VERSION ""

NS_ :

BS_:

BU_: WCM4 WCM3 WCM2 WCM VPM VLM VKM VICM VECM VDM VCU_RTOS_ETH VCU_ENTRY_ETH VCU_AGVM_ETH VCU UVM UPM TIM TEST_TOOL_1 TCP_ETH TCP TCM TCCM SRR_SRR_ETH SRR_SRR SRR_SLR_ETH SRR_SLR SRR_RR SRR_RF_ETH SRR_RF SRR_LR_CR SRR_LF_ETH SRR_LF SIB SDM SCL SBZA_R SBZA_L SBM SAM_RR SAM_RF SAM_LR SAM_LF SAM_BH SADS RadioLow_ETH RadioLow RSI_RTOS_ETH RSI RDCM PTM PLCM PFCM PDR_ETH PDR PCM PA ODS2 ODS NVM MTCM_R MTCM_L MSM_RR MSM_P MSM_LR MSM_D MSB2 MSB1 MRCM_R MRCM_L MFC LRR_RR_ETH LRR_LR_ETH LRR_CF_ETH LRR LRL_CF_ETH LIB_48V LIB1 IPC_INT IPC_GP IPC ICS_Info ICCM HVAC_FP_R HVAC_FP_F HUD_CAN HDLM FPI_RTOS_ETH FPI FOPM FCM_LC FCM EPSb EPS_1 EPSRAb EPSRAa EPS EOCM_HC_Superset EOCM_HCP2 EOCM ELM ECP_X1 ECP_S2 ECP_S ECP_MC ECP_H3 ECP_H2 ECP_H1 ECP_E ECM EBCM DMS DEFC DCM CSM_ETH CSM_AV CSM CGM_OTA_ETH CGM BSM_MH BSM_HEV BSM BCM ARS ARB APA AOS AMP ALC AHS AHL_AFL ADIMb ADIMa ACP2_MCU

BO_ 1432 PDU_5206: 8 HVAC_FP_F
 SG_ HVACFCRTLR_LtLvlActv : 0|1@0+ (1,0) [0|1] "" Vector__XXX
 SG_ HVACFCRTLR_LtLvl : 7|7@0+ (1,-16) [-16|111] "" Vector__XXX
 SG_ HVACFCRTLR_RtLvl : 12|7@0+ (1,-16) [-16|111] "" Vector__XXX
 SG_ HVACFCRTLR_LtLvlChg : 15|3@0- (1,0) [-4|3] "" Vector__XXX
 SG_ HVACFCRTLR_RwVltg1 : 17|9@0+ (0.01,0) [0|5.11] "Volts" Vector__XXX
 SG_ HVACFCRTLR_RtLvlChg : 20|3@0- (1,0) [-4|3] "" Vector__XXX
 SG_ HVACFCRTLR_RtLvlActv : 21|1@0+ (1,0) [0|1] "" Vector__XXX
 SG_ HVACFCRTLR_RwVltg2 : 24|9@0+ (0.01,0) [0|5.11] "Volts" Vector__XXX
 SG_ HVACFCRL_RwVltg : 47|9@0+ (0.01,0) [0|5.11] "Volts" Vector__XXX
 SG_ RHVSLF_VntLvlChgUp : 48|1@0+ (1,0) [0|1] "" Vector__XXX
 SG_ RHVSLF_VntLvlChgDn : 49|1@0+ (1,0) [0|1] "" Vector__XXX
 SG_ RHVSLF_HtdCushBckLvlChgUp : 50|1@0+ (1,0) [0|1] "" Vector__XXX
 SG_ RHVSLF_HtdCushBckLvlChgDn : 51|1@0+ (1,0) [0|1] "" Vector__XXX
 SG_ RHVSLF_HtdBckLvlChgUp : 52|1@0+ (1,0) [0|1] "" Vector__XXX
 SG_ RHVSLF_HtdBckLvlChgDn : 53|1@0+ (1,0) [0|1] "" Vector__XXX
 SG_ HVACFCRL_SetChg : 54|1@0+ (1,0) [0|1] "" Vector__XXX
 SG_ VntStStckSwRF : 57|1@0+ (1,0) [0|1] "" Vector__XXX
 SG_ RHVSRF_VntLvlChgUp : 58|1@0+ (1,0) [0|1] "" Vector__XXX
 SG_ RHVSRF_VntLvlChgDn : 59|1@0+ (1,0) [0|1] "" Vector__XXX
 SG_ RHVSRF_HtdCushBckLvlChgUp : 60|1@0+ (1,0) [0|1] "" Vector__XXX
 SG_ RHVSRF_HtdCushBckLvlChgDn : 61|1@0+ (1,0) [0|1] "" Vector__XXX
 SG_ RHVSRF_HtdBckLvlChgUp : 62|1@0+ (1,0) [0|1] "" Vector__XXX
 SG_ RHVSRF_HtdBckLvlChgDn : 63|1@0+ (1,0) [0|1] "" Vector__XXX

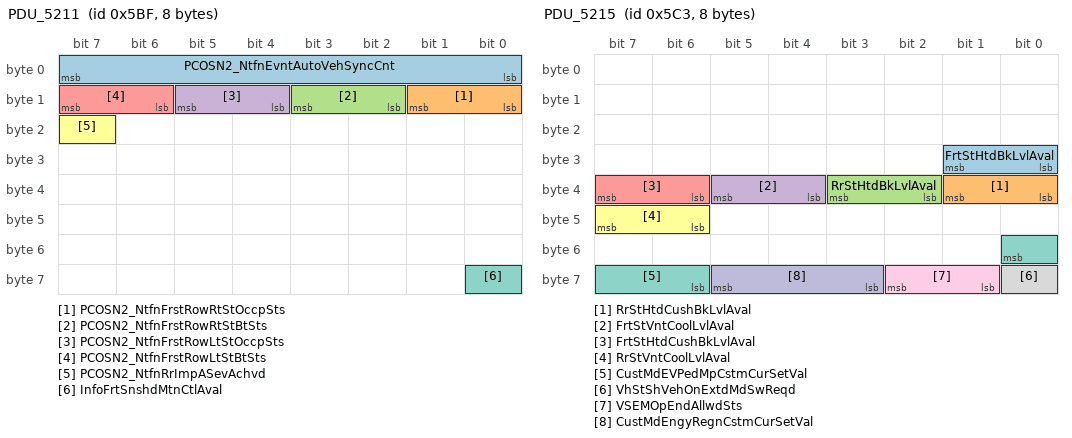
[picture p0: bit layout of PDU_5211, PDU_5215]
BO_ 1471 PDU_5211: 8 CGM
 SG_ PCOSN2_NtfnEvntAutoVehSyncCnt : 7|8@0+ (1,0) [0|255] "counts" TCP
 SG_ PCOSN2_NtfnFrstRowRtStOccpSts : 9|2@0+ (1,0) [0|3] "" TCP
 SG_ PCOSN2_NtfnFrstRowRtStBtSts : 11|2@0+ (1,0) [0|3] "" TCP
 SG_ PCOSN2_NtfnFrstRowLtStOccpSts : 13|2@0+ (1,0) [0|3] "" TCP
 SG_ PCOSN2_NtfnFrstRowLtStBtSts : 15|2@0+ (1,0) [0|3] "" TCP
 SG_ PCOSN2_NtfnRrImpASevAchvd : 23|1@0+ (1,0) [0|1] "" TCP
 SG_ InfoFrtSnshdMtnCtlAval : 56|1@0+ (1,0) [0|1] "" VCU

BO_ 1472 PDU_5212: 8 CGM
 SG_ CustMdEVPedMpCstmAvFlg1 : 56|1@0+ (1,0) [0|1] "" CSM,CSM_AV,VCU

BO_ 1474 PDU_5214: 8 CGM
 SG_ CustMdEVPedMpCstmAvFlg2 : 56|1@0+ (1,0) [0|1] "" CSM,CSM_AV,VCU

BO_ 1475 PDU_5215: 8 CGM
 SG_ FrtStHtdBkLvlAval : 25|2@0+ (1,0) [0|3] "" CSM,CSM_AV,VCU
 SG_ RrStHtdCushBkLvlAval : 33|2@0+ (1,0) [0|3] "" CSM,CSM_AV,VCU
 SG_ RrStHtdBkLvlAval : 35|2@0+ (1,0) [0|3] "" CSM,CSM_AV,VCU
 SG_ FrtStVntCoolLvlAval : 37|2@0+ (1,0) [0|3] "" CSM,CSM_AV,VCU
 SG_ FrtStHtdCushBkLvlAval : 39|2@0+ (1,0) [0|3] "" CSM,CSM_AV,VCU
 SG_ RrStVntCoolLvlAval : 47|2@0+ (1,0) [0|3] "" CSM,CSM_AV,VCU
 SG_ CustMdEVPedMpCstmCurSetVal : 48|3@0+ (1,0) [0|7] "" CSM,CSM_AV,VCU
 SG_ VhStShVehOnExtdMdSwReqd : 56|1@0+ (1,0) [0|1] "" VCU
 SG_ VSEMOpEndAllwdSts : 58|2@0+ (1,0) [0|2] "" VCU
 SG_ CustMdEngyRegnCstmCurSetVal : 61|3@0+ (1,0) [0|7] "" CSM,CSM_AV,VCU

BO_ 1476 PDU_5216: 8 CGM
 SG_ OffRdMdElecVehPedMpVisDispVal : 1|3@0+ (1,0) [0|7] "" CSM,CSM_AV,VCU
 SG_ PrsnlMdEngyRegnCstmCurSetVal : 8|3@0+ (1,0) [0|7] "" CSM,CSM_AV,VCU
 SG_ PrsnlMdEVPedMpCstmCurSetVal : 11|3@0+ (1,0) [0|7] "" CSM,CSM_AV,VCU
 SG_ OffRdMdEngyRegnVisDispVal : 14|3@0+ (1,0) [0|7] "" CSM,CSM_AV,VCU
 SG_ SprtMdEngyRegnVisDispVal : 18|3@0+ (1,0) [0|7] "" CSM,CSM_AV,VCU
 SG_ SprtMdElecVehPedMpVisDispVal : 21|3@0+ (1,0) [0|7] "" CSM,CSM_AV,VCU
 SG_ TourMdElecVehPedMpVisDispVal : 25|3@0+ (1,0) [0|7] "" CSM,CSM_AV,VCU
 SG_ TkMdEngyRegnVisDispVal : 28|3@0+ (1,0) [0|7] "" CSM,CSM_AV,VCU
 SG_ TkMdElecVehPedMpVisDispVal : 31|3@0+ (1,0) [0|7] "" CSM,CSM_AV,VCU
 SG_ TrnMdBrkPedVisDispVal : 32|3@0+ (1,0) [0|7] "" CSM,CSM_AV,VCU
 SG_ TrnMdActvAerodynsVisDispVal : 35|3@0+ (1,0) [0|7] "" CSM,CSM_AV,VCU
 SG_ TourMdEngyRegnVisDispVal : 38|3@0+ (1,0) [0|7] "" CSM,CSM_AV,VCU
 SG_ TrnMdESCVisDispVal : 42|3@0+ (1,0) [0|7] "" CSM,CSM_AV,VCU
 SG_ TrnMdDrvlnVisDispVal : 45|3@0+ (1,0) [0|7] "" CSM,CSM_AV,VCU
 SG_ TrnMdPwrtrnVisDispVal : 49|3@0+ (1,0) [0|7] "" CSM,CSM_AV,VCU
 SG_ TrnMdEngyRegnVisDispVal : 52|3@0+ (1,0) [0|7] "" CSM,CSM_AV,VCU
 SG_ TrnMdElecVehPedMpVisDispVal : 55|3@0+ (1,0) [0|7] "" CSM,CSM_AV,VCU
 SG_ CustMdEVPedMpCstmAvFlg3 : 56|1@0+ (1,0) [0|1] "" CSM,CSM_AV,VCU
 SG_ TrnMdSndVisDispVal : 59|3@0+ (1,0) [0|7] "" CSM,CSM_AV,VCU
 SG_ TrnMdRideHghtVisDispVal : 62|3@0+ (1,0) [0|7] "" CSM,CSM_AV,VCU

BO_ 1477 PDU_5217: 8 CGM
 SG_ TrnMdStrgVisDispVal : 4|3@0+ (1,0) [0|7] "" CSM,CSM_AV,VCU
 SG_ TrnMdSpnsnVisDispVal : 7|3@0+ (1,0) [0|7] "" CSM,CSM_AV,VCU
 SG_ WthrMdEngyRegnVisDispVal : 11|3@0+ (1,0) [0|7] "" CSM,CSM_AV,VCU
 SG_ WthrMdElecVehPedMpVisDispVal : 14|3@0+ (1,0) [0|7] "" CSM,CSM_AV,VCU
 SG_ CustMdEVPedMpCstmAvFlg4 : 16|1@0+ (1,0) [0|1] "" CSM,CSM_AV,VCU
 SG_ HtdStrgWhlLvlAval : 22|2@0+ (1,0) [0|3] "" CSM,CSM_AV,VCU
 SG_ CustMdEngyRegnCstmAvFlg4 : 24|1@0+ (1,0) [0|1] "" CSM,CSM_AV,VCU
 SG_ CustMdEngyRegnCstmAvFlg3 : 25|1@0+ (1,0) [0|1] "" CSM,CSM_AV,VCU
 SG_ CustMdEngyRegnCstmAvFlg2 : 26|1@0+ (1,0) [0|1] "" CSM,CSM_AV,VCU
 SG_ CustMdEngyRegnCstmAvFlg1 : 27|1@0+ (1,0) [0|1] "" CSM,CSM_AV,VCU
 SG_ CustMdEVPedMpCstmSetAv : 28|1@0+ (1,0) [0|1] "" CSM,CSM_AV,VCU
 SG_ CustMdEVPedMpCstmAvFlg7 : 29|1@0+ (1,0) [0|1] "" CSM,CSM_AV,VCU
 SG_ CustMdEVPedMpCstmAvFlg6 : 30|1@0+ (1,0) [0|1] "" CSM,CSM_AV,VCU
 SG_ CustMdEVPedMpCstmAvFlg5 : 31|1@0+ (1,0) [0|1] "" CSM,CSM_AV,VCU
 SG_ OnePedDrvCstSetAllwdFlg3 : 32|1@0+ (1,0) [0|1] "" CSM,CSM_AV,VCU
 SG_ OnePedDrvCstSetAllwdFlg2 : 33|1@0+ (1,0) [0|1] "" CSM,CSM_AV,VCU
 SG_ OnePedDrvCstSetAllwdFlg1 : 34|1@0+ (1,0) [0|1] "" CSM,CSM_AV,VCU
 SG_ CustMdEngyRegnCstmSetAv : 36|1@0+ (1,0) [0|1] "" CSM,CSM_AV,VCU
 SG_ CustMdEngyRegnCstmAvFlg7 : 37|1@0+ (1,0) [0|1] "" CSM,CSM_AV,VCU
 SG_ CustMdEngyRegnCstmAvFlg6 : 38|1@0+ (1,0) [0|1] "" CSM,CSM_AV,VCU
 SG_ CustMdEngyRegnCstmAvFlg5 : 39|1@0+ (1,0) [0|1] "" CSM,CSM_AV,VCU
 SG_ OnePedDrvCstSetAvlFlg3 : 40|1@0+ (1,0) [0|1] "" CSM,CSM_AV,VCU
 SG_ OnePedDrvCstSetAvlFlg2 : 41|1@0+ (1,0) [0|1] "" CSM,CSM_AV,VCU
 SG_ OnePedDrvCstSetAvlFlg1 : 42|1@0+ (1,0) [0|1] "" CSM,CSM_AV,VCU
 SG_ OnePedDrvCstSetAval : 43|1@0+ (1,0) [0|1] "" CSM,CSM_AV,VCU
 SG_ OnePedDrvCstSetAllwdFlg7 : 44|1@0+ (1,0) [0|1] "" CSM,CSM_AV,VCU
 SG_ OnePedDrvCstSetAllwdFlg6 : 45|1@0+ (1,0) [0|1] "" CSM,CSM_AV,VCU
 SG_ OnePedDrvCstSetAllwdFlg5 : 46|1@0+ (1,0) [0|1] "" CSM,CSM_AV,VCU
 SG_ OnePedDrvCstSetAllwdFlg4 : 47|1@0+ (1,0) [0|1] "" CSM,CSM_AV,VCU
 SG_ PrsnlMdEVPedMpCstmAvFlg3 : 48|1@0+ (1,0) [0|1] "" CSM,CSM_AV,VCU
 SG_ PrsnlMdEVPedMpCstmAvFlg2 : 49|1@0+ (1,0) [0|1] "" CSM,CSM_AV,VCU
 SG_ PrsnlMdEVPedMpCstmAvFlg1 : 50|1@0+ (1,0) [0|1] "" CSM,CSM_AV,VCU
 SG_ OnePedDrvCstSetAvlFlg7 : 52|1@0+ (1,0) [0|1] "" CSM,CSM_AV,VCU
 SG_ OnePedDrvCstSetAvlFlg6 : 53|1@0+ (1,0) [0|1] "" CSM,CSM_AV,VCU
 SG_ OnePedDrvCstSetAvlFlg5 : 54|1@0+ (1,0) [0|1] "" CSM,CSM_AV,VCU
 SG_ OnePedDrvCstSetAvlFlg4 : 55|1@0+ (1,0) [0|1] "" CSM,CSM_AV,VCU
 SG_ PrsnlMdEngyRegnCstmAvFlg3 : 56|1@0+ (1,0) [0|1] "" CSM,CSM_AV,VCU
 SG_ PrsnlMdEngyRegnCstmAvFlg2 : 57|1@0+ (1,0) [0|1] "" CSM,CSM_AV,VCU
 SG_ PrsnlMdEngyRegnCstmAvFlg1 : 58|1@0+ (1,0) [0|1] "" CSM,CSM_AV,VCU
 SG_ PrsnlMdEVPedMpCstmSetAv : 59|1@0+ (1,0) [0|1] "" CSM,CSM_AV,VCU
 SG_ PrsnlMdEVPedMpCstmAvFlg7 : 60|1@0+ (1,0) [0|1] "" CSM,CSM_AV,VCU
 SG_ PrsnlMdEVPedMpCstmAvFlg6 : 61|1@0+ (1,0) [0|1] "" CSM,CSM_AV,VCU
 SG_ PrsnlMdEVPedMpCstmAvFlg5 : 62|1@0+ (1,0) [0|1] "" CSM,CSM_AV,VCU
 SG_ PrsnlMdEVPedMpCstmAvFlg4 : 63|1@0+ (1,0) [0|1] "" CSM,CSM_AV,VCU

BO_ 1496 PDU_5218: 6 CGM
 SG_ PwrFrtStrgeCmptClsrCstAvlFlg2 : 0|1@0+ (1,0) [0|1] "" RadioLow,CSM,CSM_AV,VCU
 SG_ PwrFrtStrgeCmptClsrCstAvlFlg1 : 1|1@0+ (1,0) [0|1] "" RadioLow,CSM,CSM_AV,VCU
 SG_ PrsnlMdEngyRegnCstmSetAv : 3|1@0+ (1,0) [0|1] "" CSM,CSM_AV,VCU
 SG_ PrsnlMdEngyRegnCstmAvFlg7 : 4|1@0+ (1,0) [0|1] "" CSM,CSM_AV,VCU
 SG_ PrsnlMdEngyRegnCstmAvFlg6 : 5|1@0+ (1,0) [0|1] "" CSM,CSM_AV,VCU
 SG_ PrsnlMdEngyRegnCstmAvFlg5 : 6|1@0+ (1,0) [0|1] "" CSM,CSM_AV,VCU
 SG_ PrsnlMdEngyRegnCstmAvFlg4 : 7|1@0+ (1,0) [0|1] "" CSM,CSM_AV,VCU
 SG_ VirtCtlAccCktCtlAval : 8|1@0+ (1,0) [0|1] "" CSM,CSM_AV,VCU
 SG_ PwrFrtStrgeCmptClsrCstSetAval : 10|1@0+ (1,0) [0|1] "" RadioLow,CSM,CSM_AV,VCU
 SG_ PwrFrtStrgeCmptClsrCstAvlFlg7 : 11|1@0+ (1,0) [0|1] "" RadioLow,CSM,CSM_AV,VCU
 SG_ PwrFrtStrgeCmptClsrCstAvlFlg6 : 12|1@0+ (1,0) [0|1] "" RadioLow,CSM,CSM_AV,VCU
 SG_ PwrFrtStrgeCmptClsrCstAvlFlg5 : 13|1@0+ (1,0) [0|1] "" RadioLow,CSM,CSM_AV,VCU
 SG_ PwrFrtStrgeCmptClsrCstAvlFlg4 : 14|1@0+ (1,0) [0|1] "" RadioLow,CSM,CSM_AV,VCU
 SG_ PwrFrtStrgeCmptClsrCstAvlFlg3 : 15|1@0+ (1,0) [0|1] "" RadioLow,CSM,CSM_AV,VCU
 SG_ VirtOnePedDrvUserCtlAllwd : 21|1@0+ (1,0) [0|1] "" CSM,CSM_AV,VCU
 SG_ VirtOnePedDrvCtlAval : 22|1@0+ (1,0) [0|1] "" CSM,CSM_AV,VCU
 SG_ VirtCtlAuxAlrmSnsCtlAval : 23|1@0+ (1,0) [0|1] "" CSM,VCU
 SG_ HdOpnShftrLckdHldBrkTmVal : 31|6@0+ (1,0) [0|63] "s" IPC,IPC_INT,VCU

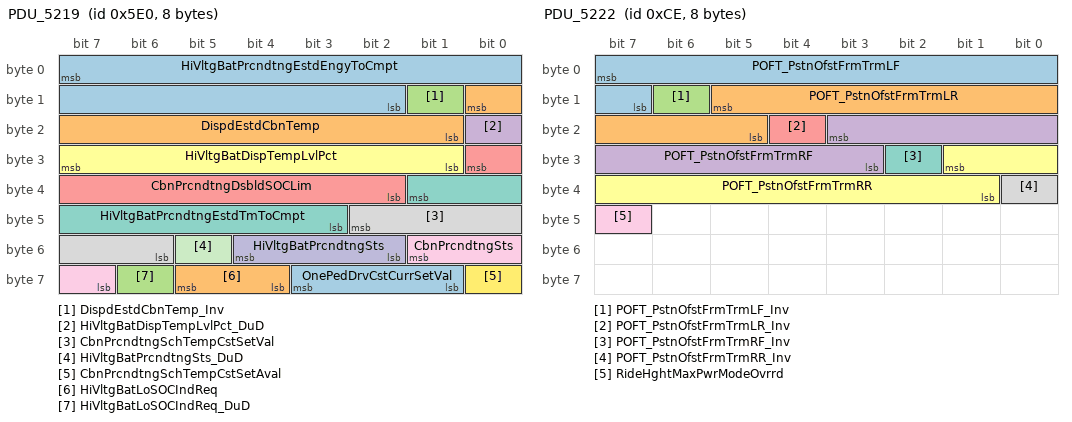
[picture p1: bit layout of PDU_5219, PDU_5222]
BO_ 1504 PDU_5219: 8 CGM
 SG_ HiVltgBatPrcndtngEstdEngyToCmpt : 7|14@0+ (0.01,0) [0|163.83] "kWh" CSM,CSM_AV,VCU
 SG_ DispdEstdCbnTemp : 8|8@0+ (0.5,-40) [-40|87.5] "Deg C" TCP,VCU
 SG_ DispdEstdCbnTemp_Inv : 9|1@0+ (1,0) [0|1] "" TCP,VCU
 SG_ HiVltgBatDispTempLvlPct_DuD : 16|1@0+ (1,0) [0|1] "" CSM,CSM_AV,IPC,IPC_INT,VCU
 SG_ CbnPrcndtngDsbldSOCLim : 24|7@0+ (1,0) [0|127] "%" CSM,CSM_AV,VCU
 SG_ HiVltgBatDispTempLvlPct : 31|7@0+ (1,0) [0|127] "%" CSM,CSM_AV,IPC,IPC_INT,VCU
 SG_ HiVltgBatPrcndtngEstdTmToCmpt : 33|7@0+ (1,0) [0|127] "min" CSM,CSM_AV,VCU
 SG_ CbnPrcndtngSchTempCstSetVal : 42|5@0+ (0.5,16) [16|31.5] "Deg C" CSM,CSM_AV,VCU
 SG_ CbnPrcndtngSts : 49|3@0+ (1,0) [0|5] "" TCP,VKM
 SG_ HiVltgBatPrcndtngSts : 52|3@0+ (1,0) [0|5] "" TCP,CSM,CSM_AV,VCU
 SG_ HiVltgBatPrcndtngSts_DuD : 53|1@0+ (1,0) [0|1] "" TCP,CSM,CSM_AV,VCU
 SG_ CbnPrcndtngSchTempCstSetAval : 56|1@0+ (1,0) [0|1] "" CSM,CSM_AV,VCU
 SG_ OnePedDrvCstCurrSetVal : 59|3@0+ (1,0) [0|4] "" CSM,CSM_AV,VCU
 SG_ HiVltgBatLoSOCIndReq : 61|2@0+ (1,0) [0|3] "" TCP
 SG_ HiVltgBatLoSOCIndReq_DuD : 62|1@0+ (1,0) [0|1] "" TCP

BO_ 1505 PDU_5220: 6 CGM
 SG_ OnePedDrvCurrSeltnVal : 0|2@0+ (1,0) [0|2] "" CSM,CSM_AV,VCU
 SG_ FrtStrgeCmptClsrLckSts : 2|2@0+ (1,0) [0|2] "" TCP
 SG_ AuxAlrmSnsCurrSeltnVal : 4|2@0+ (1,0) [0|2] "" CSM,VCU
 SG_ PwrFrtStrgeCmptClsrCstCurSetVal : 7|3@0+ (1,0) [0|3] "" RadioLow,VKM,CSM,CSM_AV,VCU
 SG_ VirtCtlAccCkt3CurrSeltnVal : 8|2@0+ (1,0) [0|3] "" CSM,CSM_AV,VCU
 SG_ VirtCtlAccCkt2CurrSeltnVal : 10|2@0+ (1,0) [0|3] "" CSM,CSM_AV,VCU
 SG_ VirtCtlAccCkt1CurrSeltnVal : 12|2@0+ (1,0) [0|3] "" CSM,CSM_AV,VCU
 SG_ OnePedDrvWrnIndReq : 14|2@0+ (1,0) [0|1] "" IPC,IPC_INT,VCU
 SG_ HVDCFstChrgPerfLtdIndOn : 16|1@0+ (1,0) [0|1] "" CSM,CSM_AV,VCU
 SG_ VirtCtlAccCkt6CurrSeltnVal : 18|2@0+ (1,0) [0|3] "" CSM,CSM_AV,VCU
 SG_ VirtCtlAccCkt5CurrSeltnVal : 20|2@0+ (1,0) [0|3] "" CSM,CSM_AV,VCU
 SG_ VirtCtlAccCkt4CurrSeltnVal : 22|2@0+ (1,0) [0|3] "" CSM,CSM_AV,VCU
 SG_ LnchCtlBrkPresHiResVal : 29|7@0+ (1,0) [0|127] "%" IPC,IPC_INT,VCU
 SG_ OnePedDrvIndOn : 30|1@0+ (1,0) [0|1] "" IPC,IPC_INT,VCU
 SG_ HVDCFstChrgPrepCmpltIndOn : 31|1@0+ (1,0) [0|1] "" CSM,CSM_AV,VCU
 SG_ ADASLtdCpbltyStatRsnIndReq : 35|5@0+ (1,0) [0|11] "" IPC,IPC_INT,VCU
 SG_ PrplSysMaxPwrModeUnvRsn : 38|3@0+ (1,0) [0|7] "" IPC,IPC_INT,VCU
 SG_ ADASMsgDispLocLtdPerfRsnInd : 42|3@0+ (1,0) [0|3] "" IPC,IPC_INT,VCU
 SG_ ADASLtdCpbltyStatIndReq : 46|4@0+ (1,0) [0|6] "" IPC,IPC_INT,VCU

BO_ 929 PDU_5221: 6 CGM
 SG_ B2RChmEvntStat : 7|2@0+ (1,0) [0|2] "" IPC,IPC_INT,VCU

BO_ 206 PDU_5222: 8 CGM
 SG_ POFT_PstnOfstFrmTrmLF : 7|9@0- (1,0) [-256|255] "mm" PDR,CSM,CSM_AV,IPC,IPC_INT,VCU
 SG_ POFT_PstnOfstFrmTrmLR : 13|9@0- (1,0) [-256|255] "mm" PDR,CSM,CSM_AV,IPC,IPC_INT,VCU
 SG_ POFT_PstnOfstFrmTrmLF_Inv : 14|1@0+ (1,0) [0|1] "" CSM,CSM_AV,IPC,IPC_INT,VCU
 SG_ POFT_PstnOfstFrmTrmRF : 19|9@0- (1,0) [-256|255] "mm" PDR,CSM,CSM_AV,IPC,IPC_INT,VCU
 SG_ POFT_PstnOfstFrmTrmLR_Inv : 20|1@0+ (1,0) [0|1] "" CSM,CSM_AV,IPC,IPC_INT,VCU
 SG_ POFT_PstnOfstFrmTrmRR : 25|9@0- (1,0) [-256|255] "mm" PDR,CSM,CSM_AV,IPC,IPC_INT,VCU
 SG_ POFT_PstnOfstFrmTrmRF_Inv : 26|1@0+ (1,0) [0|1] "" CSM,CSM_AV,IPC,IPC_INT,VCU
 SG_ POFT_PstnOfstFrmTrmRR_Inv : 32|1@0+ (1,0) [0|1] "" CSM,CSM_AV,IPC,IPC_INT,VCU
 SG_ RideHghtMaxPwrModeOvrrd : 47|1@0+ (1,0) [0|1] "" IPC,IPC_INT,VCU

BO_ 1535 PDU_5223: 6 RadioLow
 SG_ PwrFrtStrgeCmptClsrCstChgSetReq : 7|3@0+ (1,0) [0|3] "" CGM

BO_ 1246 PDU_5224: 8 CSM
 SG_ ElecRateSchedSsnStrtMthReq : 0|4@0+ (1,0) [0|12] "" CGM
 SG_ ElecRateSchedSsnStrtDyReq : 5|5@0+ (1,0) [0|31] "day" CGM
 SG_ ElecRateSchedSsnReq : 7|2@0+ (1,0) [0|3] "" CGM
 SG_ InfoFrtLtStHtdCushBkLvlReq : 9|3@0+ (1,0) [0|5] "" CGM
 SG_ InfoFrtLtStHtdBkLvlReq : 12|3@0+ (1,0) [0|5] "" CGM
 SG_ InfoFrtRtStHtdCushBkLvlReq : 16|3@0+ (1,0) [0|5] "" CGM
 SG_ InfoFrtRtStHtdBkLvlReq : 19|3@0+ (1,0) [0|5] "" CGM
 SG_ InfoFrtLtStVntCoolLvlReq : 22|3@0+ (1,0) [0|5] "" CGM
 SG_ InfoRrLtStHtdBkLvlReq : 26|3@0+ (1,0) [0|5] "" CGM
 SG_ InfoFrtRtStVntCoolLvlReq : 29|3@0+ (1,0) [0|5] "" CGM
 SG_ InfoRrRtStHtdBkLvlReq : 33|3@0+ (1,0) [0|5] "" CGM
 SG_ InfoRrLtStVntCoolLvlReq : 36|3@0+ (1,0) [0|5] "" CGM
 SG_ InfoRrLtStHtdCushBkLvlReq : 39|3@0+ (1,0) [0|5] "" CGM
 SG_ CbnPrcndtngSchTempCstSetReq : 40|5@0+ (0.5,16) [16|31.5] "Deg C" CGM
 SG_ InfoRrRtStVntCoolLvlReq : 43|3@0+ (1,0) [0|5] "" CGM
 SG_ InfoRrRtStHtdCushBkLvlReq : 46|3@0+ (1,0) [0|5] "" CGM
 SG_ OnePedDrvCstChgSetReq : 48|3@0+ (1,0) [0|4] "" CGM
 SG_ InfoHtdStrgWhlLvlReq : 51|3@0+ (1,0) [0|5] "" CGM
 SG_ VirtCtlAccCkt2Req : 58|3@0+ (1,0) [0|5] "" CGM
 SG_ VirtCtlAccCkt1Req : 61|3@0+ (1,0) [0|5] "" CGM

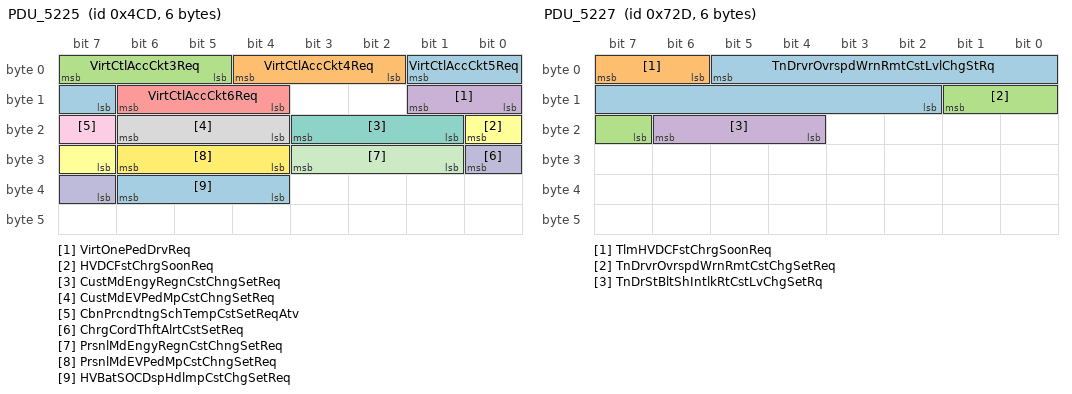
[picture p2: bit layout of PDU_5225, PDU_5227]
BO_ 1229 PDU_5225: 6 CSM
 SG_ VirtCtlAccCkt5Req : 1|3@0+ (1,0) [0|5] "" CGM
 SG_ VirtCtlAccCkt4Req : 4|3@0+ (1,0) [0|5] "" CGM
 SG_ VirtCtlAccCkt3Req : 7|3@0+ (1,0) [0|5] "" CGM
 SG_ VirtOnePedDrvReq : 9|2@0+ (1,0) [0|2] "" CGM
 SG_ VirtCtlAccCkt6Req : 14|3@0+ (1,0) [0|5] "" CGM
 SG_ HVDCFstChrgSoonReq : 16|2@0+ (1,0) [0|2] "" CGM
 SG_ CustMdEngyRegnCstChngSetReq : 19|3@0+ (1,0) [0|7] "" CGM
 SG_ CustMdEVPedMpCstChngSetReq : 22|3@0+ (1,0) [0|7] "" CGM
 SG_ CbnPrcndtngSchTempCstSetReqAtv : 23|1@0+ (1,0) [0|1] "" CGM
 SG_ ChrgCordThftAlrtCstSetReq : 24|2@0+ (1,0) [0|2] "" CGM
 SG_ PrsnlMdEngyRegnCstChngSetReq : 27|3@0+ (1,0) [0|7] "" CGM
 SG_ PrsnlMdEVPedMpCstChngSetReq : 30|3@0+ (1,0) [0|7] "" CGM
 SG_ HVBatSOCDspHdlmpCstChgSetReq : 38|3@0+ (1,0) [0|2] "" CGM

BO_ 931 PDU_5226: 6 TCP
 SG_ RmtVehStrtPwrtrnFlrRsn : 2|5@0+ (1,0) [0|16] "" VKM
 SG_ RmtVehStrtBdyFlrRsn : 7|5@0+ (1,0) [0|14] "" VKM

BO_ 1837 PDU_5227: 6 TCP
 SG_ TnDrvrOvrspdWrnRmtCstLvlChgStRq : 5|12@0+ (0.0625,0) [0|255.938] "km/h" CGM
 SG_ TlmHVDCFstChrgSoonReq : 7|2@0+ (1,0) [0|2] "" CGM
 SG_ TnDrvrOvrspdWrnRmtCstChgSetReq : 9|3@0+ (1,0) [0|2] "" CGM
 SG_ TnDrStBltShIntlkRtCstLvChgSetRq : 22|3@0+ (1,0) [0|2] "" CGM

BO_ 940 PDU_5230: 6 VKM
 SG_ VirtKeyCmdFailRsnReq : 7|2@0+ (1,0) [0|1] "" TCP

BO_ 1467 PDU_5238: 6 TCP
 SG_ SuprCruzSbscrptnActv : 7|1@0+ (1,0) [0|1] "" CGM

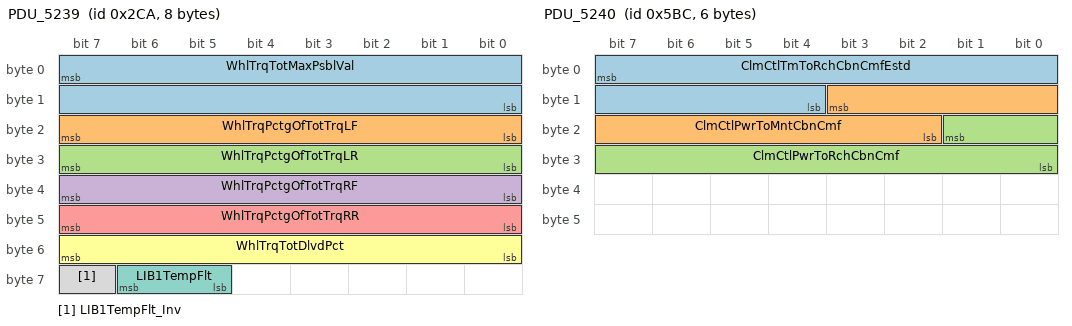
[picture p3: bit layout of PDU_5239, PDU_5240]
BO_ 714 PDU_5239: 8 CGM
 SG_ WhlTrqTotMaxPsblVal : 7|16@0+ (1,0) [0|65535] "Nm" IPC,IPC_INT,VCU
 SG_ WhlTrqPctgOfTotTrqLF : 23|8@0- (0.788235,0) [-100.894|100.106] "%" CSM,CSM_AV,VCU
 SG_ WhlTrqPctgOfTotTrqLR : 31|8@0- (0.788235,0) [-100.894|100.106] "%" CSM,CSM_AV,VCU
 SG_ WhlTrqPctgOfTotTrqRF : 39|8@0- (0.788235,0) [-100.894|100.106] "%" CSM,CSM_AV,VCU
 SG_ WhlTrqPctgOfTotTrqRR : 47|8@0- (0.788235,0) [-100.894|100.106] "%" CSM,CSM_AV,VCU
 SG_ WhlTrqTotDlvdPct : 55|8@0- (0.788235,0) [-100.894|100.106] "%" CSM,CSM_AV,IPC,IPC_INT,VCU
 SG_ LIB1TempFlt : 62|2@0+ (1,0) [0|3] "" CSM,VCU
 SG_ LIB1TempFlt_Inv : 63|1@0+ (1,0) [0|1] "" CSM,VCU

BO_ 1468 PDU_5240: 6 CGM
 SG_ ClmCtlTmToRchCbnCmfEstd : 7|12@0+ (1,0) [0|4095] "sec" CSM,CSM_AV,VCU
 SG_ ClmCtlPwrToMntCbnCmf : 11|10@0+ (0.1,0) [0|102.3] "KW" CSM,CSM_AV,VCU
 SG_ ClmCtlPwrToRchCbnCmf : 17|10@0+ (0.1,0) [0|102.3] "KW" CSM,CSM_AV,VCU

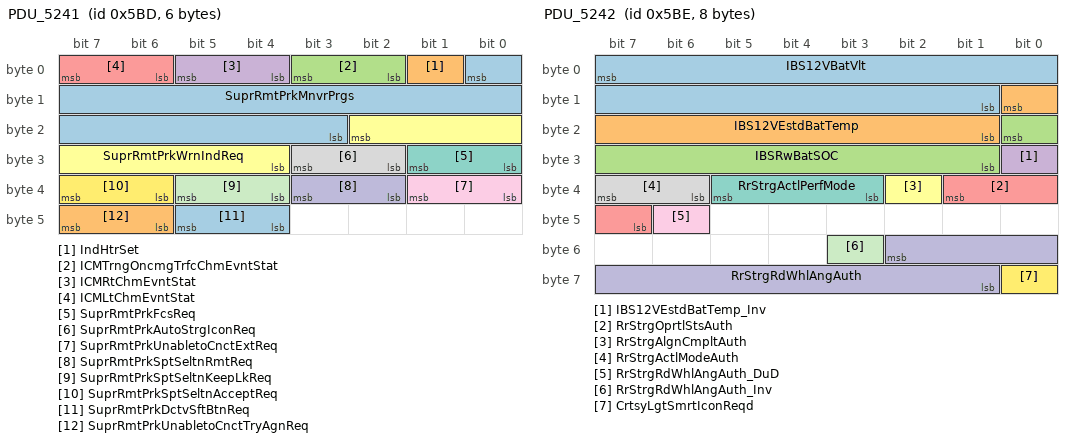
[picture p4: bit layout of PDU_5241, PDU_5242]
BO_ 1469 PDU_5241: 6 CGM
 SG_ SuprRmtPrkMnvrPrgs : 0|14@0+ (0.01,0) [0|163.83] "" VKM,VCU
 SG_ IndHtrSet : 1|1@0+ (1,0) [0|1] "" HVAC_FP_F,RadioLow,CSM,CSM_AV,VCU
 SG_ ICMTrngOncmgTrfcChmEvntStat : 3|2@0+ (1,0) [0|2] "" IPC,IPC_INT,VCU
 SG_ ICMRtChmEvntStat : 5|2@0+ (1,0) [0|2] "" IPC,IPC_INT,VCU
 SG_ ICMLtChmEvntStat : 7|2@0+ (1,0) [0|2] "" IPC,IPC_INT,VCU
 SG_ SuprRmtPrkWrnIndReq : 18|7@0+ (1,0) [0|70] "" VKM,VCU
 SG_ SuprRmtPrkFcsReq : 25|2@0+ (1,0) [0|3] "" VCU
 SG_ SuprRmtPrkAutoStrgIconReq : 27|2@0+ (1,0) [0|2] "" VKM,VCU
 SG_ SuprRmtPrkUnabletoCnctExtReq : 33|2@0+ (1,0) [0|3] "" VCU
 SG_ SuprRmtPrkSptSeltnRmtReq : 35|2@0+ (1,0) [0|3] "" VCU
 SG_ SuprRmtPrkSptSeltnKeepLkReq : 37|2@0+ (1,0) [0|3] "" VCU
 SG_ SuprRmtPrkSptSeltnAcceptReq : 39|2@0+ (1,0) [0|3] "" VCU
 SG_ SuprRmtPrkDctvSftBtnReq : 45|2@0+ (1,0) [0|3] "" VCU
 SG_ SuprRmtPrkUnabletoCnctTryAgnReq : 47|2@0+ (1,0) [0|3] "" VCU

BO_ 1470 PDU_5242: 8 CGM
 SG_ IBS12VBatVlt : 7|15@0+ (0.001,0) [0|32.767] "" TCP
 SG_ IBS12VEstdBatTemp : 8|8@0+ (1,-40) [-40|215] "Degree C" TCP,CSM,CSM_AV,VCU
 SG_ IBSRwBatSOC : 16|8@0+ (0.39,0) [0|99.45] "%" TCP,CSM,CSM_AV,VCU
 SG_ IBS12VEstdBatTemp_Inv : 24|1@0+ (1,0) [0|1] "" CSM,CSM_AV,VCU
 SG_ RrStrgOprtlStsAuth : 33|3@0+ (1,0) [0|6] "" VCU
 SG_ RrStrgAlgnCmpltAuth : 34|1@0+ (1,0) [0|1] "" VCU
 SG_ RrStrgActlPerfMode : 37|3@0+ (1,0) [0|7] "" VCU
 SG_ RrStrgActlModeAuth : 39|2@0+ (1,0) [0|3] "" VCU
 SG_ RrStrgRdWhlAngAuth_DuD : 46|1@0+ (1,0) [0|1] "" VCU
 SG_ RrStrgRdWhlAngAuth : 50|10@0- (0.0625,0) [-32|31.9375] "deg" CSM,CSM_AV,IPC,IPC_INT,VCU
 SG_ RrStrgRdWhlAngAuth_Inv : 51|1@0+ (1,0) [0|1] "" CSM,CSM_AV,IPC,IPC_INT,VCU
 SG_ CrtsyLgtSmrtIconReqd : 56|1@0+ (1,0) [0|1] "" VCU

BO_ 1473 PDU_5243: 8 CGM
 SG_ ActvTrlrProfLifetmEcon : 7|15@0- (0.1,0) [-1638.4|1638.3] "" CSM,CSM_AV,VCU
 SG_ ActvTrlrProfLifetmEcon_DuD : 8|1@0+ (1,0) [0|1] "" CSM,CSM_AV,VCU
 SG_ PnCStsDisp : 22|8@0+ (1,0) [0|8] "" CSM,CSM_AV,IPC,IPC_INT,VCU
 SG_ ActvTrlrProfLifetmEcon_Inv : 23|1@0+ (1,0) [0|1] "" CSM,CSM_AV,VCU
 SG_ PTExPrtclFltrMnlRgnSts : 24|3@0+ (1,0) [0|7] "" IPC,IPC_INT,VCU
 SG_ ICMWrnIndReq : 27|3@0+ (1,0) [0|3] "" IPC,IPC_INT,VCU
 SG_ EngAftRunIndReq : 30|3@0+ (1,0) [0|4] "" IPC,IPC_INT,VCU
 SG_ PnCEnbldSts : 32|2@0+ (1,0) [0|2] "" CSM,CSM_AV,VCU
 SG_ AutoCoolServFllIndReq : 34|2@0+ (1,0) [0|3] "" IPC,IPC_INT,VCU
 SG_ RrStrgModeUnvIndReq : 37|3@0+ (1,0) [0|6] "" IPC,IPC_INT,VCU
 SG_ PwrFrtStrgeCmptMtnSts : 42|4@0+ (1,0) [0|12] "" VKM,VCU
 SG_ RrStrgModeSeltnIndOn : 43|1@0+ (1,0) [0|1] "" IPC,IPC_INT,VCU
 SG_ PTExPrtclFltrWrn3IndOn : 44|1@0+ (1,0) [0|1] "" IPC,IPC_INT,VCU
 SG_ HdLmpSmrtCtlPrmtReqd : 45|1@0+ (1,0) [0|1] "" VCU
 SG_ ESCUnvTopDnIndOn : 46|1@0+ (1,0) [0|1] "" IPC,IPC_INT,VCU
 SG_ LnchCtlAccelPedVal : 50|7@0+ (1,0) [0|127] "%" IPC,IPC_INT,VCU
 SG_ RIMObjAtchdIndOn : 51|1@0+ (1,0) [0|1] "" IPC,IPC_INT,VCU
 SG_ RIMElecPrkBrkRelIndOn : 52|1@0+ (1,0) [0|1] "" IPC,IPC_INT,VCU
 SG_ UpftrVehStrtEnblIndReq : 54|2@0+ (1,0) [0|3] "" IPC,IPC_INT,VCU
 SG_ MaxPwrModeDndIndOn : 56|1@0+ (1,0) [0|1] "" IPC,IPC_INT,VCU
 SG_ DrvModeConfIndReq : 59|3@0+ (1,0) [0|7] "" CSM,CSM_AV,IPC,IPC_INT,VCU

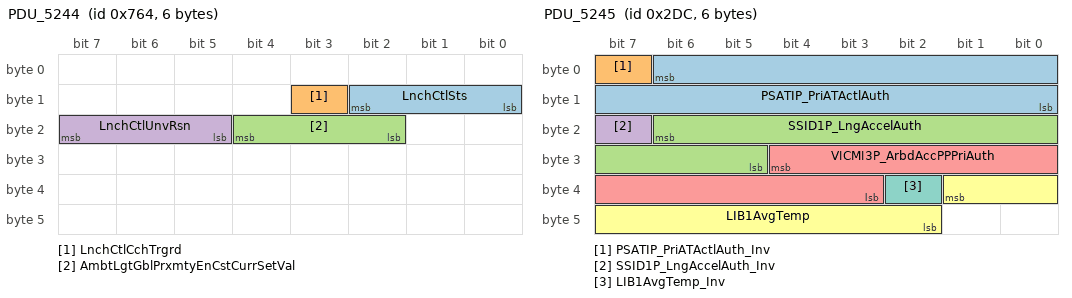
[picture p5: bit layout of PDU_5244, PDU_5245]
BO_ 1892 PDU_5244: 6 CGM
 SG_ LnchCtlSts : 10|3@0+ (1,0) [0|7] "" IPC,IPC_INT,VCU
 SG_ LnchCtlCchTrgrd : 11|1@0+ (1,0) [0|1] "" IPC,IPC_INT,VCU
 SG_ AmbtLgtGblPrxmtyEnCstCurrSetVal : 20|3@0+ (1,0) [0|2] "" VCU
 SG_ LnchCtlUnvRsn : 23|3@0+ (1,0) [0|7] "" IPC,IPC_INT,VCU

BO_ 732 PDU_5245: 6 CGM
 SG_ PSATIP_PriATActlAuth : 6|15@0+ (2,-22534) [-22534|43000] "Nm" CSM,CSM_AV,VCU
 SG_ PSATIP_PriATActlAuth_Inv : 7|1@0+ (1,0) [0|1] "" CSM,CSM_AV,VCU
 SG_ SSID1P_LngAccelAuth : 22|10@0- (0.0625,0) [-32|31.9375] "m/s2" VKM
 SG_ SSID1P_LngAccelAuth_Inv : 23|1@0+ (1,0) [0|1] "" VKM
 SG_ VICMI3P_ArbdAccPPPriAuth : 28|10@0+ (0.0976563,0) [0|99.9023] "%" VKM
 SG_ LIB1AvgTemp : 33|8@0+ (1,-40) [-40|215] "C" CSM,VCU
 SG_ LIB1AvgTemp_Inv : 34|1@0+ (1,0) [0|1] "" CSM,VCU

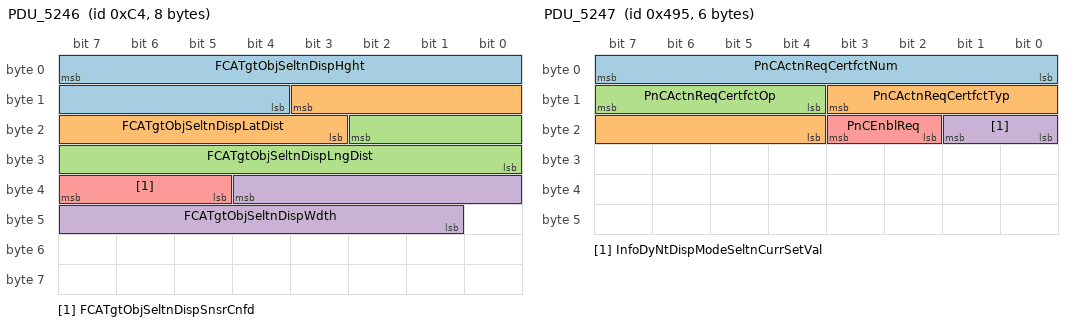
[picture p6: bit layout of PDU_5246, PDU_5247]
BO_ 196 PDU_5246: 8 CGM
 SG_ FCATgtObjSeltnDispHght : 7|12@0+ (0.0039,0) [0|15.9705] "m" VCU
 SG_ FCATgtObjSeltnDispLatDist : 11|9@0- (0.125,0) [-32|31.875] "m" VCU
 SG_ FCATgtObjSeltnDispLngDist : 18|11@0- (0.125,0) [-128|127.875] "m" VCU
 SG_ FCATgtObjSeltnDispWdth : 36|12@0+ (0.0039,0) [0|15.9705] "m" VCU
 SG_ FCATgtObjSeltnDispSnsrCnfd : 39|3@0+ (1,0) [0|3] "" VCU

BO_ 1173 PDU_5247: 6 CSM
 SG_ PnCActnReqCertfctNum : 7|8@0+ (1,0) [0|255] "" CGM
 SG_ PnCActnReqCertfctTyp : 11|8@0+ (1,0) [0|14] "" CGM
 SG_ PnCActnReqCertfctOp : 15|4@0+ (1,0) [0|4] "" CGM
 SG_ InfoDyNtDispModeSeltnCurrSetVal : 17|2@0+ (1,0) [0|3] "" IPC,IPC_INT
 SG_ PnCEnblReq : 19|2@0+ (1,0) [0|3] "" CGM

BO_ 1893 PDU_5248: 6 CSM
 SG_ TrlrProfLifetmEconRstReqd : 7|1@0+ (1,0) [0|1] "" CGM

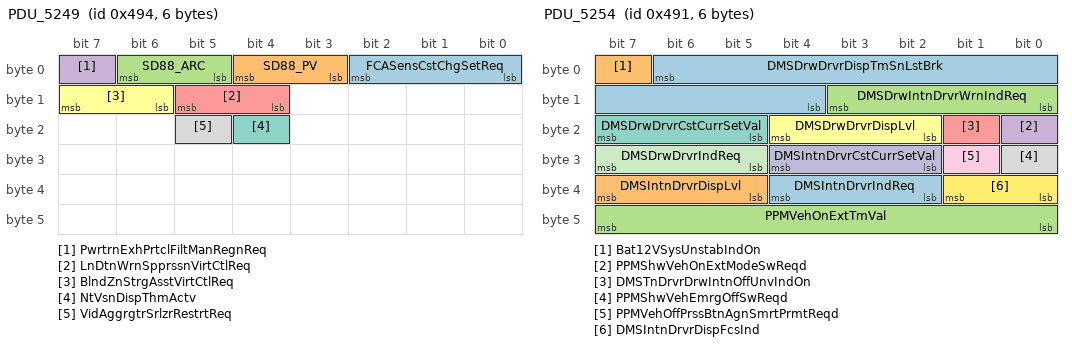
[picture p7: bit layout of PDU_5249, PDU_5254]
BO_ 1172 PDU_5249: 6 IPC
 SG_ FCASensCstChgSetReq : 2|3@0+ (1,0) [0|4] "" Vector__XXX
 SG_ SD88_PV : 4|2@0+ (1,0) [0|3] "" Vector__XXX
 SG_ SD88_ARC : 6|2@0+ (1,0) [0|3] "" Vector__XXX
 SG_ PwrtrnExhPrtclFiltManRegnReq : 7|1@0+ (1,0) [0|1] "" Vector__XXX
 SG_ LnDtnWrnSpprssnVirtCtlReq : 13|2@0+ (1,0) [0|2] "" Vector__XXX
 SG_ BlndZnStrgAsstVirtCtlReq : 15|2@0+ (1,0) [0|2] "" Vector__XXX
 SG_ NtVsnDispThmActv : 20|1@0+ (1,0) [0|1] "" Vector__XXX
 SG_ VidAggrgtrSrlzrRestrtReq : 21|1@0+ (1,0) [0|1] "" Vector__XXX

BO_ 1894 PDU_5250: 6 IPC
 SG_ PTExPrtclFltrMnlRgnDispPrsnt : 7|1@0+ (1,0) [0|1] "" CGM

BO_ 710 PDU_5251: 6 CGM
 SG_ HVPPP_HstVehSdslAngAuth : 7|12@0+ (0.0625,-128) [-128|127.938] "deg/s" CSM,CSM_AV,IPC,IPC_INT,VCU

BO_ 731 PDU_5252: 6 CGM
 SG_ PGI4P_ActlAxlTrqSecAuth : 6|15@0+ (2,-22534) [-22534|43000] "Nm" CSM,CSM_AV,VCU
 SG_ PGI4P_ActlAxlTrqSecAuth_Inv : 7|1@0+ (1,0) [0|1] "" CSM,CSM_AV,VCU

BO_ 1896 PDU_5253: 6 CGM
 SG_ IndHtgACSet : 6|2@0+ (1,0) [0|2] "" RadioLow,CSM,CSM_AV,VCU
 SG_ SuprRmtPrkAval : 7|1@0+ (1,0) [0|1] "" VCU

BO_ 1169 PDU_5254: 6 CGM
 SG_ DMSDrwDrvrDispTmSnLstBrk : 6|11@0+ (1,0) [0|2047] "min" IPC,IPC_INT,VCU
 SG_ Bat12VSysUnstabIndOn : 7|1@0+ (1,0) [0|1] "" IPC,IPC_INT,VCU
 SG_ DMSDrwIntnDrvrWrnIndReq : 11|4@0+ (1,0) [0|11] "" IPC,IPC_INT,VCU
 SG_ PPMShwVehOnExtModeSwReqd : 16|1@0+ (1,0) [0|1] "" VCU
 SG_ DMSTnDrvrDrwIntnOffUnvIndOn : 17|1@0+ (1,0) [0|1] "" IPC,IPC_INT,VCU
 SG_ DMSDrwDrvrDispLvl : 20|3@0+ (1,0) [0|5] "" IPC,IPC_INT,VCU
 SG_ DMSDrwDrvrCstCurrSetVal : 23|3@0+ (1,0) [0|3] "" CSM,CSM_AV,VCU
 SG_ PPMShwVehEmrgOffSwReqd : 24|1@0+ (1,0) [0|1] "" VCU
 SG_ PPMVehOffPrssBtnAgnSmrtPrmtReqd : 25|1@0+ (1,0) [0|1] "" VCU
 SG_ DMSIntnDrvrCstCurrSetVal : 28|3@0+ (1,0) [0|2] "" CSM,CSM_AV,VCU
 SG_ DMSDrwDrvrIndReq : 31|3@0+ (1,0) [0|5] "" TCP,IPC,IPC_INT,VCU
 SG_ DMSIntnDrvrDispFcsInd : 33|2@0+ (1,0) [0|2] "" IPC,IPC_INT,VCU
 SG_ DMSIntnDrvrIndReq : 36|3@0+ (1,0) [0|5] "" IPC,IPC_INT,VCU
 SG_ DMSIntnDrvrDispLvl : 39|3@0+ (1,0) [0|5] "" IPC,IPC_INT,VCU
 SG_ PPMVehOnExtTmVal : 47|8@0+ (1,0) [0|255] "Min" VCU

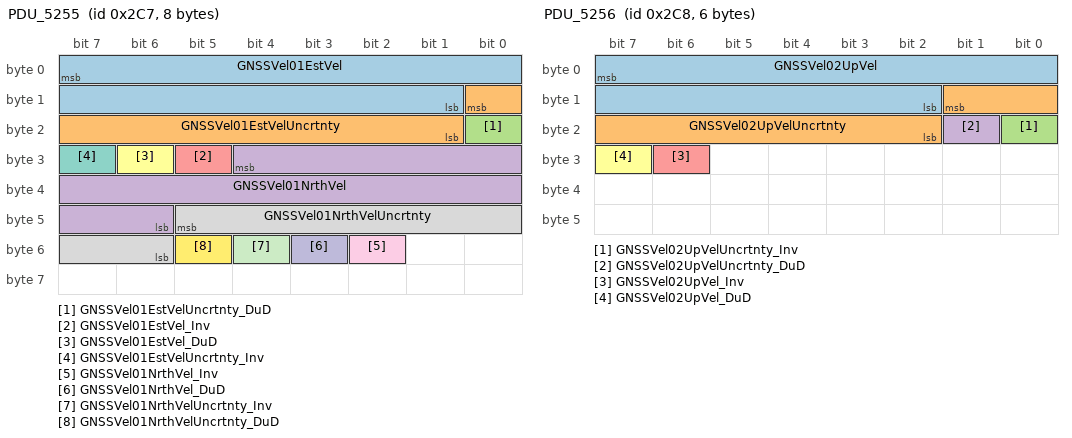
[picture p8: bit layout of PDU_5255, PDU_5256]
BO_ 711 PDU_5255: 8 TCP
 SG_ GNSSVel01EstVel : 7|15@0- (0.01,0) [-163.84|163.83] "" CGM
 SG_ GNSSVel01EstVelUncrtnty : 8|8@0+ (0.01,0) [0|2.55] "" CGM
 SG_ GNSSVel01EstVelUncrtnty_DuD : 16|1@0+ (1,0) [0|1] "" CGM
 SG_ GNSSVel01NrthVel : 28|15@0- (0.01,0) [-163.84|163.83] "" CGM
 SG_ GNSSVel01EstVel_Inv : 29|1@0+ (1,0) [0|1] "" CGM
 SG_ GNSSVel01EstVel_DuD : 30|1@0+ (1,0) [0|1] "" CGM
 SG_ GNSSVel01EstVelUncrtnty_Inv : 31|1@0+ (1,0) [0|1] "" CGM
 SG_ GNSSVel01NrthVelUncrtnty : 45|8@0+ (0.01,0) [0|2.55] "" CGM
 SG_ GNSSVel01NrthVel_Inv : 50|1@0+ (1,0) [0|1] "" CGM
 SG_ GNSSVel01NrthVel_DuD : 51|1@0+ (1,0) [0|1] "" CGM
 SG_ GNSSVel01NrthVelUncrtnty_Inv : 52|1@0+ (1,0) [0|1] "" CGM
 SG_ GNSSVel01NrthVelUncrtnty_DuD : 53|1@0+ (1,0) [0|1] "" CGM

BO_ 712 PDU_5256: 6 TCP
 SG_ GNSSVel02UpVel : 7|14@0- (0.01,0) [-81.92|81.91] "" CGM
 SG_ GNSSVel02UpVelUncrtnty : 9|8@0+ (0.01,0) [0|2.55] "" CGM
 SG_ GNSSVel02UpVelUncrtnty_Inv : 16|1@0+ (1,0) [0|1] "" CGM
 SG_ GNSSVel02UpVelUncrtnty_DuD : 17|1@0+ (1,0) [0|1] "" CGM
 SG_ GNSSVel02UpVel_Inv : 30|1@0+ (1,0) [0|1] "" CGM
 SG_ GNSSVel02UpVel_DuD : 31|1@0+ (1,0) [0|1] "" CGM

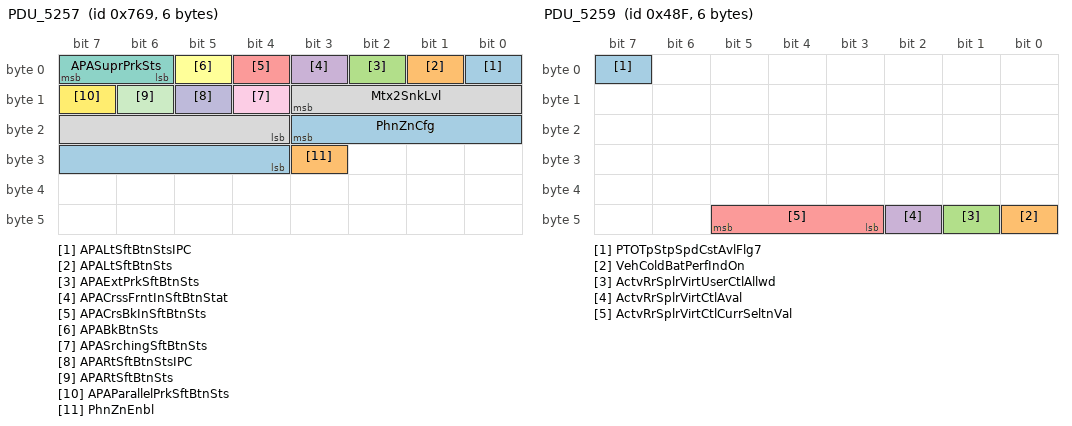
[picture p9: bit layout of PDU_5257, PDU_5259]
BO_ 1897 PDU_5257: 6 VCU
 SG_ APALtSftBtnStsIPC : 0|1@0+ (1,0) [0|1] "" CGM
 SG_ APALtSftBtnSts : 1|1@0+ (1,0) [0|1] "" CGM
 SG_ APAExtPrkSftBtnSts : 2|1@0+ (1,0) [0|1] "" CGM
 SG_ APACrssFrntInSftBtnStat : 3|1@0+ (1,0) [0|1] "" CGM
 SG_ APACrsBkInSftBtnSts : 4|1@0+ (1,0) [0|1] "" CGM
 SG_ APABkBtnSts : 5|1@0+ (1,0) [0|1] "" CGM
 SG_ APASuprPrkSts : 7|2@0+ (1,0) [0|2] "" CGM
 SG_ Mtx2SnkLvl : 11|8@0+ (0.5,-127.5) [-127.5|0] "db" AMP
 SG_ APASrchingSftBtnSts : 12|1@0+ (1,0) [0|1] "" CGM
 SG_ APARtSftBtnStsIPC : 13|1@0+ (1,0) [0|1] "" CGM
 SG_ APARtSftBtnSts : 14|1@0+ (1,0) [0|1] "" CGM
 SG_ APAParallelPrkSftBtnSts : 15|1@0+ (1,0) [0|1] "" CGM
 SG_ PhnZnCfg : 19|8@0+ (1,0) [0|255] "" AMP
 SG_ PhnZnEnbl : 27|1@0+ (1,0) [0|1] "" AMP

BO_ 1898 PDU_5258: 8 CGM
 SG_ PTOEngRunTmrCstAvlFlg14 : 0|1@0+ (1,0) [0|1] "" RadioLow,CSM,CSM_AV,VCU
 SG_ PTOEngRunTmrCstAvlFlg13 : 1|1@0+ (1,0) [0|1] "" RadioLow,CSM,CSM_AV,VCU
 SG_ PTOEngRunTmrCstAvlFlg12 : 2|1@0+ (1,0) [0|1] "" RadioLow,CSM,CSM_AV,VCU
 SG_ PTOEngRunTmrCstAvlFlg11 : 3|1@0+ (1,0) [0|1] "" RadioLow,CSM,CSM_AV,VCU
 SG_ PTOEngRunTmrCstAvlFlg10 : 4|1@0+ (1,0) [0|1] "" RadioLow,CSM,CSM_AV,VCU
 SG_ PTOEngRunTmrCstAvlFlg1 : 5|1@0+ (1,0) [0|1] "" RadioLow,CSM,CSM_AV,VCU
 SG_ OffBrdVehImbNtfn : 7|2@0+ (1,0) [0|3] "" TCP
 SG_ PTOEngRunTmrCstAvlFlg8 : 8|1@0+ (1,0) [0|1] "" RadioLow,CSM,CSM_AV,VCU
 SG_ PTOEngRunTmrCstAvlFlg7 : 9|1@0+ (1,0) [0|1] "" RadioLow,CSM,CSM_AV,VCU
 SG_ PTOEngRunTmrCstAvlFlg6 : 10|1@0+ (1,0) [0|1] "" RadioLow,CSM,CSM_AV,VCU
 SG_ PTOEngRunTmrCstAvlFlg5 : 11|1@0+ (1,0) [0|1] "" RadioLow,CSM,CSM_AV,VCU
 SG_ PTOEngRunTmrCstAvlFlg4 : 12|1@0+ (1,0) [0|1] "" RadioLow,CSM,CSM_AV,VCU
 SG_ PTOEngRunTmrCstAvlFlg3 : 13|1@0+ (1,0) [0|1] "" RadioLow,CSM,CSM_AV,VCU
 SG_ PTOEngRunTmrCstAvlFlg2 : 14|1@0+ (1,0) [0|1] "" RadioLow,CSM,CSM_AV,VCU
 SG_ PTOEngRunTmrCstAvlFlg15 : 15|1@0+ (1,0) [0|1] "" RadioLow,CSM,CSM_AV,VCU
 SG_ PTOSet1SpdCstAvlFlg11 : 16|1@0+ (1,0) [0|1] "" RadioLow,CSM,CSM_AV,VCU
 SG_ PTOSet1SpdCstAvlFlg10 : 17|1@0+ (1,0) [0|1] "" RadioLow,CSM,CSM_AV,VCU
 SG_ PTOSet1SpdCstAvlFlg1 : 18|1@0+ (1,0) [0|1] "" RadioLow,CSM,CSM_AV,VCU
 SG_ PTOModeCstAvlFlg2 : 19|1@0+ (1,0) [0|1] "" RadioLow,CSM,CSM_AV,VCU
 SG_ PTOModeCstAvlFlg1 : 20|1@0+ (1,0) [0|1] "" RadioLow,CSM,CSM_AV,VCU
 SG_ PTOEngSpdTypCstAvlFlg2 : 21|1@0+ (1,0) [0|1] "" RadioLow,CSM,CSM_AV,VCU
 SG_ PTOEngSpdTypCstAvlFlg1 : 22|1@0+ (1,0) [0|1] "" RadioLow,CSM,CSM_AV,VCU
 SG_ PTOEngRunTmrCstAvlFlg9 : 23|1@0+ (1,0) [0|1] "" RadioLow,CSM,CSM_AV,VCU
 SG_ PTOSet1SpdCstAvlFlg5 : 24|1@0+ (1,0) [0|1] "" RadioLow,CSM,CSM_AV,VCU
 SG_ PTOSet1SpdCstAvlFlg4 : 25|1@0+ (1,0) [0|1] "" RadioLow,CSM,CSM_AV,VCU
 SG_ PTOSet1SpdCstAvlFlg3 : 26|1@0+ (1,0) [0|1] "" RadioLow,CSM,CSM_AV,VCU
 SG_ PTOSet1SpdCstAvlFlg2 : 27|1@0+ (1,0) [0|1] "" RadioLow,CSM,CSM_AV,VCU
 SG_ PTOSet1SpdCstAvlFlg15 : 28|1@0+ (1,0) [0|1] "" RadioLow,CSM,CSM_AV,VCU
 SG_ PTOSet1SpdCstAvlFlg14 : 29|1@0+ (1,0) [0|1] "" RadioLow,CSM,CSM_AV,VCU
 SG_ PTOSet1SpdCstAvlFlg13 : 30|1@0+ (1,0) [0|1] "" RadioLow,CSM,CSM_AV,VCU
 SG_ PTOSet1SpdCstAvlFlg12 : 31|1@0+ (1,0) [0|1] "" RadioLow,CSM,CSM_AV,VCU
 SG_ PTOSet2SpdCstAvlFlg12 : 32|1@0+ (1,0) [0|1] "" RadioLow,CSM,CSM_AV,VCU
 SG_ PTOSet2SpdCstAvlFlg11 : 33|1@0+ (1,0) [0|1] "" RadioLow,CSM,CSM_AV,VCU
 SG_ PTOSet2SpdCstAvlFlg10 : 34|1@0+ (1,0) [0|1] "" RadioLow,CSM,CSM_AV,VCU
 SG_ PTOSet2SpdCstAvlFlg1 : 35|1@0+ (1,0) [0|1] "" RadioLow,CSM,CSM_AV,VCU
 SG_ PTOSet1SpdCstAvlFlg9 : 36|1@0+ (1,0) [0|1] "" RadioLow,CSM,CSM_AV,VCU
 SG_ PTOSet1SpdCstAvlFlg8 : 37|1@0+ (1,0) [0|1] "" RadioLow,CSM,CSM_AV,VCU
 SG_ PTOSet1SpdCstAvlFlg7 : 38|1@0+ (1,0) [0|1] "" RadioLow,CSM,CSM_AV,VCU
 SG_ PTOSet1SpdCstAvlFlg6 : 39|1@0+ (1,0) [0|1] "" RadioLow,CSM,CSM_AV,VCU
 SG_ PTOSet2SpdCstAvlFlg6 : 40|1@0+ (1,0) [0|1] "" RadioLow,CSM,CSM_AV,VCU
 SG_ PTOSet2SpdCstAvlFlg5 : 41|1@0+ (1,0) [0|1] "" RadioLow,CSM,CSM_AV,VCU
 SG_ PTOSet2SpdCstAvlFlg4 : 42|1@0+ (1,0) [0|1] "" RadioLow,CSM,CSM_AV,VCU
 SG_ PTOSet2SpdCstAvlFlg3 : 43|1@0+ (1,0) [0|1] "" RadioLow,CSM,CSM_AV,VCU
 SG_ PTOSet2SpdCstAvlFlg2 : 44|1@0+ (1,0) [0|1] "" RadioLow,CSM,CSM_AV,VCU
 SG_ PTOSet2SpdCstAvlFlg15 : 45|1@0+ (1,0) [0|1] "" RadioLow,CSM,CSM_AV,VCU
 SG_ PTOSet2SpdCstAvlFlg14 : 46|1@0+ (1,0) [0|1] "" RadioLow,CSM,CSM_AV,VCU
 SG_ PTOSet2SpdCstAvlFlg13 : 47|1@0+ (1,0) [0|1] "" RadioLow,CSM,CSM_AV,VCU
 SG_ PTOStndbySpdCstAvlFlg5 : 48|1@0+ (1,0) [0|1] "" RadioLow,CSM,CSM_AV,VCU
 SG_ PTOStndbySpdCstAvlFlg4 : 49|1@0+ (1,0) [0|1] "" RadioLow,CSM,CSM_AV,VCU
 SG_ PTOStndbySpdCstAvlFlg3 : 50|1@0+ (1,0) [0|1] "" RadioLow,CSM,CSM_AV,VCU
 SG_ PTOStndbySpdCstAvlFlg2 : 51|1@0+ (1,0) [0|1] "" RadioLow,CSM,CSM_AV,VCU
 SG_ PTOStndbySpdCstAvlFlg1 : 52|1@0+ (1,0) [0|1] "" RadioLow,CSM,CSM_AV,VCU
 SG_ PTOSet2SpdCstAvlFlg9 : 53|1@0+ (1,0) [0|1] "" RadioLow,CSM,CSM_AV,VCU
 SG_ PTOSet2SpdCstAvlFlg8 : 54|1@0+ (1,0) [0|1] "" RadioLow,CSM,CSM_AV,VCU
 SG_ PTOSet2SpdCstAvlFlg7 : 55|1@0+ (1,0) [0|1] "" RadioLow,CSM,CSM_AV,VCU
 SG_ PTOTpStpSpdCstAvlFlg6 : 56|1@0+ (1,0) [0|1] "" RadioLow,CSM,CSM_AV,VCU
 SG_ PTOTpStpSpdCstAvlFlg5 : 57|1@0+ (1,0) [0|1] "" RadioLow,CSM,CSM_AV,VCU
 SG_ PTOTpStpSpdCstAvlFlg4 : 58|1@0+ (1,0) [0|1] "" RadioLow,CSM,CSM_AV,VCU
 SG_ PTOTpStpSpdCstAvlFlg3 : 59|1@0+ (1,0) [0|1] "" RadioLow,CSM,CSM_AV,VCU
 SG_ PTOTpStpSpdCstAvlFlg2 : 60|1@0+ (1,0) [0|1] "" RadioLow,CSM,CSM_AV,VCU
 SG_ PTOTpStpSpdCstAvlFlg1 : 61|1@0+ (1,0) [0|1] "" RadioLow,CSM,CSM_AV,VCU
 SG_ PTOStndbySpdCstAvlFlg7 : 62|1@0+ (1,0) [0|1] "" RadioLow,CSM,CSM_AV,VCU
 SG_ PTOStndbySpdCstAvlFlg6 : 63|1@0+ (1,0) [0|1] "" RadioLow,CSM,CSM_AV,VCU

BO_ 1167 PDU_5259: 6 CGM
 SG_ PTOTpStpSpdCstAvlFlg7 : 7|1@0+ (1,0) [0|1] "" RadioLow,CSM,CSM_AV,VCU
 SG_ VehColdBatPerfIndOn : 40|1@0+ (1,0) [0|1] "" CSM,CSM_AV,VCU
 SG_ ActvRrSplrVirtUserCtlAllwd : 41|1@0+ (1,0) [0|1] "" VCU
 SG_ ActvRrSplrVirtCtlAval : 42|1@0+ (1,0) [0|1] "" VCU
 SG_ ActvRrSplrVirtCtlCurrSeltnVal : 45|3@0+ (1,0) [0|6] "" VCU

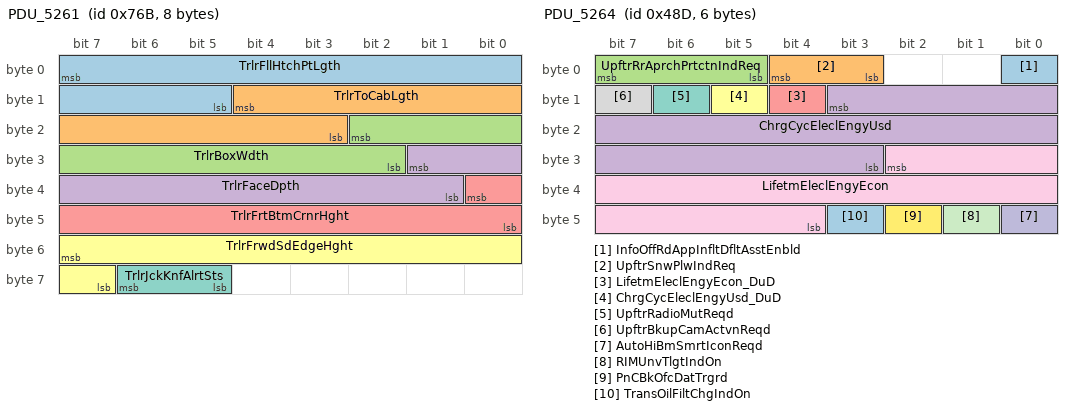
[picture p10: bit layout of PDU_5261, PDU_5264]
BO_ 1899 PDU_5261: 8 CSM
 SG_ TrlrFllHtchPtLgth : 7|11@0+ (1,0) [0|2047] "cm" CGM
 SG_ TrlrToCabLgth : 12|10@0+ (1,0) [0|1023] "cm" CGM
 SG_ TrlrBoxWdth : 18|9@0+ (1,0) [0|511] "cm" CGM
 SG_ TrlrFaceDpth : 25|9@0+ (1,0) [0|511] "cm" CGM
 SG_ TrlrFrtBtmCrnrHght : 32|9@0+ (1,0) [0|511] "cm" CGM
 SG_ TrlrFrwdSdEdgeHght : 55|9@0+ (1,0) [0|511] "cm" CGM
 SG_ TrlrJckKnfAlrtSts : 62|2@0+ (1,0) [0|3] "" CGM

BO_ 1166 PDU_5262: 6 CSM
 SG_ VehBedHtchToCabLgth : 7|9@0+ (1,0) [0|511] "cm" CGM

BO_ 1900 PDU_5263: 6 CGM
 SG_ VirtCtlHtdVntStSwRrAval : 6|1@0+ (1,0) [0|1] "" VCU
 SG_ VirtCtlHtdVntStSwFrtAval : 7|1@0+ (1,0) [0|1] "" VCU

BO_ 1165 PDU_5264: 6 CGM
 SG_ InfoOffRdAppInfltDfltAsstEnbld : 0|1@0+ (1,0) [0|1] "" CSM,CSM_AV,VCU
 SG_ UpftrSnwPlwIndReq : 4|2@0+ (1,0) [0|3] "" IPC,IPC_INT,VCU
 SG_ UpftrRrAprchPrtctnIndReq : 7|3@0+ (1,0) [0|4] "" IPC,IPC_INT,VCU
 SG_ ChrgCycEleclEngyUsd : 11|17@0+ (0.1,0) [0|13107.1] "kWh" CSM,CSM_AV,IPC,IPC_INT,VCU
 SG_ LifetmEleclEngyEcon_DuD : 12|1@0+ (1,0) [0|1] "" CSM,CSM_AV,VCU
 SG_ ChrgCycEleclEngyUsd_DuD : 13|1@0+ (1,0) [0|1] "" CSM,CSM_AV,IPC,IPC_INT,VCU
 SG_ UpftrRadioMutReqd : 14|1@0+ (1,0) [0|1] "" RadioLow,VCU
 SG_ UpftrBkupCamActvnReqd : 15|1@0+ (1,0) [0|1] "" RadioLow,CSM,VCU
 SG_ LifetmEleclEngyEcon : 26|15@0- (0.1,0) [-1638.4|1638.3] "" TCP,CSM,CSM_AV,VCU
 SG_ AutoHiBmSmrtIconReqd : 40|1@0+ (1,0) [0|1] "" VCU
 SG_ RIMUnvTlgtIndOn : 41|1@0+ (1,0) [0|1] "" IPC,IPC_INT,VCU
 SG_ PnCBkOfcDatTrgrd : 42|1@0+ (1,0) [0|1] "" TCP
 SG_ TransOilFiltChgIndOn : 43|1@0+ (1,0) [0|1] "" IPC,IPC_INT,VCU

BO_ 1901 PDU_5265: 6 CSM
 SG_ InfoOffRdAppInfltDfltAsstTgtPrs : 7|10@0+ (1,0) [0|1023] "kPaG" CGM
 SG_ InfoOffRdAppInfltDfltAsstReqd : 13|1@0+ (1,0) [0|1] "" CGM

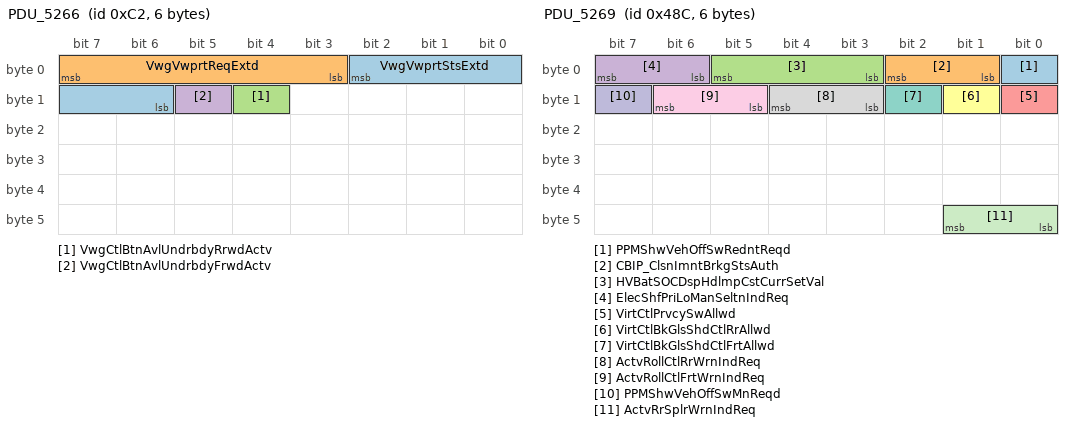
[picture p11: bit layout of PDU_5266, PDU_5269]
BO_ 194 PDU_5266: 6 CGM
 SG_ VwgVwprtStsExtd : 2|5@0+ (1,0) [0|5] "" VCU
 SG_ VwgVwprtReqExtd : 7|5@0+ (1,0) [0|5] "" VCU
 SG_ VwgCtlBtnAvlUndrbdyRrwdActv : 12|1@0+ (1,0) [0|1] "" VCU
 SG_ VwgCtlBtnAvlUndrbdyFrwdActv : 13|1@0+ (1,0) [0|1] "" VCU

BO_ 192 PDU_5267: 6 VCU
 SG_ VwgVwprtSeltnExtd : 7|5@0+ (1,0) [0|5] "" CGM

BO_ 112 PDU_5268: 6 CGM
 SG_ AtTrnsGrSftDrct : 7|2@0+ (1,0) [0|2] "" AMP,VCU

BO_ 1164 PDU_5269: 6 CGM
 SG_ PPMShwVehOffSwRedntReqd : 0|1@0+ (1,0) [0|1] "" VCU
 SG_ CBIP_ClsnImntBrkgStsAuth : 2|2@0+ (1,0) [0|2] "" VKM
 SG_ HVBatSOCDspHdlmpCstCurrSetVal : 5|3@0+ (1,0) [0|2] "" CSM,CSM_AV,VCU
 SG_ ElecShfPriLoManSeltnIndReq : 7|2@0+ (1,0) [0|2] "" VCU
 SG_ VirtCtlPrvcySwAllwd : 8|1@0+ (1,0) [0|1] "" VCU
 SG_ VirtCtlBkGlsShdCtlRrAllwd : 9|1@0+ (1,0) [0|1] "" VCU
 SG_ VirtCtlBkGlsShdCtlFrtAllwd : 10|1@0+ (1,0) [0|1] "" VCU
 SG_ ActvRollCtlRrWrnIndReq : 12|2@0+ (1,0) [0|2] "" VCU
 SG_ ActvRollCtlFrtWrnIndReq : 14|2@0+ (1,0) [0|2] "" VCU
 SG_ PPMShwVehOffSwMnReqd : 15|1@0+ (1,0) [0|1] "" VCU
 SG_ ActvRrSplrWrnIndReq : 41|2@0+ (1,0) [0|3] "" VCU

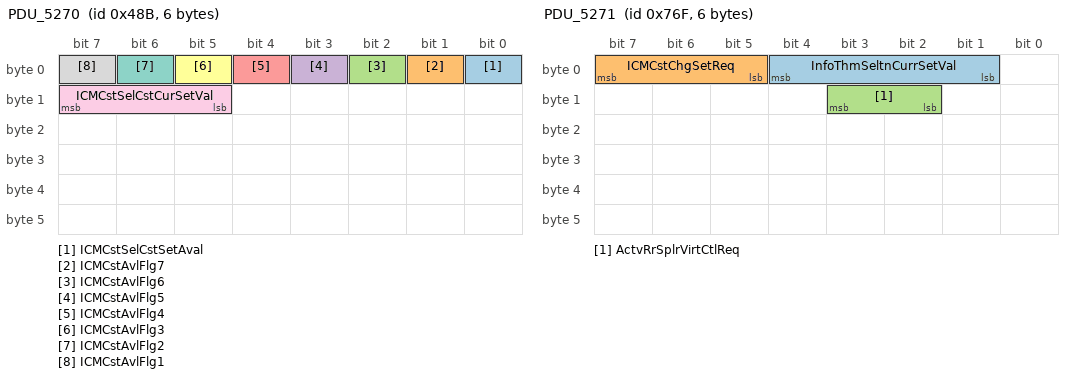
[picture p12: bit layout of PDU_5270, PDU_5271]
BO_ 1163 PDU_5270: 6 CGM
 SG_ ICMCstSelCstSetAval : 0|1@0+ (1,0) [0|1] "" VCU
 SG_ ICMCstAvlFlg7 : 1|1@0+ (1,0) [0|1] "" VCU
 SG_ ICMCstAvlFlg6 : 2|1@0+ (1,0) [0|1] "" VCU
 SG_ ICMCstAvlFlg5 : 3|1@0+ (1,0) [0|1] "" VCU
 SG_ ICMCstAvlFlg4 : 4|1@0+ (1,0) [0|1] "" VCU
 SG_ ICMCstAvlFlg3 : 5|1@0+ (1,0) [0|1] "" VCU
 SG_ ICMCstAvlFlg2 : 6|1@0+ (1,0) [0|1] "" VCU
 SG_ ICMCstAvlFlg1 : 7|1@0+ (1,0) [0|1] "" VCU
 SG_ ICMCstSelCstCurSetVal : 15|3@0+ (1,0) [0|4] "" VCU

BO_ 1903 PDU_5271: 6 VCU
 SG_ InfoThmSeltnCurrSetVal : 4|4@0+ (1,0) [0|15] "" CGM
 SG_ ICMCstChgSetReq : 7|3@0+ (1,0) [0|4] "" CGM
 SG_ ActvRrSplrVirtCtlReq : 11|2@0+ (1,0) [0|2] "" CGM

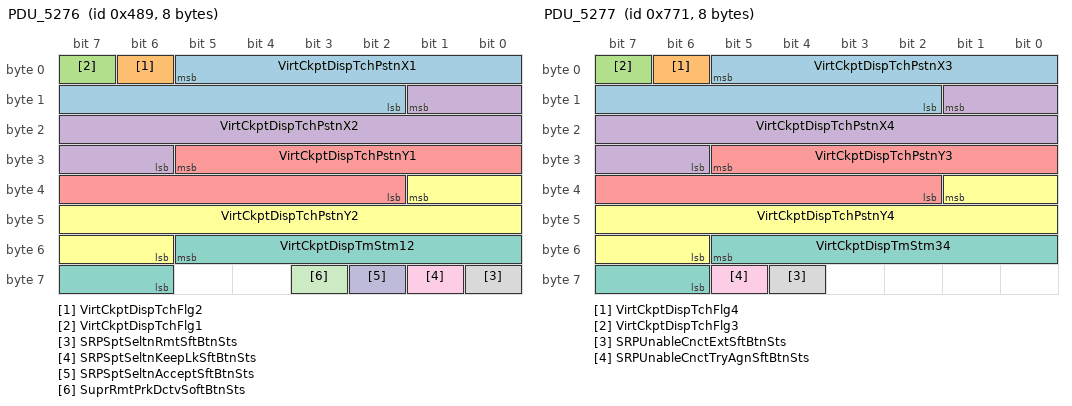
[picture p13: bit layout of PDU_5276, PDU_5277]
BO_ 1161 PDU_5276: 8 VCU
 SG_ VirtCkptDispTchPstnX1 : 5|12@0+ (0.0244141,0) [0|99.9756] "%" PDR
 SG_ VirtCkptDispTchFlg2 : 6|1@0+ (1,0) [0|1] "" PDR
 SG_ VirtCkptDispTchFlg1 : 7|1@0+ (1,0) [0|1] "" PDR
 SG_ VirtCkptDispTchPstnX2 : 9|12@0+ (0.0244141,0) [0|99.9756] "%" PDR
 SG_ VirtCkptDispTchPstnY1 : 29|12@0+ (0.0244141,0) [0|99.9756] "%" PDR
 SG_ VirtCkptDispTchPstnY2 : 33|12@0+ (0.0244141,0) [0|99.9756] "%" PDR
 SG_ VirtCkptDispTmStm12 : 53|8@0+ (1,0) [0|255] "msec" PDR
 SG_ SRPSptSeltnRmtSftBtnSts : 56|1@0+ (1,0) [0|1] "" CGM
 SG_ SRPSptSeltnKeepLkSftBtnSts : 57|1@0+ (1,0) [0|1] "" CGM
 SG_ SRPSptSeltnAcceptSftBtnSts : 58|1@0+ (1,0) [0|1] "" CGM
 SG_ SuprRmtPrkDctvSoftBtnSts : 59|1@0+ (1,0) [0|1] "" CGM

BO_ 1905 PDU_5277: 8 VCU
 SG_ VirtCkptDispTchPstnX3 : 5|12@0+ (0.0244141,0) [0|99.9756] "%" PDR
 SG_ VirtCkptDispTchFlg4 : 6|1@0+ (1,0) [0|1] "" PDR
 SG_ VirtCkptDispTchFlg3 : 7|1@0+ (1,0) [0|1] "" PDR
 SG_ VirtCkptDispTchPstnX4 : 9|12@0+ (0.0244141,0) [0|99.9756] "%" PDR
 SG_ VirtCkptDispTchPstnY3 : 29|12@0+ (0.0244141,0) [0|99.9756] "%" PDR
 SG_ VirtCkptDispTchPstnY4 : 33|12@0+ (0.0244141,0) [0|99.9756] "%" PDR
 SG_ VirtCkptDispTmStm34 : 53|8@0+ (1,0) [0|255] "msec" PDR
 SG_ SRPUnableCnctExtSftBtnSts : 60|1@0+ (1,0) [0|1] "" CGM
 SG_ SRPUnableCnctTryAgnSftBtnSts : 61|1@0+ (1,0) [0|1] "" CGM

BO_ 1162 PDU_5278: 6 CGM
 SG_ PrplDispExtndCpbltyLvlPct : 2|7@0+ (1,0) [0|127] "%" IPC,IPC_INT,VCU
 SG_ HiVltgSysFltIndOn : 3|1@0+ (1,0) [0|1] "" IPC,IPC_INT,VCU
 SG_ HiVltgChrgLtdRsn : 7|4@0+ (1,0) [0|11] "" TCP,CSM,CSM_AV,IPC,IPC_INT,VCU
 SG_ PrplDispExtndPwrLvlPct : 10|7@0+ (1,0) [0|127] "%" IPC,IPC_INT,VCU
 SG_ PrplDispExtndCpbltyLvlPct_DuD : 11|1@0+ (1,0) [0|1] "" IPC,IPC_INT,VCU
 SG_ PrplDispExtndPwrLvlPct_DuD : 19|1@0+ (1,0) [0|1] "" IPC,IPC_INT,VCU
 SG_ InfoWndMtnCtlRRAllwd : 24|1@0+ (1,0) [0|1] "" VCU
 SG_ InfoWndMtnCtlRFAllwd : 25|1@0+ (1,0) [0|1] "" VCU
 SG_ InfoWndMtnCtlLRAllwd : 26|1@0+ (1,0) [0|1] "" VCU
 SG_ InfoWndMtnCtlLFAllwd : 27|1@0+ (1,0) [0|1] "" VCU
 SG_ InfoSnrfMtnCtlAllwd : 28|1@0+ (1,0) [0|1] "" VCU
 SG_ InfoFrtSnshdMtnCtlAllwd : 29|1@0+ (1,0) [0|1] "" VCU
 SG_ FrtSnshdPstnStsInfo : 31|2@0+ (1,0) [0|3] "" VCU
 SG_ PwrlineCommCtlPilotDC_Inv : 32|1@0+ (1,0) [0|1] "" PLCM,VCU
 SG_ PwrlineCommCtlPilotDC : 39|7@0+ (1,0) [0|127] "%" PLCM,VCU
 SG_ HiVltgCouplerPrxmtySts_Inv : 45|1@0+ (1,0) [0|1] "" PLCM,VCU
 SG_ HiVltgCouplerPrxmtySts : 47|2@0+ (1,0) [0|2] "" PLCM,VCU

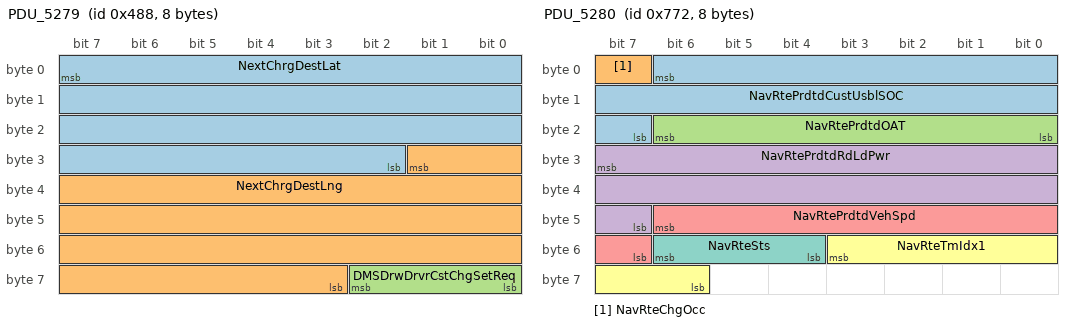
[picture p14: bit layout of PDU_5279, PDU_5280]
BO_ 1160 PDU_5279: 8 CSM
 SG_ NextChrgDestLat : 7|30@0- (1,0) [-5.36871e+008|5.36871e+008] "ms arc" CGM
 SG_ NextChrgDestLng : 25|31@0- (1,0) [-1.07374e+009|1.07374e+009] "ms arc" CGM
 SG_ DMSDrwDrvrCstChgSetReq : 58|3@0+ (1,0) [0|3] "" CGM

BO_ 1906 PDU_5280: 8 CSM
 SG_ NavRtePrdtdCustUsblSOC : 6|16@0+ (0.00152588,0) [0|99.9985] "%" CGM
 SG_ NavRteChgOcc : 7|1@0+ (1,0) [0|1] "" CGM
 SG_ NavRtePrdtdOAT : 22|7@0+ (1,-40) [-40|87] "C" CGM
 SG_ NavRtePrdtdRdLdPwr : 31|17@0- (0.01,0) [-655.36|655.35] "kW" CGM
 SG_ NavRtePrdtdVehSpd : 46|8@0+ (1,0) [0|255] "km/h" CGM
 SG_ NavRteTmIdx1 : 51|6@0+ (1,0) [0|63] "minute" CGM
 SG_ NavRteSts : 54|3@0+ (1,0) [0|4] "" CGM

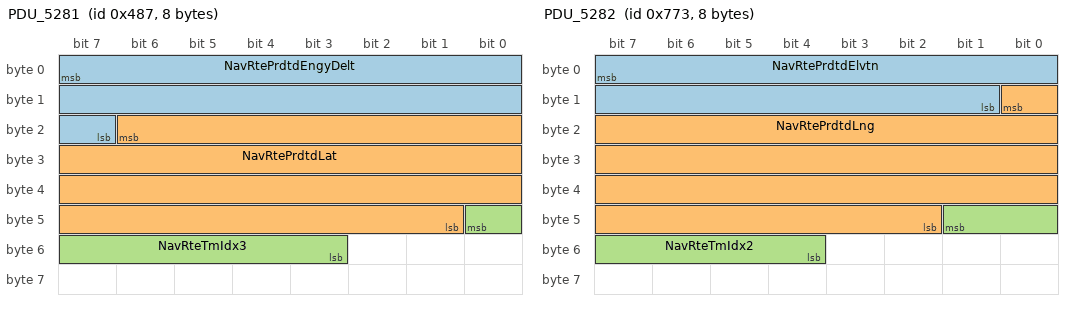
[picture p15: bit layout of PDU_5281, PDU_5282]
BO_ 1159 PDU_5281: 8 CSM
 SG_ NavRtePrdtdEngyDelt : 7|17@0- (0.01,0) [-655.36|655.35] "kWh" CGM
 SG_ NavRtePrdtdLat : 22|30@0- (1,0) [-5.36871e+008|5.36871e+008] "ms arc" CGM
 SG_ NavRteTmIdx3 : 40|6@0+ (1,0) [0|63] "minute" CGM

BO_ 1907 PDU_5282: 8 CSM
 SG_ NavRtePrdtdElvtn : 7|15@0- (1,0) [-16384|16383] "m" CGM
 SG_ NavRtePrdtdLng : 8|31@0- (1,0) [-1.07374e+009|1.07374e+009] "ms arc" CGM
 SG_ NavRteTmIdx2 : 41|6@0+ (1,0) [0|63] "minute" CGM

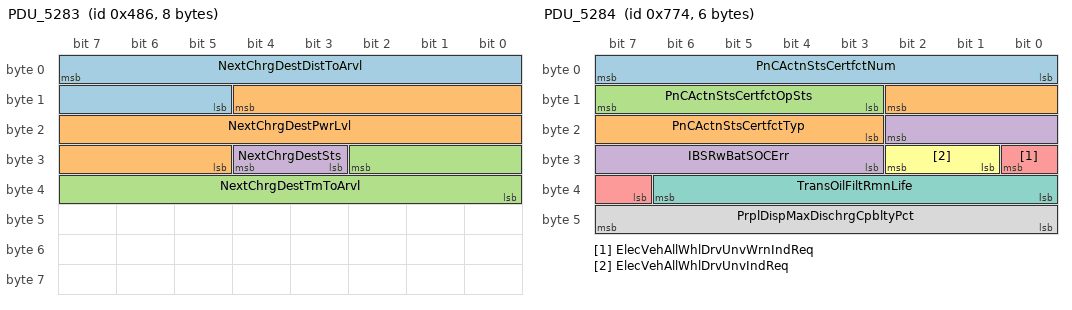
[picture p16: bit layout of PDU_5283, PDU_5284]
BO_ 1158 PDU_5283: 8 CSM
 SG_ NextChrgDestDistToArvl : 7|11@0+ (1,0) [0|2047] "km" CGM
 SG_ NextChrgDestPwrLvl : 12|16@0+ (0.01,0) [0|655.35] "kW" CGM
 SG_ NextChrgDestTmToArvl : 26|11@0+ (1,0) [0|2047] "minute" CGM
 SG_ NextChrgDestSts : 28|2@0+ (1,0) [0|3] "" CGM

BO_ 1908 PDU_5284: 6 CGM
 SG_ PnCActnStsCertfctNum : 7|8@0+ (1,0) [0|255] "" CSM,CSM_AV,VCU
 SG_ PnCActnStsCertfctTyp : 10|8@0+ (1,0) [0|14] "" CSM,CSM_AV,VCU
 SG_ PnCActnStsCertfctOpSts : 15|5@0+ (1,0) [0|17] "" CSM,CSM_AV,VCU
 SG_ IBSRwBatSOCErr : 18|8@0+ (0.39,0) [0|99.45] "%" CSM,CSM_AV,VCU
 SG_ ElecVehAllWhlDrvUnvWrnIndReq : 24|2@0+ (1,0) [0|2] "" IPC,IPC_INT,VCU
 SG_ ElecVehAllWhlDrvUnvIndReq : 26|2@0+ (1,0) [0|2] "" IPC,IPC_INT,VCU
 SG_ TransOilFiltRmnLife : 38|7@0+ (1,0) [0|127] "%" IPC,IPC_INT,VCU
 SG_ PrplDispMaxDischrgCpbltyPct : 47|8@0+ (1,0) [0|255] "%" IPC,IPC_INT,VCU

BO_ 1157 PDU_5285: 6 CGM
 SG_ FAXVCLoPrtyFltChmEvntStat : 1|2@0+ (1,0) [0|2] "" IPC,IPC_INT,VCU
 SG_ FAXVCInCtlChmEvntStat : 3|2@0+ (1,0) [0|2] "" IPC,IPC_INT,VCU
 SG_ FAXVCHiPrtyFltChmEvntStat : 5|2@0+ (1,0) [0|2] "" IPC,IPC_INT,VCU
 SG_ AutoCtlrGnrcChmEvntStat : 7|2@0+ (1,0) [0|2] "" IPC,IPC_INT,VCU
 SG_ VehNDtctgFAXVCErrChmEvntStat : 9|2@0+ (1,0) [0|2] "" IPC,IPC_INT,VCU
 SG_ VehExtdFAXVCModeChmEvntStat : 11|2@0+ (1,0) [0|2] "" IPC,IPC_INT,VCU
 SG_ FAXVCSevPrtyFltChmEvntStat : 13|2@0+ (1,0) [0|2] "" IPC,IPC_INT,VCU
 SG_ FAXVCMedPrtyFltChmEvntStat : 15|2@0+ (1,0) [0|2] "" IPC,IPC_INT,VCU
 SG_ IndHtdArmrstLvlRrRt : 21|3@0+ (1,0) [0|4] "" VCU
 SG_ UpftrRrAprchPrtctnChmEvntStat : 23|2@0+ (1,0) [0|2] "" IPC,IPC_INT,VCU
 SG_ DMSIntnDrvrCstAvlFlg1 : 32|1@0+ (1,0) [0|1] "" CSM,CSM_AV,VCU
 SG_ DMSDrwIntnDrvrDtnAlrtMutReqd : 33|1@0+ (1,0) [0|1] "" CSM,CSM_AV,VCU
 SG_ DMSDrwIntnDrvrLvl1ChmEvntStat : 35|2@0+ (1,0) [0|2] "" IPC,IPC_INT,VCU
 SG_ DMSDrwIntnDrvrLvl2ChmEvntStat : 37|2@0+ (1,0) [0|2] "" IPC,IPC_INT,VCU
 SG_ DMSIntnDrvrCstSetAval : 41|1@0+ (1,0) [0|1] "" CSM,CSM_AV,VCU
 SG_ DMSIntnDrvrCstAvlFlg7 : 42|1@0+ (1,0) [0|1] "" CSM,CSM_AV,VCU
 SG_ DMSIntnDrvrCstAvlFlg6 : 43|1@0+ (1,0) [0|1] "" CSM,CSM_AV,VCU
 SG_ DMSIntnDrvrCstAvlFlg5 : 44|1@0+ (1,0) [0|1] "" CSM,CSM_AV,VCU
 SG_ DMSIntnDrvrCstAvlFlg4 : 45|1@0+ (1,0) [0|1] "" CSM,CSM_AV,VCU
 SG_ DMSIntnDrvrCstAvlFlg3 : 46|1@0+ (1,0) [0|1] "" CSM,CSM_AV,VCU
 SG_ DMSIntnDrvrCstAvlFlg2 : 47|1@0+ (1,0) [0|1] "" CSM,CSM_AV,VCU

BO_ 1155 PDU_5287: 6 CGM
 SG_ HVBatSOCDspHdlmpCstAvlFlg1 : 0|1@0+ (1,0) [0|1] "" CSM,CSM_AV,VCU
 SG_ InfoWndMtnCtlRRAval : 2|1@0+ (1,0) [0|1] "" VCU
 SG_ InfoWndMtnCtlRFAval : 3|1@0+ (1,0) [0|1] "" VCU
 SG_ InfoWndMtnCtlLRAval : 4|1@0+ (1,0) [0|1] "" VCU
 SG_ InfoWndMtnCtlLFAval : 5|1@0+ (1,0) [0|1] "" VCU
 SG_ InfoSnrfMtnCtlAval : 6|1@0+ (1,0) [0|1] "" VCU
 SG_ VirtCtlIntrCmptRelCtlAval : 7|1@0+ (1,0) [0|1] "" VCU
 SG_ Aux1AmbtColrCtlCstAvlFlg100 : 8|1@0+ (1,0) [0|1] "" VCU
 SG_ HVBatSOCDspHdlmpCstSetAval : 9|1@0+ (1,0) [0|1] "" CSM,CSM_AV,VCU
 SG_ HVBatSOCDspHdlmpCstAvlFlg7 : 10|1@0+ (1,0) [0|1] "" CSM,CSM_AV,VCU
 SG_ HVBatSOCDspHdlmpCstAvlFlg6 : 11|1@0+ (1,0) [0|1] "" CSM,CSM_AV,VCU
 SG_ HVBatSOCDspHdlmpCstAvlFlg5 : 12|1@0+ (1,0) [0|1] "" CSM,CSM_AV,VCU
 SG_ HVBatSOCDspHdlmpCstAvlFlg4 : 13|1@0+ (1,0) [0|1] "" CSM,CSM_AV,VCU
 SG_ HVBatSOCDspHdlmpCstAvlFlg3 : 14|1@0+ (1,0) [0|1] "" CSM,CSM_AV,VCU
 SG_ HVBatSOCDspHdlmpCstAvlFlg2 : 15|1@0+ (1,0) [0|1] "" CSM,CSM_AV,VCU
 SG_ Aux1AmbtColrCtlCstAvlFlg108 : 16|1@0+ (1,0) [0|1] "" VCU
 SG_ Aux1AmbtColrCtlCstAvlFlg107 : 17|1@0+ (1,0) [0|1] "" VCU
 SG_ Aux1AmbtColrCtlCstAvlFlg106 : 18|1@0+ (1,0) [0|1] "" VCU
 SG_ Aux1AmbtColrCtlCstAvlFlg105 : 19|1@0+ (1,0) [0|1] "" VCU
 SG_ Aux1AmbtColrCtlCstAvlFlg104 : 20|1@0+ (1,0) [0|1] "" VCU
 SG_ Aux1AmbtColrCtlCstAvlFlg103 : 21|1@0+ (1,0) [0|1] "" VCU
 SG_ Aux1AmbtColrCtlCstAvlFlg102 : 22|1@0+ (1,0) [0|1] "" VCU
 SG_ Aux1AmbtColrCtlCstAvlFlg101 : 23|1@0+ (1,0) [0|1] "" VCU
 SG_ Aux1AmbtColrCtlCstAvlFlg116 : 24|1@0+ (1,0) [0|1] "" VCU
 SG_ Aux1AmbtColrCtlCstAvlFlg115 : 25|1@0+ (1,0) [0|1] "" VCU
 SG_ Aux1AmbtColrCtlCstAvlFlg114 : 26|1@0+ (1,0) [0|1] "" VCU
 SG_ Aux1AmbtColrCtlCstAvlFlg113 : 27|1@0+ (1,0) [0|1] "" VCU
 SG_ Aux1AmbtColrCtlCstAvlFlg112 : 28|1@0+ (1,0) [0|1] "" VCU
 SG_ Aux1AmbtColrCtlCstAvlFlg111 : 29|1@0+ (1,0) [0|1] "" VCU
 SG_ Aux1AmbtColrCtlCstAvlFlg110 : 30|1@0+ (1,0) [0|1] "" VCU
 SG_ Aux1AmbtColrCtlCstAvlFlg109 : 31|1@0+ (1,0) [0|1] "" VCU
 SG_ Aux1AmbtColrCtlCstAvlFlg124 : 32|1@0+ (1,0) [0|1] "" VCU
 SG_ Aux1AmbtColrCtlCstAvlFlg123 : 33|1@0+ (1,0) [0|1] "" VCU
 SG_ Aux1AmbtColrCtlCstAvlFlg122 : 34|1@0+ (1,0) [0|1] "" VCU
 SG_ Aux1AmbtColrCtlCstAvlFlg121 : 35|1@0+ (1,0) [0|1] "" VCU
 SG_ Aux1AmbtColrCtlCstAvlFlg120 : 36|1@0+ (1,0) [0|1] "" VCU
 SG_ Aux1AmbtColrCtlCstAvlFlg119 : 37|1@0+ (1,0) [0|1] "" VCU
 SG_ Aux1AmbtColrCtlCstAvlFlg118 : 38|1@0+ (1,0) [0|1] "" VCU
 SG_ Aux1AmbtColrCtlCstAvlFlg117 : 39|1@0+ (1,0) [0|1] "" VCU
 SG_ Aux1AmbtColrCtlCstAvlFlg99 : 40|1@0+ (1,0) [0|1] "" VCU
 SG_ Aux1AmbtColrCtlCstAvlFlg98 : 41|1@0+ (1,0) [0|1] "" VCU
 SG_ Aux1AmbtColrCtlCstAvlFlg97 : 42|1@0+ (1,0) [0|1] "" VCU
 SG_ Aux1AmbtColrCtlCstAvlFlg96 : 43|1@0+ (1,0) [0|1] "" VCU
 SG_ Aux1AmbtColrCtlCstAvlFlg95 : 44|1@0+ (1,0) [0|1] "" VCU
 SG_ Aux1AmbtColrCtlCstAvlFlg127 : 45|1@0+ (1,0) [0|1] "" VCU
 SG_ Aux1AmbtColrCtlCstAvlFlg126 : 46|1@0+ (1,0) [0|1] "" VCU
 SG_ Aux1AmbtColrCtlCstAvlFlg125 : 47|1@0+ (1,0) [0|1] "" VCU

BO_ 1911 PDU_5288: 6 VCU
 SG_ VirtCtlIntrCmptRelReqd : 7|1@0+ (1,0) [0|1] "" CGM
 SG_ RrCtlDispFltIndOn : 40|1@0+ (1,0) [0|1] "" CGM

BA_DEF_ SG_  "SignalType" STRING ;
BA_DEF_ SG_  "SignalLongName" STRING ;
BA_DEF_ BO_  "GenMsgCycleTime" INT 0 10000;
BA_DEF_ BO_  "GenMsgSendType" ENUM "cyclicX","spontanX","cyclicIfActiveX","spontanWithDelay","cyclicAndSpontanX","cyclicAndSpontanWithDelay","spontanWithRepetition","cyclicIfActiveAndSpontanWD";
BA_DEF_DEF_  "SignalType" "";
BA_DEF_DEF_  "SignalLongName" "";
BA_DEF_DEF_  "GenMsgCycleTime" 0;
BA_DEF_DEF_  "GenMsgSendType" "cyclicX";
BA_ "GenMsgCycleTime" BO_ 1432 1000;
BA_ "GenMsgCycleTime" BO_ 1471 1000;
BA_ "GenMsgCycleTime" BO_ 1472 1000;
BA_ "GenMsgCycleTime" BO_ 1474 1000;
BA_ "GenMsgCycleTime" BO_ 1475 1000;
BA_ "GenMsgCycleTime" BO_ 1476 1000;
BA_ "GenMsgCycleTime" BO_ 1477 1000;
BA_ "GenMsgCycleTime" BO_ 1496 1000;
BA_ "GenMsgCycleTime" BO_ 1504 1000;
BA_ "GenMsgCycleTime" BO_ 1505 1000;
BA_ "GenMsgCycleTime" BO_ 929 250;
BA_ "GenMsgCycleTime" BO_ 206 50;
BA_ "GenMsgCycleTime" BO_ 1535 1000;
BA_ "GenMsgCycleTime" BO_ 1246 1000;
BA_ "GenMsgCycleTime" BO_ 1229 1000;
BA_ "GenMsgCycleTime" BO_ 1837 1000;
BA_ "GenMsgCycleTime" BO_ 1467 1000;
BA_ "GenMsgCycleTime" BO_ 714 100;
BA_ "GenMsgCycleTime" BO_ 1468 1000;
BA_ "GenMsgCycleTime" BO_ 1469 1000;
BA_ "GenMsgCycleTime" BO_ 1470 1000;
BA_ "GenMsgCycleTime" BO_ 1473 1000;
BA_ "GenMsgCycleTime" BO_ 1892 1000;
BA_ "GenMsgCycleTime" BO_ 732 100;
BA_ "GenMsgCycleTime" BO_ 196 40;
BA_ "GenMsgCycleTime" BO_ 1173 1000;
BA_ "GenMsgCycleTime" BO_ 1893 1000;
BA_ "GenMsgCycleTime" BO_ 1172 1000;
BA_ "GenMsgCycleTime" BO_ 1894 1000;
BA_ "GenMsgCycleTime" BO_ 710 100;
BA_ "GenMsgCycleTime" BO_ 731 100;
BA_ "GenMsgCycleTime" BO_ 1896 1000;
BA_ "GenMsgCycleTime" BO_ 1169 1000;
BA_ "GenMsgCycleTime" BO_ 711 100;
BA_ "GenMsgCycleTime" BO_ 712 100;
BA_ "GenMsgCycleTime" BO_ 1897 1000;
BA_ "GenMsgCycleTime" BO_ 1898 1000;
BA_ "GenMsgCycleTime" BO_ 1167 1000;
BA_ "GenMsgCycleTime" BO_ 1899 1000;
BA_ "GenMsgCycleTime" BO_ 1166 1000;
BA_ "GenMsgCycleTime" BO_ 1900 1000;
BA_ "GenMsgCycleTime" BO_ 1165 1000;
BA_ "GenMsgCycleTime" BO_ 1901 1000;
BA_ "GenMsgCycleTime" BO_ 112 10;
BA_ "GenMsgCycleTime" BO_ 1164 1000;
BA_ "GenMsgCycleTime" BO_ 1163 1000;
BA_ "GenMsgCycleTime" BO_ 1903 1000;
BA_ "GenMsgCycleTime" BO_ 1161 1000;
BA_ "GenMsgCycleTime" BO_ 1905 1000;
BA_ "GenMsgCycleTime" BO_ 1162 1000;
BA_ "GenMsgCycleTime" BO_ 1160 1000;
BA_ "GenMsgCycleTime" BO_ 1906 1000;
BA_ "GenMsgCycleTime" BO_ 1159 1000;
BA_ "GenMsgCycleTime" BO_ 1907 1000;
BA_ "GenMsgCycleTime" BO_ 1158 1000;
BA_ "GenMsgCycleTime" BO_ 1908 1000;
BA_ "GenMsgCycleTime" BO_ 1157 1000;
BA_ "GenMsgCycleTime" BO_ 1155 1000;
BA_ "GenMsgCycleTime" BO_ 1911 1000;
BA_ "SignalType" SG_ 1432 HVACFCRTLR_LtLvlActv "ENM";
BA_ "SignalLongName" SG_ 1432 HVACFCRTLR_LtLvlActv "DEPRECATED VIP 25 - HVAC Front Controls Request Temperature Level Rear : Left Level Active";
BA_ "SignalLongName" SG_ 1432 HVACFCRTLR_LtLvl "DEPRECATED VIP 25 - HVAC Front Controls Request Temperature Level Rear : Left Level";
BA_ "SignalLongName" SG_ 1432 HVACFCRTLR_RtLvl "DEPRECATED VIP 25 - HVAC Front Controls Request Temperature Level Rear : Right Level";
BA_ "SignalLongName" SG_ 1432 HVACFCRTLR_LtLvlChg "DEPRECATED VIP 25 - HVAC Front Controls Request Temperature Level Rear : Left Level Change";
BA_ "SignalLongName" SG_ 1432 HVACFCRTLR_RwVltg1 "DEPRECATED VIP 25 - HVAC Front Controls Request Temperature Level Rear : Raw Voltage 1";
BA_ "SignalLongName" SG_ 1432 HVACFCRTLR_RtLvlChg "DEPRECATED VIP 25 - HVAC Front Controls Request Temperature Level Rear : Right Level Change";
BA_ "SignalType" SG_ 1432 HVACFCRTLR_RtLvlActv "ENM";
BA_ "SignalLongName" SG_ 1432 HVACFCRTLR_RtLvlActv "DEPRECATED VIP 25 - HVAC Front Controls Request Temperature Level Rear : Right Level Active";
BA_ "SignalLongName" SG_ 1432 HVACFCRTLR_RwVltg2 "DEPRECATED VIP 25 - HVAC Front Controls Request Temperature Level Rear : Raw Voltage 2";
BA_ "SignalLongName" SG_ 1432 HVACFCRL_RwVltg "HVAC Front Controls Rear Lock : Raw Voltage";
BA_ "SignalType" SG_ 1432 RHVSLF_VntLvlChgUp "ENM";
BA_ "SignalLongName" SG_ 1432 RHVSLF_VntLvlChgUp "Request Heated Vented Seat Left Front : Vented Level Change Up";
BA_ "SignalType" SG_ 1432 RHVSLF_VntLvlChgDn "ENM";
BA_ "SignalLongName" SG_ 1432 RHVSLF_VntLvlChgDn "Request Heated Vented Seat Left Front : Vented Level Change Down";
BA_ "SignalType" SG_ 1432 RHVSLF_HtdCushBckLvlChgUp "ENM";
BA_ "SignalLongName" SG_ 1432 RHVSLF_HtdCushBckLvlChgUp "Request Heated Vented Seat Left Front : Heated Cushion and Back Level Change Up";
BA_ "SignalType" SG_ 1432 RHVSLF_HtdCushBckLvlChgDn "ENM";
BA_ "SignalLongName" SG_ 1432 RHVSLF_HtdCushBckLvlChgDn "Request Heated Vented Seat Left Front : Heated Cushion and Back Level Change Down";
BA_ "SignalType" SG_ 1432 RHVSLF_HtdBckLvlChgUp "ENM";
BA_ "SignalLongName" SG_ 1432 RHVSLF_HtdBckLvlChgUp "Request Heated Vented Seat Left Front : Heated Back Level Change Up";
BA_ "SignalType" SG_ 1432 RHVSLF_HtdBckLvlChgDn "ENM";
BA_ "SignalLongName" SG_ 1432 RHVSLF_HtdBckLvlChgDn "Request Heated Vented Seat Left Front : Heated Back Level Change Down";
BA_ "SignalType" SG_ 1432 HVACFCRL_SetChg "ENM";
BA_ "SignalLongName" SG_ 1432 HVACFCRL_SetChg "HVAC Front Controls Rear Lock : Setting Change";
BA_ "SignalType" SG_ 1432 VntStStckSwRF "ENM";
BA_ "SignalLongName" SG_ 1432 VntStStckSwRF "Vented Seat Stuck Switch Right Front";
BA_ "SignalType" SG_ 1432 RHVSRF_VntLvlChgUp "ENM";
BA_ "SignalLongName" SG_ 1432 RHVSRF_VntLvlChgUp "Request Heated Vented Seat Right Front : Vented Level Change Up";
BA_ "SignalType" SG_ 1432 RHVSRF_VntLvlChgDn "ENM";
BA_ "SignalLongName" SG_ 1432 RHVSRF_VntLvlChgDn "Request Heated Vented Seat Right Front : Vented Level Change Down";
BA_ "SignalType" SG_ 1432 RHVSRF_HtdCushBckLvlChgUp "ENM";
BA_ "SignalLongName" SG_ 1432 RHVSRF_HtdCushBckLvlChgUp "Request Heated Vented Seat Right Front : Heated Cushion and Back Level Change Up";
BA_ "SignalType" SG_ 1432 RHVSRF_HtdCushBckLvlChgDn "ENM";
BA_ "SignalLongName" SG_ 1432 RHVSRF_HtdCushBckLvlChgDn "Request Heated Vented Seat Right Front : Heated Cushion and Back Level Change Down";
BA_ "SignalType" SG_ 1432 RHVSRF_HtdBckLvlChgUp "ENM";
BA_ "SignalLongName" SG_ 1432 RHVSRF_HtdBckLvlChgUp "Request Heated Vented Seat Right Front : Heated Back Level Change Up";
BA_ "SignalType" SG_ 1432 RHVSRF_HtdBckLvlChgDn "ENM";
BA_ "SignalLongName" SG_ 1432 RHVSRF_HtdBckLvlChgDn "Request Heated Vented Seat Right Front : Heated Back Level Change Down";
BA_ "SignalLongName" SG_ 1471 PCOSN2_NtfnEvntAutoVehSyncCnt "Post Collision OnStar Notification 2 : Notification Event Autonomous Vehicle Sync Counter";
BA_ "SignalType" SG_ 1471 PCOSN2_NtfnFrstRowRtStOccpSts "ENM";
BA_ "SignalLongName" SG_ 1471 PCOSN2_NtfnFrstRowRtStOccpSts "Post Collision OnStar Notification 2 : Notification First Row Right Seat Occupancy Status";
BA_ "SignalType" SG_ 1471 PCOSN2_NtfnFrstRowRtStBtSts "ENM";
BA_ "SignalLongName" SG_ 1471 PCOSN2_NtfnFrstRowRtStBtSts "Post Collision OnStar Notification 2 : Notification First Row Right Seatbelt Status";
BA_ "SignalType" SG_ 1471 PCOSN2_NtfnFrstRowLtStOccpSts "ENM";
BA_ "SignalLongName" SG_ 1471 PCOSN2_NtfnFrstRowLtStOccpSts "Post Collision OnStar Notification 2 : Notification First Row Left Seat Occupancy Status";
BA_ "SignalType" SG_ 1471 PCOSN2_NtfnFrstRowLtStBtSts "ENM";
BA_ "SignalLongName" SG_ 1471 PCOSN2_NtfnFrstRowLtStBtSts "Post Collision OnStar Notification 2 : Notification First Row Left Seatbelt Status";
BA_ "SignalType" SG_ 1471 PCOSN2_NtfnRrImpASevAchvd "ENM";
BA_ "SignalLongName" SG_ 1471 PCOSN2_NtfnRrImpASevAchvd "Post Collision OnStar Notification 2 : Notification Rear Impact Airbag Severity Achieved";
BA_ "SignalType" SG_ 1471 InfoFrtSnshdMtnCtlAval "ENM";
BA_ "SignalLongName" SG_ 1471 InfoFrtSnshdMtnCtlAval "Infotainment Front Sunshade Motion Control Available";
BA_ "SignalType" SG_ 1472 CustMdEVPedMpCstmAvFlg1 "ENM";
BA_ "SignalLongName" SG_ 1472 CustMdEVPedMpCstmAvFlg1 "Custom Mode Electric Vehicle Pedal Map Customization Availability Flag 1";
BA_ "SignalType" SG_ 1474 CustMdEVPedMpCstmAvFlg2 "ENM";
BA_ "SignalLongName" SG_ 1474 CustMdEVPedMpCstmAvFlg2 "Custom Mode Electric Vehicle Pedal Map Customization Availability Flag 2";
BA_ "SignalType" SG_ 1475 FrtStHtdBkLvlAval "ENM";
BA_ "SignalLongName" SG_ 1475 FrtStHtdBkLvlAval "Front Seat Heated Vented Levels Available : Front Seat Heated Back Levels Available";
BA_ "SignalType" SG_ 1475 RrStHtdCushBkLvlAval "ENM";
BA_ "SignalLongName" SG_ 1475 RrStHtdCushBkLvlAval "Rear Seat Heated Vented Levels Available : Rear Seat Heated Cushion and Back Levels Available";
BA_ "SignalType" SG_ 1475 RrStHtdBkLvlAval "ENM";
BA_ "SignalLongName" SG_ 1475 RrStHtdBkLvlAval "Rear Seat Heated Vented Levels Available : Rear Seat Heated Back Levels Available";
BA_ "SignalType" SG_ 1475 FrtStVntCoolLvlAval "ENM";
BA_ "SignalLongName" SG_ 1475 FrtStVntCoolLvlAval "Front Seat Heated Vented Levels Available : Front Seat Vented or Cooled Levels Available";
BA_ "SignalType" SG_ 1475 FrtStHtdCushBkLvlAval "ENM";
BA_ "SignalLongName" SG_ 1475 FrtStHtdCushBkLvlAval "Front Seat Heated Vented Levels Available : Front Seat Heated Cushion and Back Levels Available";
BA_ "SignalType" SG_ 1475 RrStVntCoolLvlAval "ENM";
BA_ "SignalLongName" SG_ 1475 RrStVntCoolLvlAval "Rear Seat Heated Vented Levels Available : Rear Seat Vented or Cooled Levels Available";
BA_ "SignalType" SG_ 1475 CustMdEVPedMpCstmCurSetVal "ENM";
BA_ "SignalLongName" SG_ 1475 CustMdEVPedMpCstmCurSetVal "Custom Mode Electric Vehicle Pedal Map Customization Current Setting Value";
BA_ "SignalType" SG_ 1475 VhStShVehOnExtdMdSwReqd "ENM";
BA_ "SignalLongName" SG_ 1475 VhStShVehOnExtdMdSwReqd "Vehicle State Show Vehicle On Extend Mode Switch Requested";
BA_ "SignalType" SG_ 1475 VSEMOpEndAllwdSts "ENM";
BA_ "SignalLongName" SG_ 1475 VSEMOpEndAllwdSts "Vehicle State Extend Mode Operation End Allowed Status";
BA_ "SignalType" SG_ 1475 CustMdEngyRegnCstmCurSetVal "ENM";
BA_ "SignalLongName" SG_ 1475 CustMdEngyRegnCstmCurSetVal "Custom Mode Energy Regeneration Customization Current Setting Value";
BA_ "SignalType" SG_ 1476 OffRdMdElecVehPedMpVisDispVal "ENM";
BA_ "SignalLongName" SG_ 1476 OffRdMdElecVehPedMpVisDispVal "Off Road Mode Electric Vehicle Pedal Map Visualization Display Value";
BA_ "SignalType" SG_ 1476 PrsnlMdEngyRegnCstmCurSetVal "ENM";
BA_ "SignalLongName" SG_ 1476 PrsnlMdEngyRegnCstmCurSetVal "Personal Mode Energy Regeneration Customization Current Setting Value";
BA_ "SignalType" SG_ 1476 PrsnlMdEVPedMpCstmCurSetVal "ENM";
BA_ "SignalLongName" SG_ 1476 PrsnlMdEVPedMpCstmCurSetVal "Personal Mode Electric Vehicle Pedal Map Customization Current Setting Value";
BA_ "SignalType" SG_ 1476 OffRdMdEngyRegnVisDispVal "ENM";
BA_ "SignalLongName" SG_ 1476 OffRdMdEngyRegnVisDispVal "Off Road Mode Energy Regeneration Visualization Display Value";
BA_ "SignalType" SG_ 1476 SprtMdEngyRegnVisDispVal "ENM";
BA_ "SignalLongName" SG_ 1476 SprtMdEngyRegnVisDispVal "Sport Mode Energy Regeneration Visualization Display Value";
BA_ "SignalType" SG_ 1476 SprtMdElecVehPedMpVisDispVal "ENM";
BA_ "SignalLongName" SG_ 1476 SprtMdElecVehPedMpVisDispVal "Sport Mode Electric Vehicle Pedal Map Visualization Display Value";
BA_ "SignalType" SG_ 1476 TourMdElecVehPedMpVisDispVal "ENM";
BA_ "SignalLongName" SG_ 1476 TourMdElecVehPedMpVisDispVal "Tour Mode Electric Vehicle Pedal Map Visualization Display Value";
BA_ "SignalType" SG_ 1476 TkMdEngyRegnVisDispVal "ENM";
BA_ "SignalLongName" SG_ 1476 TkMdEngyRegnVisDispVal "Track Mode Energy Regeneration Visualization Display Value";
BA_ "SignalType" SG_ 1476 TkMdElecVehPedMpVisDispVal "ENM";
BA_ "SignalLongName" SG_ 1476 TkMdElecVehPedMpVisDispVal "Track Mode Electric Vehicle Pedal Map Visualization Display Value";
BA_ "SignalType" SG_ 1476 TrnMdBrkPedVisDispVal "ENM";
BA_ "SignalLongName" SG_ 1476 TrnMdBrkPedVisDispVal "Terrain Mode Brake Pedal Visualization Display Value";
BA_ "SignalType" SG_ 1476 TrnMdActvAerodynsVisDispVal "ENM";
BA_ "SignalLongName" SG_ 1476 TrnMdActvAerodynsVisDispVal "Terrain Mode Active Aerodynamics Visualization Display Value";
BA_ "SignalType" SG_ 1476 TourMdEngyRegnVisDispVal "ENM";
BA_ "SignalLongName" SG_ 1476 TourMdEngyRegnVisDispVal "Tour Mode Energy Regeneration Visualization Display Value";
BA_ "SignalType" SG_ 1476 TrnMdESCVisDispVal "ENM";
BA_ "SignalLongName" SG_ 1476 TrnMdESCVisDispVal "Terrain Mode Electronic Stability Control Visualization Display Value";
BA_ "SignalType" SG_ 1476 TrnMdDrvlnVisDispVal "ENM";
BA_ "SignalLongName" SG_ 1476 TrnMdDrvlnVisDispVal "Terrain Mode Driveline Visualization Display Value";
BA_ "SignalType" SG_ 1476 TrnMdPwrtrnVisDispVal "ENM";
BA_ "SignalLongName" SG_ 1476 TrnMdPwrtrnVisDispVal "Terrain Mode Powertrain Visualization Display Value";
BA_ "SignalType" SG_ 1476 TrnMdEngyRegnVisDispVal "ENM";
BA_ "SignalLongName" SG_ 1476 TrnMdEngyRegnVisDispVal "Terrain Mode Energy Regeneration Visualization Display Value";
BA_ "SignalType" SG_ 1476 TrnMdElecVehPedMpVisDispVal "ENM";
BA_ "SignalLongName" SG_ 1476 TrnMdElecVehPedMpVisDispVal "Terrain Mode Electric Vehicle Pedal Map Visualization Display Value";
BA_ "SignalType" SG_ 1476 CustMdEVPedMpCstmAvFlg3 "ENM";
BA_ "SignalLongName" SG_ 1476 CustMdEVPedMpCstmAvFlg3 "Custom Mode Electric Vehicle Pedal Map Customization Availability Flag 3";
BA_ "SignalType" SG_ 1476 TrnMdSndVisDispVal "ENM";
BA_ "SignalLongName" SG_ 1476 TrnMdSndVisDispVal "Terrain Mode Sound Visualization Display Value";
BA_ "SignalType" SG_ 1476 TrnMdRideHghtVisDispVal "ENM";
BA_ "SignalLongName" SG_ 1476 TrnMdRideHghtVisDispVal "Terrain Mode Ride Height Visualization Display Value";
BA_ "SignalType" SG_ 1477 TrnMdStrgVisDispVal "ENM";
BA_ "SignalLongName" SG_ 1477 TrnMdStrgVisDispVal "Terrain Mode Steering Visualization Display Value";
BA_ "SignalType" SG_ 1477 TrnMdSpnsnVisDispVal "ENM";
BA_ "SignalLongName" SG_ 1477 TrnMdSpnsnVisDispVal "Terrain Mode Suspension Visualization Display Value";
BA_ "SignalType" SG_ 1477 WthrMdEngyRegnVisDispVal "ENM";
BA_ "SignalLongName" SG_ 1477 WthrMdEngyRegnVisDispVal "Weather Mode Energy Regeneration Visualization Display Value";
BA_ "SignalType" SG_ 1477 WthrMdElecVehPedMpVisDispVal "ENM";
BA_ "SignalLongName" SG_ 1477 WthrMdElecVehPedMpVisDispVal "Weather Mode Electric Vehicle Pedal Map Visualization Display Value";
BA_ "SignalType" SG_ 1477 CustMdEVPedMpCstmAvFlg4 "ENM";
BA_ "SignalLongName" SG_ 1477 CustMdEVPedMpCstmAvFlg4 "Custom Mode Electric Vehicle Pedal Map Customization Availability Flag 4";
BA_ "SignalType" SG_ 1477 HtdStrgWhlLvlAval "ENM";
BA_ "SignalLongName" SG_ 1477 HtdStrgWhlLvlAval "Heated Steering Wheel Levels Available";
BA_ "SignalType" SG_ 1477 CustMdEngyRegnCstmAvFlg4 "ENM";
BA_ "SignalLongName" SG_ 1477 CustMdEngyRegnCstmAvFlg4 "Custom Mode Energy Regeneration Customization Availability Flag 4";
BA_ "SignalType" SG_ 1477 CustMdEngyRegnCstmAvFlg3 "ENM";
BA_ "SignalLongName" SG_ 1477 CustMdEngyRegnCstmAvFlg3 "Custom Mode Energy Regeneration Customization Availability Flag 3";
BA_ "SignalType" SG_ 1477 CustMdEngyRegnCstmAvFlg2 "ENM";
BA_ "SignalLongName" SG_ 1477 CustMdEngyRegnCstmAvFlg2 "Custom Mode Energy Regeneration Customization Availability Flag 2";
BA_ "SignalType" SG_ 1477 CustMdEngyRegnCstmAvFlg1 "ENM";
BA_ "SignalLongName" SG_ 1477 CustMdEngyRegnCstmAvFlg1 "Custom Mode Energy Regeneration Customization Availability Flag 1";
BA_ "SignalType" SG_ 1477 CustMdEVPedMpCstmSetAv "ENM";
BA_ "SignalLongName" SG_ 1477 CustMdEVPedMpCstmSetAv "Custom Mode Electric Vehicle Pedal Map Customization Setting Available";
BA_ "SignalType" SG_ 1477 CustMdEVPedMpCstmAvFlg7 "ENM";
BA_ "SignalLongName" SG_ 1477 CustMdEVPedMpCstmAvFlg7 "Custom Mode Electric Vehicle Pedal Map Customization Availability Flag 7";
BA_ "SignalType" SG_ 1477 CustMdEVPedMpCstmAvFlg6 "ENM";
BA_ "SignalLongName" SG_ 1477 CustMdEVPedMpCstmAvFlg6 "Custom Mode Electric Vehicle Pedal Map Customization Availability Flag 6";
BA_ "SignalType" SG_ 1477 CustMdEVPedMpCstmAvFlg5 "ENM";
BA_ "SignalLongName" SG_ 1477 CustMdEVPedMpCstmAvFlg5 "Custom Mode Electric Vehicle Pedal Map Customization Availability Flag 5";
BA_ "SignalType" SG_ 1477 OnePedDrvCstSetAllwdFlg3 "ENM";
BA_ "SignalLongName" SG_ 1477 OnePedDrvCstSetAllwdFlg3 "One Pedal Driving Customization Setting Allowed Flag 3";
BA_ "SignalType" SG_ 1477 OnePedDrvCstSetAllwdFlg2 "ENM";
BA_ "SignalLongName" SG_ 1477 OnePedDrvCstSetAllwdFlg2 "One Pedal Driving Customization Setting Allowed Flag 2";
BA_ "SignalType" SG_ 1477 OnePedDrvCstSetAllwdFlg1 "ENM";
BA_ "SignalLongName" SG_ 1477 OnePedDrvCstSetAllwdFlg1 "One Pedal Driving Customization Setting Allowed Flag 1";
BA_ "SignalType" SG_ 1477 CustMdEngyRegnCstmSetAv "ENM";
BA_ "SignalLongName" SG_ 1477 CustMdEngyRegnCstmSetAv "Custom Mode Energy Regeneration Customization Setting Available";
BA_ "SignalType" SG_ 1477 CustMdEngyRegnCstmAvFlg7 "ENM";
BA_ "SignalLongName" SG_ 1477 CustMdEngyRegnCstmAvFlg7 "Custom Mode Energy Regeneration Customization Availability Flag 7";
BA_ "SignalType" SG_ 1477 CustMdEngyRegnCstmAvFlg6 "ENM";
BA_ "SignalLongName" SG_ 1477 CustMdEngyRegnCstmAvFlg6 "Custom Mode Energy Regeneration Customization Availability Flag 6";
BA_ "SignalType" SG_ 1477 CustMdEngyRegnCstmAvFlg5 "ENM";
BA_ "SignalLongName" SG_ 1477 CustMdEngyRegnCstmAvFlg5 "Custom Mode Energy Regeneration Customization Availability Flag 5";
BA_ "SignalType" SG_ 1477 OnePedDrvCstSetAvlFlg3 "ENM";
BA_ "SignalLongName" SG_ 1477 OnePedDrvCstSetAvlFlg3 "One Pedal Driving Customization Setting Availability Flag 3";
BA_ "SignalType" SG_ 1477 OnePedDrvCstSetAvlFlg2 "ENM";
BA_ "SignalLongName" SG_ 1477 OnePedDrvCstSetAvlFlg2 "One Pedal Driving Customization Setting Availability Flag 2";
BA_ "SignalType" SG_ 1477 OnePedDrvCstSetAvlFlg1 "ENM";
BA_ "SignalLongName" SG_ 1477 OnePedDrvCstSetAvlFlg1 "One Pedal Driving Customization Setting Availability Flag 1";
BA_ "SignalType" SG_ 1477 OnePedDrvCstSetAval "ENM";
BA_ "SignalLongName" SG_ 1477 OnePedDrvCstSetAval "One Pedal Driving Customization Setting Available";
BA_ "SignalType" SG_ 1477 OnePedDrvCstSetAllwdFlg7 "ENM";
BA_ "SignalLongName" SG_ 1477 OnePedDrvCstSetAllwdFlg7 "One Pedal Driving Customization Setting Allowed Flag 7";
BA_ "SignalType" SG_ 1477 OnePedDrvCstSetAllwdFlg6 "ENM";
BA_ "SignalLongName" SG_ 1477 OnePedDrvCstSetAllwdFlg6 "One Pedal Driving Customization Setting Allowed Flag 6";
BA_ "SignalType" SG_ 1477 OnePedDrvCstSetAllwdFlg5 "ENM";
BA_ "SignalLongName" SG_ 1477 OnePedDrvCstSetAllwdFlg5 "One Pedal Driving Customization Setting Allowed Flag 5";
BA_ "SignalType" SG_ 1477 OnePedDrvCstSetAllwdFlg4 "ENM";
BA_ "SignalLongName" SG_ 1477 OnePedDrvCstSetAllwdFlg4 "One Pedal Driving Customization Setting Allowed Flag 4";
BA_ "SignalType" SG_ 1477 PrsnlMdEVPedMpCstmAvFlg3 "ENM";
BA_ "SignalLongName" SG_ 1477 PrsnlMdEVPedMpCstmAvFlg3 "Personal Mode Electric Vehicle Pedal Map Customization Availability Flag 3";
BA_ "SignalType" SG_ 1477 PrsnlMdEVPedMpCstmAvFlg2 "ENM";
BA_ "SignalLongName" SG_ 1477 PrsnlMdEVPedMpCstmAvFlg2 "Personal Mode Electric Vehicle Pedal Map Customization Availability Flag 2";
BA_ "SignalType" SG_ 1477 PrsnlMdEVPedMpCstmAvFlg1 "ENM";
BA_ "SignalLongName" SG_ 1477 PrsnlMdEVPedMpCstmAvFlg1 "Personal Mode Electric Vehicle Pedal Map Customization Availability Flag 1";
BA_ "SignalType" SG_ 1477 OnePedDrvCstSetAvlFlg7 "ENM";
BA_ "SignalLongName" SG_ 1477 OnePedDrvCstSetAvlFlg7 "One Pedal Driving Customization Setting Availability Flag 7";
BA_ "SignalType" SG_ 1477 OnePedDrvCstSetAvlFlg6 "ENM";
BA_ "SignalLongName" SG_ 1477 OnePedDrvCstSetAvlFlg6 "One Pedal Driving Customization Setting Availability Flag 6";
BA_ "SignalType" SG_ 1477 OnePedDrvCstSetAvlFlg5 "ENM";
BA_ "SignalLongName" SG_ 1477 OnePedDrvCstSetAvlFlg5 "One Pedal Driving Customization Setting Availability Flag 5";
BA_ "SignalType" SG_ 1477 OnePedDrvCstSetAvlFlg4 "ENM";
BA_ "SignalLongName" SG_ 1477 OnePedDrvCstSetAvlFlg4 "One Pedal Driving Customization Setting Availability Flag 4";
BA_ "SignalType" SG_ 1477 PrsnlMdEngyRegnCstmAvFlg3 "ENM";
BA_ "SignalLongName" SG_ 1477 PrsnlMdEngyRegnCstmAvFlg3 "Personal Mode Energy Regeneration Customization Availability Flag 3";
BA_ "SignalType" SG_ 1477 PrsnlMdEngyRegnCstmAvFlg2 "ENM";
BA_ "SignalLongName" SG_ 1477 PrsnlMdEngyRegnCstmAvFlg2 "Personal Mode Energy Regeneration Customization Availability Flag 2";
BA_ "SignalType" SG_ 1477 PrsnlMdEngyRegnCstmAvFlg1 "ENM";
BA_ "SignalLongName" SG_ 1477 PrsnlMdEngyRegnCstmAvFlg1 "Personal Mode Energy Regeneration Customization Availability Flag 1";
BA_ "SignalType" SG_ 1477 PrsnlMdEVPedMpCstmSetAv "ENM";
BA_ "SignalLongName" SG_ 1477 PrsnlMdEVPedMpCstmSetAv "Personal Mode Electric Vehicle Pedal Map Customization Setting Available";
BA_ "SignalType" SG_ 1477 PrsnlMdEVPedMpCstmAvFlg7 "ENM";
BA_ "SignalLongName" SG_ 1477 PrsnlMdEVPedMpCstmAvFlg7 "Personal Mode Electric Vehicle Pedal Map Customization Availability Flag 7";
BA_ "SignalType" SG_ 1477 PrsnlMdEVPedMpCstmAvFlg6 "ENM";
BA_ "SignalLongName" SG_ 1477 PrsnlMdEVPedMpCstmAvFlg6 "Personal Mode Electric Vehicle Pedal Map Customization Availability Flag 6";
BA_ "SignalType" SG_ 1477 PrsnlMdEVPedMpCstmAvFlg5 "ENM";
BA_ "SignalLongName" SG_ 1477 PrsnlMdEVPedMpCstmAvFlg5 "Personal Mode Electric Vehicle Pedal Map Customization Availability Flag 5";
BA_ "SignalType" SG_ 1477 PrsnlMdEVPedMpCstmAvFlg4 "ENM";
BA_ "SignalLongName" SG_ 1477 PrsnlMdEVPedMpCstmAvFlg4 "Personal Mode Electric Vehicle Pedal Map Customization Availability Flag 4";
BA_ "SignalType" SG_ 1496 PwrFrtStrgeCmptClsrCstAvlFlg2 "ENM";
BA_ "SignalLongName" SG_ 1496 PwrFrtStrgeCmptClsrCstAvlFlg2 "Power Front Storage Compartment Closure Customization Availability Flag 2";
BA_ "SignalType" SG_ 1496 PwrFrtStrgeCmptClsrCstAvlFlg1 "ENM";
BA_ "SignalLongName" SG_ 1496 PwrFrtStrgeCmptClsrCstAvlFlg1 "Power Front Storage Compartment Closure Customization Availability Flag 1";
BA_ "SignalType" SG_ 1496 PrsnlMdEngyRegnCstmSetAv "ENM";
BA_ "SignalLongName" SG_ 1496 PrsnlMdEngyRegnCstmSetAv "Personal Mode Energy Regeneration Customization Setting Available";
BA_ "SignalType" SG_ 1496 PrsnlMdEngyRegnCstmAvFlg7 "ENM";
BA_ "SignalLongName" SG_ 1496 PrsnlMdEngyRegnCstmAvFlg7 "Personal Mode Energy Regeneration Customization Availability Flag 7";
BA_ "SignalType" SG_ 1496 PrsnlMdEngyRegnCstmAvFlg6 "ENM";
BA_ "SignalLongName" SG_ 1496 PrsnlMdEngyRegnCstmAvFlg6 "Personal Mode Energy Regeneration Customization Availability Flag 6";
BA_ "SignalType" SG_ 1496 PrsnlMdEngyRegnCstmAvFlg5 "ENM";
BA_ "SignalLongName" SG_ 1496 PrsnlMdEngyRegnCstmAvFlg5 "Personal Mode Energy Regeneration Customization Availability Flag 5";
BA_ "SignalType" SG_ 1496 PrsnlMdEngyRegnCstmAvFlg4 "ENM";
BA_ "SignalLongName" SG_ 1496 PrsnlMdEngyRegnCstmAvFlg4 "Personal Mode Energy Regeneration Customization Availability Flag 4";
BA_ "SignalType" SG_ 1496 VirtCtlAccCktCtlAval "ENM";
BA_ "SignalLongName" SG_ 1496 VirtCtlAccCktCtlAval "Virtual Control Accessory Circuit Control Available";
BA_ "SignalType" SG_ 1496 PwrFrtStrgeCmptClsrCstSetAval "ENM";
BA_ "SignalLongName" SG_ 1496 PwrFrtStrgeCmptClsrCstSetAval "Power Front Storage Compartment Closure Customization Setting Available";
BA_ "SignalType" SG_ 1496 PwrFrtStrgeCmptClsrCstAvlFlg7 "ENM";
BA_ "SignalLongName" SG_ 1496 PwrFrtStrgeCmptClsrCstAvlFlg7 "Power Front Storage Compartment Closure Customization Availability Flag 7";
BA_ "SignalType" SG_ 1496 PwrFrtStrgeCmptClsrCstAvlFlg6 "ENM";
BA_ "SignalLongName" SG_ 1496 PwrFrtStrgeCmptClsrCstAvlFlg6 "Power Front Storage Compartment Closure Customization Availability Flag 6";
BA_ "SignalType" SG_ 1496 PwrFrtStrgeCmptClsrCstAvlFlg5 "ENM";
BA_ "SignalLongName" SG_ 1496 PwrFrtStrgeCmptClsrCstAvlFlg5 "Power Front Storage Compartment Closure Customization Availability Flag 5";
BA_ "SignalType" SG_ 1496 PwrFrtStrgeCmptClsrCstAvlFlg4 "ENM";
BA_ "SignalLongName" SG_ 1496 PwrFrtStrgeCmptClsrCstAvlFlg4 "Power Front Storage Compartment Closure Customization Availability Flag 4";
BA_ "SignalType" SG_ 1496 PwrFrtStrgeCmptClsrCstAvlFlg3 "ENM";
BA_ "SignalLongName" SG_ 1496 PwrFrtStrgeCmptClsrCstAvlFlg3 "Power Front Storage Compartment Closure Customization Availability Flag 3";
BA_ "SignalType" SG_ 1496 VirtOnePedDrvUserCtlAllwd "ENM";
BA_ "SignalLongName" SG_ 1496 VirtOnePedDrvUserCtlAllwd "Virtual One Pedal Driving User Control Allowed";
BA_ "SignalType" SG_ 1496 VirtOnePedDrvCtlAval "ENM";
BA_ "SignalLongName" SG_ 1496 VirtOnePedDrvCtlAval "Virtual One Pedal Driving Control Available";
BA_ "SignalType" SG_ 1496 VirtCtlAuxAlrmSnsCtlAval "ENM";
BA_ "SignalLongName" SG_ 1496 VirtCtlAuxAlrmSnsCtlAval "Virtual Control Auxiliary Alarm Sensor Control Available";
BA_ "SignalLongName" SG_ 1496 HdOpnShftrLckdHldBrkTmVal "Hood Open Shifter Locked Hold Brake Time Value";
BA_ "SignalLongName" SG_ 1504 HiVltgBatPrcndtngEstdEngyToCmpt "High Voltage Battery Preconditioning Estimated Energy To Complete";
BA_ "SignalLongName" SG_ 1504 DispdEstdCbnTemp "Displayed Estimated Cabin Temperature";
BA_ "SignalType" SG_ 1504 DispdEstdCbnTemp_Inv "ENM";
BA_ "SignalLongName" SG_ 1504 DispdEstdCbnTemp_Inv "Displayed Estimated Cabin Temperature Invalid";
BA_ "SignalType" SG_ 1504 HiVltgBatDispTempLvlPct_DuD "ENM";
BA_ "SignalLongName" SG_ 1504 HiVltgBatDispTempLvlPct_DuD "High Voltage Battery Display Temperature Level Percent Don't Use Data";
BA_ "SignalLongName" SG_ 1504 CbnPrcndtngDsbldSOCLim "Cabin Preconditioning Disabled State of Charge Limit";
BA_ "SignalLongName" SG_ 1504 HiVltgBatDispTempLvlPct "High Voltage Battery Display Temperature Level Percent";
BA_ "SignalLongName" SG_ 1504 HiVltgBatPrcndtngEstdTmToCmpt "High Voltage Battery Preconditioning Estimated Time To Complete";
BA_ "SignalLongName" SG_ 1504 CbnPrcndtngSchTempCstSetVal "Cabin Preconditioning Schedule Temperature Customization Setting Value";
BA_ "SignalType" SG_ 1504 CbnPrcndtngSts "ENM";
BA_ "SignalLongName" SG_ 1504 CbnPrcndtngSts "Cabin Preconditioning Status";
BA_ "SignalType" SG_ 1504 HiVltgBatPrcndtngSts "ENM";
BA_ "SignalLongName" SG_ 1504 HiVltgBatPrcndtngSts "High Voltage Battery Preconditioning Status";
BA_ "SignalType" SG_ 1504 HiVltgBatPrcndtngSts_DuD "ENM";
BA_ "SignalLongName" SG_ 1504 HiVltgBatPrcndtngSts_DuD "High Voltage Battery Preconditioning Status Don't Use Data";
BA_ "SignalType" SG_ 1504 CbnPrcndtngSchTempCstSetAval "ENM";
BA_ "SignalLongName" SG_ 1504 CbnPrcndtngSchTempCstSetAval "Cabin Preconditioning Schedule Temperature Customization Setting Available";
BA_ "SignalType" SG_ 1504 OnePedDrvCstCurrSetVal "ENM";
BA_ "SignalLongName" SG_ 1504 OnePedDrvCstCurrSetVal "One Pedal Driving Customization Current Setting Value";
BA_ "SignalType" SG_ 1504 HiVltgBatLoSOCIndReq "ENM";
BA_ "SignalLongName" SG_ 1504 HiVltgBatLoSOCIndReq "High Voltage Battery Low State of Charge Indication Request";
BA_ "SignalType" SG_ 1504 HiVltgBatLoSOCIndReq_DuD "ENM";
BA_ "SignalLongName" SG_ 1504 HiVltgBatLoSOCIndReq_DuD "High Voltage Battery Low State of Charge Indication Request Don't Use Data";
BA_ "SignalType" SG_ 1505 OnePedDrvCurrSeltnVal "ENM";
BA_ "SignalLongName" SG_ 1505 OnePedDrvCurrSeltnVal "One Pedal Driving Current Selection Value";
BA_ "SignalType" SG_ 1505 FrtStrgeCmptClsrLckSts "ENM";
BA_ "SignalLongName" SG_ 1505 FrtStrgeCmptClsrLckSts "Serial Data 2 Protected : Front Storage Compartment Closure Lock Status Authenticated";
BA_ "SignalType" SG_ 1505 AuxAlrmSnsCurrSeltnVal "ENM";
BA_ "SignalLongName" SG_ 1505 AuxAlrmSnsCurrSeltnVal "Auxiliary Alarm Sensor Current Selection Value";
BA_ "SignalType" SG_ 1505 PwrFrtStrgeCmptClsrCstCurSetVal "ENM";
BA_ "SignalLongName" SG_ 1505 PwrFrtStrgeCmptClsrCstCurSetVal "Power Front Storage Compartment Closure Customization Current Setting Value";
BA_ "SignalType" SG_ 1505 VirtCtlAccCkt3CurrSeltnVal "ENM";
BA_ "SignalLongName" SG_ 1505 VirtCtlAccCkt3CurrSeltnVal "Virtual Control Accessory Circuit 3 Current Selection Value";
BA_ "SignalType" SG_ 1505 VirtCtlAccCkt2CurrSeltnVal "ENM";
BA_ "SignalLongName" SG_ 1505 VirtCtlAccCkt2CurrSeltnVal "Virtual Control Accessory Circuit 2 Current Selection Value";
BA_ "SignalType" SG_ 1505 VirtCtlAccCkt1CurrSeltnVal "ENM";
BA_ "SignalLongName" SG_ 1505 VirtCtlAccCkt1CurrSeltnVal "Virtual Control Accessory Circuit 1 Current Selection Value";
BA_ "SignalType" SG_ 1505 OnePedDrvWrnIndReq "ENM";
BA_ "SignalLongName" SG_ 1505 OnePedDrvWrnIndReq "One Pedal Driving Warning Indication Request";
BA_ "SignalType" SG_ 1505 HVDCFstChrgPerfLtdIndOn "ENM";
BA_ "SignalLongName" SG_ 1505 HVDCFstChrgPerfLtdIndOn "High Voltage DC Fast Charge Performance Limited Indication On";
BA_ "SignalType" SG_ 1505 VirtCtlAccCkt6CurrSeltnVal "ENM";
BA_ "SignalLongName" SG_ 1505 VirtCtlAccCkt6CurrSeltnVal "Virtual Control Accessory Circuit 6 Current Selection Value";
BA_ "SignalType" SG_ 1505 VirtCtlAccCkt5CurrSeltnVal "ENM";
BA_ "SignalLongName" SG_ 1505 VirtCtlAccCkt5CurrSeltnVal "Virtual Control Accessory Circuit 5 Current Selection Value";
BA_ "SignalType" SG_ 1505 VirtCtlAccCkt4CurrSeltnVal "ENM";
BA_ "SignalLongName" SG_ 1505 VirtCtlAccCkt4CurrSeltnVal "Virtual Control Accessory Circuit 4 Current Selection Value";
BA_ "SignalLongName" SG_ 1505 LnchCtlBrkPresHiResVal "Launch Control Brake Pressure High Resolution Value";
BA_ "SignalType" SG_ 1505 OnePedDrvIndOn "ENM";
BA_ "SignalLongName" SG_ 1505 OnePedDrvIndOn "One Pedal Driving Indication On";
BA_ "SignalType" SG_ 1505 HVDCFstChrgPrepCmpltIndOn "ENM";
BA_ "SignalLongName" SG_ 1505 HVDCFstChrgPrepCmpltIndOn "High Voltage DC Fast Charge Preparation Complete Indication On";
BA_ "SignalType" SG_ 1505 ADASLtdCpbltyStatRsnIndReq "ENM";
BA_ "SignalLongName" SG_ 1505 ADASLtdCpbltyStatRsnIndReq "Advanced Driver Assist Systems Limited Capability State Reason Indication Request";
BA_ "SignalType" SG_ 1505 PrplSysMaxPwrModeUnvRsn "ENM";
BA_ "SignalLongName" SG_ 1505 PrplSysMaxPwrModeUnvRsn "Propulsion System Max Power Mode Unavailable Reason";
BA_ "SignalType" SG_ 1505 ADASMsgDispLocLtdPerfRsnInd "ENM";
BA_ "SignalLongName" SG_ 1505 ADASMsgDispLocLtdPerfRsnInd "Advanced Driver Assist Systems Message Display Location Limited Performance Reason Indication";
BA_ "SignalType" SG_ 1505 ADASLtdCpbltyStatIndReq "ENM";
BA_ "SignalLongName" SG_ 1505 ADASLtdCpbltyStatIndReq "Advanced Driver Assist Systems Limited Capability State Indication Request";
BA_ "SignalType" SG_ 929 B2RChmEvntStat "ENM";
BA_ "SignalLongName" SG_ 929 B2RChmEvntStat "Buckle to Ride Chime Event State";
BA_ "SignalLongName" SG_ 206 POFT_PstnOfstFrmTrmLF "Position Offset From Trim : Position Offset From Trim Left Front";
BA_ "SignalLongName" SG_ 206 POFT_PstnOfstFrmTrmLR "Position Offset From Trim : Position Offset From Trim Left Rear";
BA_ "SignalType" SG_ 206 POFT_PstnOfstFrmTrmLF_Inv "ENM";
BA_ "SignalLongName" SG_ 206 POFT_PstnOfstFrmTrmLF_Inv "Position Offset From Trim : Position Offset From Trim Left Front Invalid";
BA_ "SignalLongName" SG_ 206 POFT_PstnOfstFrmTrmRF "Position Offset From Trim : Position Offset From Trim Right Front";
BA_ "SignalType" SG_ 206 POFT_PstnOfstFrmTrmLR_Inv "ENM";
BA_ "SignalLongName" SG_ 206 POFT_PstnOfstFrmTrmLR_Inv "Position Offset From Trim : Position Offset From Trim Left Rear Invalid";
BA_ "SignalLongName" SG_ 206 POFT_PstnOfstFrmTrmRR "Position Offset From Trim : Position Offset From Trim Right Rear";
BA_ "SignalType" SG_ 206 POFT_PstnOfstFrmTrmRF_Inv "ENM";
BA_ "SignalLongName" SG_ 206 POFT_PstnOfstFrmTrmRF_Inv "Position Offset From Trim : Position Offset From Trim Right Front Invalid";
BA_ "SignalType" SG_ 206 POFT_PstnOfstFrmTrmRR_Inv "ENM";
BA_ "SignalLongName" SG_ 206 POFT_PstnOfstFrmTrmRR_Inv "Position Offset From Trim : Position Offset From Trim Right Rear Invalid";
BA_ "SignalType" SG_ 206 RideHghtMaxPwrModeOvrrd "ENM";
BA_ "SignalLongName" SG_ 206 RideHghtMaxPwrModeOvrrd "Ride Height Max Power Mode Override";
BA_ "SignalType" SG_ 1535 PwrFrtStrgeCmptClsrCstChgSetReq "ENM";
BA_ "SignalLongName" SG_ 1535 PwrFrtStrgeCmptClsrCstChgSetReq "Power Front Storage Compartment Closure Customization Change Setting Request";
BA_ "SignalType" SG_ 1246 ElecRateSchedSsnStrtMthReq "ENM";
BA_ "SignalLongName" SG_ 1246 ElecRateSchedSsnStrtMthReq "Electric Rate Season Settings Request : Electric Rate Schedule Season Start Month Request";
BA_ "SignalLongName" SG_ 1246 ElecRateSchedSsnStrtDyReq "Electric Rate Season Settings Request : Electric Rate Schedule Season Start Day Request";
BA_ "SignalType" SG_ 1246 ElecRateSchedSsnReq "ENM";
BA_ "SignalLongName" SG_ 1246 ElecRateSchedSsnReq "Electric Rate Season Settings Request : Electric Rate Schedule Season Request";
BA_ "SignalType" SG_ 1246 InfoFrtLtStHtdCushBkLvlReq "ENM";
BA_ "SignalLongName" SG_ 1246 InfoFrtLtStHtdCushBkLvlReq "Infotainment Front Left Seat Heated Vented Request : Infotainment Front Left Seat Heated Cushion and Back Level Request";
BA_ "SignalType" SG_ 1246 InfoFrtLtStHtdBkLvlReq "ENM";
BA_ "SignalLongName" SG_ 1246 InfoFrtLtStHtdBkLvlReq "Infotainment Front Left Seat Heated Vented Request : Infotainment Front Left Seat Heated Back Level Request";
BA_ "SignalType" SG_ 1246 InfoFrtRtStHtdCushBkLvlReq "ENM";
BA_ "SignalLongName" SG_ 1246 InfoFrtRtStHtdCushBkLvlReq "Infotainment Front Right Seat Heated Vented Request : Infotainment Front Right Seat Heated Cushion and Back Level Request";
BA_ "SignalType" SG_ 1246 InfoFrtRtStHtdBkLvlReq "ENM";
BA_ "SignalLongName" SG_ 1246 InfoFrtRtStHtdBkLvlReq "Infotainment Front Right Seat Heated Vented Request : Infotainment Front Right Seat Heated Back Level Request";
BA_ "SignalType" SG_ 1246 InfoFrtLtStVntCoolLvlReq "ENM";
BA_ "SignalLongName" SG_ 1246 InfoFrtLtStVntCoolLvlReq "Infotainment Front Left Seat Heated Vented Request : Infotainment Front Left Seat Vented or Cooled Level Request";
BA_ "SignalType" SG_ 1246 InfoRrLtStHtdBkLvlReq "ENM";
BA_ "SignalLongName" SG_ 1246 InfoRrLtStHtdBkLvlReq "Infotainment Rear Left Seat Heated Vented Request : Infotainment Rear Left Seat Heated Back Level Request";
BA_ "SignalType" SG_ 1246 InfoFrtRtStVntCoolLvlReq "ENM";
BA_ "SignalLongName" SG_ 1246 InfoFrtRtStVntCoolLvlReq "Infotainment Front Right Seat Heated Vented Request : Infotainment Front Right Seat Vented or Cooled Level Request";
BA_ "SignalType" SG_ 1246 InfoRrRtStHtdBkLvlReq "ENM";
BA_ "SignalLongName" SG_ 1246 InfoRrRtStHtdBkLvlReq "Infotainment Rear Right Seat Heated Vented Request : Infotainment Rear Right Seat Heated Back Level Request";
BA_ "SignalType" SG_ 1246 InfoRrLtStVntCoolLvlReq "ENM";
BA_ "SignalLongName" SG_ 1246 InfoRrLtStVntCoolLvlReq "Infotainment Rear Left Seat Heated Vented Request : Infotainment Rear Left Seat Vented or Cooled Level Request";
BA_ "SignalType" SG_ 1246 InfoRrLtStHtdCushBkLvlReq "ENM";
BA_ "SignalLongName" SG_ 1246 InfoRrLtStHtdCushBkLvlReq "Infotainment Rear Left Seat Heated Vented Request : Infotainment Rear Left Seat Heated Cushion and Back Level Request";
BA_ "SignalLongName" SG_ 1246 CbnPrcndtngSchTempCstSetReq "Cabin Preconditioning Schedule Temperature Customization Setting Request";
BA_ "SignalType" SG_ 1246 InfoRrRtStVntCoolLvlReq "ENM";
BA_ "SignalLongName" SG_ 1246 InfoRrRtStVntCoolLvlReq "Infotainment Rear Right Seat Heated Vented Request : Infotainment Rear Right Seat Vented or Cooled Level Request";
BA_ "SignalType" SG_ 1246 InfoRrRtStHtdCushBkLvlReq "ENM";
BA_ "SignalLongName" SG_ 1246 InfoRrRtStHtdCushBkLvlReq "Infotainment Rear Right Seat Heated Vented Request : Infotainment Rear Right Seat Heated Cushion and Back Level Request";
BA_ "SignalType" SG_ 1246 OnePedDrvCstChgSetReq "ENM";
BA_ "SignalLongName" SG_ 1246 OnePedDrvCstChgSetReq "One Pedal Driving Customization Change Setting Request";
BA_ "SignalType" SG_ 1246 InfoHtdStrgWhlLvlReq "ENM";
BA_ "SignalLongName" SG_ 1246 InfoHtdStrgWhlLvlReq "Infotainment Heated Steering Wheel Level Request";
BA_ "SignalType" SG_ 1246 VirtCtlAccCkt2Req "ENM";
BA_ "SignalLongName" SG_ 1246 VirtCtlAccCkt2Req "Virtual Control Accessory Circuit 2 Request";
BA_ "SignalType" SG_ 1246 VirtCtlAccCkt1Req "ENM";
BA_ "SignalLongName" SG_ 1246 VirtCtlAccCkt1Req "Virtual Control Accessory Circuit 1 Request";
BA_ "SignalType" SG_ 1229 VirtCtlAccCkt5Req "ENM";
BA_ "SignalLongName" SG_ 1229 VirtCtlAccCkt5Req "Virtual Control Accessory Circuit 5 Request";
BA_ "SignalType" SG_ 1229 VirtCtlAccCkt4Req "ENM";
BA_ "SignalLongName" SG_ 1229 VirtCtlAccCkt4Req "Virtual Control Accessory Circuit 4 Request";
BA_ "SignalType" SG_ 1229 VirtCtlAccCkt3Req "ENM";
BA_ "SignalLongName" SG_ 1229 VirtCtlAccCkt3Req "Virtual Control Accessory Circuit 3 Request";
BA_ "SignalType" SG_ 1229 VirtOnePedDrvReq "ENM";
BA_ "SignalLongName" SG_ 1229 VirtOnePedDrvReq "Virtual One Pedal Driving Request";
BA_ "SignalType" SG_ 1229 VirtCtlAccCkt6Req "ENM";
BA_ "SignalLongName" SG_ 1229 VirtCtlAccCkt6Req "Virtual Control Accessory Circuit 6 Request";
BA_ "SignalType" SG_ 1229 HVDCFstChrgSoonReq "ENM";
BA_ "SignalLongName" SG_ 1229 HVDCFstChrgSoonReq "High Voltage DC Fast Charge Soon Request";
BA_ "SignalType" SG_ 1229 CustMdEngyRegnCstChngSetReq "ENM";
BA_ "SignalLongName" SG_ 1229 CustMdEngyRegnCstChngSetReq "Custom Mode Energy Regeneration Customization Change Setting Request";
BA_ "SignalType" SG_ 1229 CustMdEVPedMpCstChngSetReq "ENM";
BA_ "SignalLongName" SG_ 1229 CustMdEVPedMpCstChngSetReq "Custom Mode Electric Vehicle Pedal Map Customization Change Setting Request";
BA_ "SignalType" SG_ 1229 CbnPrcndtngSchTempCstSetReqAtv "ENM";
BA_ "SignalLongName" SG_ 1229 CbnPrcndtngSchTempCstSetReqAtv "Cabin Preconditioning Schedule Temperature Customization Setting Request Active";
BA_ "SignalType" SG_ 1229 ChrgCordThftAlrtCstSetReq "ENM";
BA_ "SignalLongName" SG_ 1229 ChrgCordThftAlrtCstSetReq "Charge Cord Theft Alert Customization Setting Request";
BA_ "SignalType" SG_ 1229 PrsnlMdEngyRegnCstChngSetReq "ENM";
BA_ "SignalLongName" SG_ 1229 PrsnlMdEngyRegnCstChngSetReq "Personal Mode Energy Regeneration Customization Change Setting Request";
BA_ "SignalType" SG_ 1229 PrsnlMdEVPedMpCstChngSetReq "ENM";
BA_ "SignalLongName" SG_ 1229 PrsnlMdEVPedMpCstChngSetReq "Personal Mode Electric Vehicle Pedal Map Customization Change Setting Request";
BA_ "SignalType" SG_ 1229 HVBatSOCDspHdlmpCstChgSetReq "ENM";
BA_ "SignalLongName" SG_ 1229 HVBatSOCDspHdlmpCstChgSetReq "High Voltage Battery State of Charge Display Headlamp Customization Change Setting Request";
BA_ "SignalType" SG_ 931 RmtVehStrtPwrtrnFlrRsn "ENM";
BA_ "SignalLongName" SG_ 931 RmtVehStrtPwrtrnFlrRsn "Remote Vehicle Start Powertrain Failure Reason";
BA_ "SignalType" SG_ 931 RmtVehStrtBdyFlrRsn "ENM";
BA_ "SignalLongName" SG_ 931 RmtVehStrtBdyFlrRsn "Remote Vehicle Start Body Failure Reason";
BA_ "SignalLongName" SG_ 1837 TnDrvrOvrspdWrnRmtCstLvlChgStRq "Teen Driver Overspeed Warning Remote Customization Request : Teen Driver Overspeed Warning Remote Customization Level Change Setting Request";
BA_ "SignalType" SG_ 1837 TlmHVDCFstChrgSoonReq "ENM";
BA_ "SignalLongName" SG_ 1837 TlmHVDCFstChrgSoonReq "Telematics High Voltage DC Fast Charge Soon Request";
BA_ "SignalType" SG_ 1837 TnDrvrOvrspdWrnRmtCstChgSetReq "ENM";
BA_ "SignalLongName" SG_ 1837 TnDrvrOvrspdWrnRmtCstChgSetReq "Teen Driver Overspeed Warning Remote Customization Request : Teen Driver Overspeed Warning Remote Customization Change Setting Request";
BA_ "SignalType" SG_ 1837 TnDrStBltShIntlkRtCstLvChgSetRq "ENM";
BA_ "SignalLongName" SG_ 1837 TnDrStBltShIntlkRtCstLvChgSetRq "Teen Driver Seat Belt Shift Interlock Remote Customization Level Change Setting Request";
BA_ "SignalType" SG_ 940 VirtKeyCmdFailRsnReq "ENM";
BA_ "SignalLongName" SG_ 940 VirtKeyCmdFailRsnReq "Virtual Key Command Fail Reason Request";
BA_ "SignalType" SG_ 1467 SuprCruzSbscrptnActv "ENM";
BA_ "SignalLongName" SG_ 1467 SuprCruzSbscrptnActv "Super Cruise Subscription Active";
BA_ "SignalLongName" SG_ 714 WhlTrqTotMaxPsblVal "Wheel Torque Total Maximum Possible Value";
BA_ "SignalLongName" SG_ 714 WhlTrqPctgOfTotTrqLF "Wheel Torque Percentage of Total Torque Left Front";
BA_ "SignalLongName" SG_ 714 WhlTrqPctgOfTotTrqLR "Wheel Torque Percentage of Total Torque Left Rear";
BA_ "SignalLongName" SG_ 714 WhlTrqPctgOfTotTrqRF "Wheel Torque Percentage of Total Torque Right Front";
BA_ "SignalLongName" SG_ 714 WhlTrqPctgOfTotTrqRR "Wheel Torque Percentage of Total Torque Right Rear";
BA_ "SignalLongName" SG_ 714 WhlTrqTotDlvdPct "Wheel Torque Total Delivered Percent";
BA_ "SignalType" SG_ 714 LIB1TempFlt "ENM";
BA_ "SignalLongName" SG_ 714 LIB1TempFlt "Lithium Ion Battery 1 Temperature Fault";
BA_ "SignalType" SG_ 714 LIB1TempFlt_Inv "ENM";
BA_ "SignalLongName" SG_ 714 LIB1TempFlt_Inv "Lithium Ion Battery 1 Temperature Fault Invalid";
BA_ "SignalLongName" SG_ 1468 ClmCtlTmToRchCbnCmfEstd "Climate Control Time To Reach Cabin Comfort Estimated";
BA_ "SignalLongName" SG_ 1468 ClmCtlPwrToMntCbnCmf "Climate Control Power To Maintain Cabin Comfort";
BA_ "SignalLongName" SG_ 1468 ClmCtlPwrToRchCbnCmf "Climate Control Power To Reach Cabin Comfort";
BA_ "SignalLongName" SG_ 1469 SuprRmtPrkMnvrPrgs "Supervised Remote Parking Warning Indications : Supervised Remote Parking Maneuver Progress";
BA_ "SignalType" SG_ 1469 IndHtrSet "ENM";
BA_ "SignalLongName" SG_ 1469 IndHtrSet "Indication Heater Setting";
BA_ "SignalType" SG_ 1469 ICMTrngOncmgTrfcChmEvntStat "ENM";
BA_ "SignalLongName" SG_ 1469 ICMTrngOncmgTrfcChmEvntStat "Intersection Collision Mitigation Turning Oncoming Traffic Chime Event State";
BA_ "SignalType" SG_ 1469 ICMRtChmEvntStat "ENM";
BA_ "SignalLongName" SG_ 1469 ICMRtChmEvntStat "Intersection Collision Mitigation Right Chime Event State";
BA_ "SignalType" SG_ 1469 ICMLtChmEvntStat "ENM";
BA_ "SignalLongName" SG_ 1469 ICMLtChmEvntStat "Intersection Collision Mitigation Left Chime Event State";
BA_ "SignalType" SG_ 1469 SuprRmtPrkWrnIndReq "ENM";
BA_ "SignalLongName" SG_ 1469 SuprRmtPrkWrnIndReq "Supervised Remote Parking Warning Indications : Supervised Remote Parking Warning Indication Request";
BA_ "SignalType" SG_ 1469 SuprRmtPrkFcsReq "ENM";
BA_ "SignalLongName" SG_ 1469 SuprRmtPrkFcsReq "Supervised Remote Parking Warning Indications : Supervised Remote Parking Focus Request";
BA_ "SignalType" SG_ 1469 SuprRmtPrkAutoStrgIconReq "ENM";
BA_ "SignalLongName" SG_ 1469 SuprRmtPrkAutoStrgIconReq "Supervised Remote Parking Warning Indications : Supervised Remote Parking Auto Steering Icon Request";
BA_ "SignalType" SG_ 1469 SuprRmtPrkUnabletoCnctExtReq "ENM";
BA_ "SignalLongName" SG_ 1469 SuprRmtPrkUnabletoCnctExtReq "Supervised Remote Parking Unable To Connect Request : Supervised Remote Parking Unable to Connect Exit Request";
BA_ "SignalType" SG_ 1469 SuprRmtPrkSptSeltnRmtReq "ENM";
BA_ "SignalLongName" SG_ 1469 SuprRmtPrkSptSeltnRmtReq "Supervised Remote Parking Spot Selection Request : Supervised Remote Parking Spot Selection Remote Request";
BA_ "SignalType" SG_ 1469 SuprRmtPrkSptSeltnKeepLkReq "ENM";
BA_ "SignalLongName" SG_ 1469 SuprRmtPrkSptSeltnKeepLkReq "Supervised Remote Parking Spot Selection Request : Supervised Remote Parking Spot Selection Keep Looking Request";
BA_ "SignalType" SG_ 1469 SuprRmtPrkSptSeltnAcceptReq "ENM";
BA_ "SignalLongName" SG_ 1469 SuprRmtPrkSptSeltnAcceptReq "Supervised Remote Parking Spot Selection Request : Supervised Remote Parking Spot Selection Accept Request";
BA_ "SignalType" SG_ 1469 SuprRmtPrkDctvSftBtnReq "ENM";
BA_ "SignalLongName" SG_ 1469 SuprRmtPrkDctvSftBtnReq "Supervised Remote Parking Deactivation Soft Button Request";
BA_ "SignalType" SG_ 1469 SuprRmtPrkUnabletoCnctTryAgnReq "ENM";
BA_ "SignalLongName" SG_ 1469 SuprRmtPrkUnabletoCnctTryAgnReq "Supervised Remote Parking Unable To Connect Request : Supervised Remote Parking Unable to Connect Try Again Request";
BA_ "SignalLongName" SG_ 1470 IBS12VBatVlt "Intelligent Battery Sensor 12V Battery Information : IBS 12V Battery Voltage";
BA_ "SignalLongName" SG_ 1470 IBS12VEstdBatTemp "Intelligent Battery Sensor 12V Battery Information : IBS 12V Estimated Battery Temperature";
BA_ "SignalLongName" SG_ 1470 IBSRwBatSOC "Intelligent Battery Sensor 12V Battery Information : IBS 12V Battery State of Charge";
BA_ "SignalType" SG_ 1470 IBS12VEstdBatTemp_Inv "ENM";
BA_ "SignalLongName" SG_ 1470 IBS12VEstdBatTemp_Inv "Intelligent Battery Sensor 12V Battery Information : IBS 12V Estimated Battery Temperature Invalid";
BA_ "SignalType" SG_ 1470 RrStrgOprtlStsAuth "ENM";
BA_ "SignalLongName" SG_ 1470 RrStrgOprtlStsAuth "Serial Data 58 Protected : Rear Steering Operational Status Authenticated";
BA_ "SignalType" SG_ 1470 RrStrgAlgnCmpltAuth "ENM";
BA_ "SignalLongName" SG_ 1470 RrStrgAlgnCmpltAuth "Serial Data 58 Protected : Rear Steering Alignment Complete Authenticated";
BA_ "SignalType" SG_ 1470 RrStrgActlPerfMode "ENM";
BA_ "SignalLongName" SG_ 1470 RrStrgActlPerfMode "Serial Data 58 Protected : Rear Steering Actual Performance Mode";
BA_ "SignalType" SG_ 1470 RrStrgActlModeAuth "ENM";
BA_ "SignalLongName" SG_ 1470 RrStrgActlModeAuth "Serial Data 58 Protected : Rear Steering Actual Mode Authenticated";
BA_ "SignalType" SG_ 1470 RrStrgRdWhlAngAuth_DuD "ENM";
BA_ "SignalLongName" SG_ 1470 RrStrgRdWhlAngAuth_DuD "Serial Data 58 Protected : Rear Steering Road Wheel Angle Authenticated Don't Use Data";
BA_ "SignalLongName" SG_ 1470 RrStrgRdWhlAngAuth "Serial Data 58 Protected : Rear Steering Road Wheel Angle Authenticated";
BA_ "SignalType" SG_ 1470 RrStrgRdWhlAngAuth_Inv "ENM";
BA_ "SignalLongName" SG_ 1470 RrStrgRdWhlAngAuth_Inv "Serial Data 58 Protected : Rear Steering Road Wheel Angle Authenticated Invalid";
BA_ "SignalType" SG_ 1470 CrtsyLgtSmrtIconReqd "ENM";
BA_ "SignalLongName" SG_ 1470 CrtsyLgtSmrtIconReqd "Courtesy Light Smart Icon Requested";
BA_ "SignalLongName" SG_ 1473 ActvTrlrProfLifetmEcon "Active Trailer Profile Lifetime Economy";
BA_ "SignalType" SG_ 1473 ActvTrlrProfLifetmEcon_DuD "ENM";
BA_ "SignalLongName" SG_ 1473 ActvTrlrProfLifetmEcon_DuD "Active Trailer Profile Lifetime Economy Don't Use Data";
BA_ "SignalType" SG_ 1473 PnCStsDisp "ENM";
BA_ "SignalLongName" SG_ 1473 PnCStsDisp "Plug And Charge Status Display";
BA_ "SignalType" SG_ 1473 ActvTrlrProfLifetmEcon_Inv "ENM";
BA_ "SignalLongName" SG_ 1473 ActvTrlrProfLifetmEcon_Inv "Active Trailer Profile Lifetime Economy Invalid";
BA_ "SignalType" SG_ 1473 PTExPrtclFltrMnlRgnSts "ENM";
BA_ "SignalLongName" SG_ 1473 PTExPrtclFltrMnlRgnSts "Powertrain Exhaust Particle Filter Manual Regeneration Status";
BA_ "SignalType" SG_ 1473 ICMWrnIndReq "ENM";
BA_ "SignalLongName" SG_ 1473 ICMWrnIndReq "Intersection Collision Mitigation Warning Indication Request";
BA_ "SignalType" SG_ 1473 EngAftRunIndReq "ENM";
BA_ "SignalLongName" SG_ 1473 EngAftRunIndReq "Engine After Run Indication Request";
BA_ "SignalType" SG_ 1473 PnCEnbldSts "ENM";
BA_ "SignalLongName" SG_ 1473 PnCEnbldSts "Plug And Charge Enabled Status";
BA_ "SignalType" SG_ 1473 AutoCoolServFllIndReq "ENM";
BA_ "SignalLongName" SG_ 1473 AutoCoolServFllIndReq "Automatic Coolant Service Fill Indication Request";
BA_ "SignalType" SG_ 1473 RrStrgModeUnvIndReq "ENM";
BA_ "SignalLongName" SG_ 1473 RrStrgModeUnvIndReq "Rear Steering Mode Unavailable Indication Request";
BA_ "SignalType" SG_ 1473 PwrFrtStrgeCmptMtnSts "ENM";
BA_ "SignalLongName" SG_ 1473 PwrFrtStrgeCmptMtnSts "Power Front Storage Compartment Motion Status";
BA_ "SignalType" SG_ 1473 RrStrgModeSeltnIndOn "ENM";
BA_ "SignalLongName" SG_ 1473 RrStrgModeSeltnIndOn "Rear Steering Mode Selection Indication On";
BA_ "SignalType" SG_ 1473 PTExPrtclFltrWrn3IndOn "ENM";
BA_ "SignalLongName" SG_ 1473 PTExPrtclFltrWrn3IndOn "Powertrain Exhaust Particle Filter Warning 3 Indication On";
BA_ "SignalType" SG_ 1473 HdLmpSmrtCtlPrmtReqd "ENM";
BA_ "SignalLongName" SG_ 1473 HdLmpSmrtCtlPrmtReqd "Head Lamp Smart Control Prompt Requested";
BA_ "SignalType" SG_ 1473 ESCUnvTopDnIndOn "ENM";
BA_ "SignalLongName" SG_ 1473 ESCUnvTopDnIndOn "Electronic Stability Control Unavailable Top Down Indication On";
BA_ "SignalLongName" SG_ 1473 LnchCtlAccelPedVal "Launch Control Accelerator Pedal Value";
BA_ "SignalType" SG_ 1473 RIMObjAtchdIndOn "ENM";
BA_ "SignalLongName" SG_ 1473 RIMObjAtchdIndOn "Rearward Impact Mitigation Object Attached Indication On";
BA_ "SignalType" SG_ 1473 RIMElecPrkBrkRelIndOn "ENM";
BA_ "SignalLongName" SG_ 1473 RIMElecPrkBrkRelIndOn "Rearward Impact Mitigation Electric Park Brake Release Indication On";
BA_ "SignalType" SG_ 1473 UpftrVehStrtEnblIndReq "ENM";
BA_ "SignalLongName" SG_ 1473 UpftrVehStrtEnblIndReq "Upfitter Vehicle Start Enable Indication Request";
BA_ "SignalType" SG_ 1473 MaxPwrModeDndIndOn "ENM";
BA_ "SignalLongName" SG_ 1473 MaxPwrModeDndIndOn "Max Power Mode Denied Indication On";
BA_ "SignalType" SG_ 1473 DrvModeConfIndReq "ENM";
BA_ "SignalLongName" SG_ 1473 DrvModeConfIndReq "Drive Mode Confirmation Indication Request";
BA_ "SignalType" SG_ 1892 LnchCtlSts "ENM";
BA_ "SignalLongName" SG_ 1892 LnchCtlSts "Launch Control Information : Launch Control Status";
BA_ "SignalType" SG_ 1892 LnchCtlCchTrgrd "ENM";
BA_ "SignalLongName" SG_ 1892 LnchCtlCchTrgrd "Launch Control Information : Launch Control Coach Triggered";
BA_ "SignalType" SG_ 1892 AmbtLgtGblPrxmtyEnCstCurrSetVal "ENM";
BA_ "SignalLongName" SG_ 1892 AmbtLgtGblPrxmtyEnCstCurrSetVal "Ambient Light Global Proximity Enable Customization Current Setting Value";
BA_ "SignalType" SG_ 1892 LnchCtlUnvRsn "ENM";
BA_ "SignalLongName" SG_ 1892 LnchCtlUnvRsn "Launch Control Information : Launch Control Unavailable Reason";
BA_ "SignalLongName" SG_ 732 PSATIP_PriATActlAuth "Serial Data 19 Protected : Primary Axle Torque Actual Authenticated";
BA_ "SignalType" SG_ 732 PSATIP_PriATActlAuth_Inv "ENM";
BA_ "SignalLongName" SG_ 732 PSATIP_PriATActlAuth_Inv "Serial Data 19 Protected : Primary Axle Torque Actual Authenticated Invalid";
BA_ "SignalLongName" SG_ 732 SSID1P_LngAccelAuth "Serial Data 44 Protected : Longitudinal Acceleration Authenticated";
BA_ "SignalType" SG_ 732 SSID1P_LngAccelAuth_Inv "ENM";
BA_ "SignalLongName" SG_ 732 SSID1P_LngAccelAuth_Inv "Serial Data 44 Protected : Longitudinal Acceleration Authenticated Invalid";
BA_ "SignalLongName" SG_ 732 VICMI3P_ArbdAccPPPriAuth "Serial Data 50 Protected : Arbitrated Accelerator Pedal Position Primary Authenticated";
BA_ "SignalLongName" SG_ 732 LIB1AvgTemp "Lithium Ion Battery 1 Average Temperature";
BA_ "SignalType" SG_ 732 LIB1AvgTemp_Inv "ENM";
BA_ "SignalLongName" SG_ 732 LIB1AvgTemp_Inv "Lithium Ion Battery 1 Average Temperature Invalid";
BA_ "SignalLongName" SG_ 196 FCATgtObjSeltnDispHght "Forward Collision Alert Target Object Selection Display : Forward Collision Alert Target Object Selection Display Height";
BA_ "SignalLongName" SG_ 196 FCATgtObjSeltnDispLatDist "Forward Collision Alert Target Object Selection Display : Forward Collision Alert Target Object Selection Display Lateral Distance";
BA_ "SignalLongName" SG_ 196 FCATgtObjSeltnDispLngDist "Forward Collision Alert Target Object Selection Display : Forward Collision Alert Target Object Selection Display Longitudinal Distance";
BA_ "SignalLongName" SG_ 196 FCATgtObjSeltnDispWdth "Forward Collision Alert Target Object Selection Display : Forward Collision Alert Target Object Selection Display Width";
BA_ "SignalType" SG_ 196 FCATgtObjSeltnDispSnsrCnfd "ENM";
BA_ "SignalLongName" SG_ 196 FCATgtObjSeltnDispSnsrCnfd "Forward Collision Alert Target Object Selection Display : Forward Collision Alert Target Object Selection Display Sensor Confidence";
BA_ "SignalLongName" SG_ 1173 PnCActnReqCertfctNum "Plug And Charge Certificate Action Request : Plug And Charge Action Request Certificate Number";
BA_ "SignalType" SG_ 1173 PnCActnReqCertfctTyp "ENM";
BA_ "SignalLongName" SG_ 1173 PnCActnReqCertfctTyp "Plug And Charge Certificate Action Request : Plug And Charge Action Request Certificate Type";
BA_ "SignalType" SG_ 1173 PnCActnReqCertfctOp "ENM";
BA_ "SignalLongName" SG_ 1173 PnCActnReqCertfctOp "Plug And Charge Certificate Action Request : Plug And Charge Action Request Certificate Operation";
BA_ "SignalType" SG_ 1173 InfoDyNtDispModeSeltnCurrSetVal "ENM";
BA_ "SignalLongName" SG_ 1173 InfoDyNtDispModeSeltnCurrSetVal "Infotainment Day Night Display Mode Selection Current Setting Value";
BA_ "SignalType" SG_ 1173 PnCEnblReq "ENM";
BA_ "SignalLongName" SG_ 1173 PnCEnblReq "Plug And Charge Enable Request";
BA_ "SignalType" SG_ 1893 TrlrProfLifetmEconRstReqd "ENM";
BA_ "SignalLongName" SG_ 1893 TrlrProfLifetmEconRstReqd "Trailer Profile Lifetime Economy Reset Requested";
BA_ "SignalType" SG_ 1172 FCASensCstChgSetReq "ENM";
BA_ "SignalLongName" SG_ 1172 FCASensCstChgSetReq "Forward Collision Alert Sensitivity Customization Change Setting Request";
BA_ "SignalLongName" SG_ 1172 SD88_PV "Serial Data 88 : Protected Value";
BA_ "SignalLongName" SG_ 1172 SD88_ARC "Serial Data 88 : Alive Rolling Count";
BA_ "SignalType" SG_ 1172 PwrtrnExhPrtclFiltManRegnReq "ENM";
BA_ "SignalLongName" SG_ 1172 PwrtrnExhPrtclFiltManRegnReq "Serial Data 88 : Powertrain Exhaust Particle Filter Manual Regeneration Request";
BA_ "SignalType" SG_ 1172 LnDtnWrnSpprssnVirtCtlReq "ENM";
BA_ "SignalLongName" SG_ 1172 LnDtnWrnSpprssnVirtCtlReq "Lane Detection Warning Suppression Virtual Control Request";
BA_ "SignalType" SG_ 1172 BlndZnStrgAsstVirtCtlReq "ENM";
BA_ "SignalLongName" SG_ 1172 BlndZnStrgAsstVirtCtlReq "Blind Zone Steering Assist Virtual Control Request";
BA_ "SignalType" SG_ 1172 NtVsnDispThmActv "ENM";
BA_ "SignalLongName" SG_ 1172 NtVsnDispThmActv "Night Vision Display Theme Active";
BA_ "SignalType" SG_ 1172 VidAggrgtrSrlzrRestrtReq "ENM";
BA_ "SignalLongName" SG_ 1172 VidAggrgtrSrlzrRestrtReq "Video Aggregator Serializer Restart Request";
BA_ "SignalType" SG_ 1894 PTExPrtclFltrMnlRgnDispPrsnt "ENM";
BA_ "SignalLongName" SG_ 1894 PTExPrtclFltrMnlRgnDispPrsnt "Powertrain Exhaust Particle Filter Manual Regeneration Display Present";
BA_ "SignalLongName" SG_ 710 HVPPP_HstVehSdslAngAuth "Host Vehicle Path Parameters Protected : Host Vehicle Sideslip Angle Authenticated";
BA_ "SignalLongName" SG_ 731 PGI4P_ActlAxlTrqSecAuth "Propulsion General Information 4 Protected : Actual Axle Torque Secondary Authenticated";
BA_ "SignalType" SG_ 731 PGI4P_ActlAxlTrqSecAuth_Inv "ENM";
BA_ "SignalLongName" SG_ 731 PGI4P_ActlAxlTrqSecAuth_Inv "Propulsion General Information 4 Protected : Actual Axle Torque Secondary Authenticated Invalid";
BA_ "SignalType" SG_ 1896 IndHtgACSet "ENM";
BA_ "SignalLongName" SG_ 1896 IndHtgACSet "Indication Heating and Air Conditioning Setting";
BA_ "SignalType" SG_ 1896 SuprRmtPrkAval "ENM";
BA_ "SignalLongName" SG_ 1896 SuprRmtPrkAval "Supervised Remote Parking Available";
BA_ "SignalLongName" SG_ 1169 DMSDrwDrvrDispTmSnLstBrk "Driver Monitoring System Drowsy Driver Display Time Since Last Break";
BA_ "SignalType" SG_ 1169 Bat12VSysUnstabIndOn "ENM";
BA_ "SignalLongName" SG_ 1169 Bat12VSysUnstabIndOn "Battery 12V System Unstable Indication On";
BA_ "SignalType" SG_ 1169 DMSDrwIntnDrvrWrnIndReq "ENM";
BA_ "SignalLongName" SG_ 1169 DMSDrwIntnDrvrWrnIndReq "Driver Monitoring System Drowsy And Inattentive Driver Warning Indication Request";
BA_ "SignalType" SG_ 1169 PPMShwVehOnExtModeSwReqd "ENM";
BA_ "SignalLongName" SG_ 1169 PPMShwVehOnExtModeSwReqd "Passive Power Mode Extend Switch Visual Indications : Passive Power Mode Show Vehicle On Extend Mode Switch Requested";
BA_ "SignalType" SG_ 1169 DMSTnDrvrDrwIntnOffUnvIndOn "ENM";
BA_ "SignalLongName" SG_ 1169 DMSTnDrvrDrwIntnOffUnvIndOn "Driver Monitoring System Teen Driver Drowsy And Inattentive Off Unavailable Indication On";
BA_ "SignalType" SG_ 1169 DMSDrwDrvrDispLvl "ENM";
BA_ "SignalLongName" SG_ 1169 DMSDrwDrvrDispLvl "Driver Monitoring System Drowsy Driver Display Level";
BA_ "SignalType" SG_ 1169 DMSDrwDrvrCstCurrSetVal "ENM";
BA_ "SignalLongName" SG_ 1169 DMSDrwDrvrCstCurrSetVal "Driver Monitoring System Drowsy Driver Customization Current Setting Value";
BA_ "SignalType" SG_ 1169 PPMShwVehEmrgOffSwReqd "ENM";
BA_ "SignalLongName" SG_ 1169 PPMShwVehEmrgOffSwReqd "Passive Power Mode Show Vehicle Emergency Off Switch Requested";
BA_ "SignalType" SG_ 1169 PPMVehOffPrssBtnAgnSmrtPrmtReqd "ENM";
BA_ "SignalLongName" SG_ 1169 PPMVehOffPrssBtnAgnSmrtPrmtReqd "Passive Power Mode Vehicle Off Press Button Again Smart Prompt Requested";
BA_ "SignalType" SG_ 1169 DMSIntnDrvrCstCurrSetVal "ENM";
BA_ "SignalLongName" SG_ 1169 DMSIntnDrvrCstCurrSetVal "Driver Monitoring System Inattentive Driver Customization Current Setting Value";
BA_ "SignalType" SG_ 1169 DMSDrwDrvrIndReq "ENM";
BA_ "SignalLongName" SG_ 1169 DMSDrwDrvrIndReq "Driver Monitoring System Drowsy Driver Indication Request";
BA_ "SignalType" SG_ 1169 DMSIntnDrvrDispFcsInd "ENM";
BA_ "SignalLongName" SG_ 1169 DMSIntnDrvrDispFcsInd "Driver Monitoring System Inattentive Driver Display Focus Indication";
BA_ "SignalType" SG_ 1169 DMSIntnDrvrIndReq "ENM";
BA_ "SignalLongName" SG_ 1169 DMSIntnDrvrIndReq "Driver Monitoring System Inattentive Driver Indication Request";
BA_ "SignalType" SG_ 1169 DMSIntnDrvrDispLvl "ENM";
BA_ "SignalLongName" SG_ 1169 DMSIntnDrvrDispLvl "Driver Monitoring System Inattentive Driver Display Level";
BA_ "SignalLongName" SG_ 1169 PPMVehOnExtTmVal "Passive Power Mode Extend Switch Visual Indications : Passive Power Mode Vehicle On Extend Time Value";
BA_ "SignalLongName" SG_ 711 GNSSVel01EstVel "Global Navigation Satellite System Velocity 01 : Global Navigation Satellite System Velocity 01 East Velocity";
BA_ "SignalLongName" SG_ 711 GNSSVel01EstVelUncrtnty "Global Navigation Satellite System Velocity 01 : Global Navigation Satellite System Velocity 01 East Velocity Uncertainty";
BA_ "SignalType" SG_ 711 GNSSVel01EstVelUncrtnty_DuD "ENM";
BA_ "SignalLongName" SG_ 711 GNSSVel01EstVelUncrtnty_DuD "Global Navigation Satellite System Velocity 01 : Global Navigation Satellite System Velocity 01 East Velocity Uncertainty Don't Use Data";
BA_ "SignalLongName" SG_ 711 GNSSVel01NrthVel "Global Navigation Satellite System Velocity 01 : Global Navigation Satellite System Velocity 01 North Velocity";
BA_ "SignalType" SG_ 711 GNSSVel01EstVel_Inv "ENM";
BA_ "SignalLongName" SG_ 711 GNSSVel01EstVel_Inv "Global Navigation Satellite System Velocity 01 : Global Navigation Satellite System Velocity 01 East Velocity Invalid";
BA_ "SignalType" SG_ 711 GNSSVel01EstVel_DuD "ENM";
BA_ "SignalLongName" SG_ 711 GNSSVel01EstVel_DuD "Global Navigation Satellite System Velocity 01 : Global Navigation Satellite System Velocity 01 East Velocity Don't Use Data";
BA_ "SignalType" SG_ 711 GNSSVel01EstVelUncrtnty_Inv "ENM";
BA_ "SignalLongName" SG_ 711 GNSSVel01EstVelUncrtnty_Inv "Global Navigation Satellite System Velocity 01 : Global Navigation Satellite System Velocity 01 East Velocity Uncertainty Invalid";
BA_ "SignalLongName" SG_ 711 GNSSVel01NrthVelUncrtnty "Global Navigation Satellite System Velocity 01 : Global Navigation Satellite System Velocity 01 North Velocity Uncertainty";
BA_ "SignalType" SG_ 711 GNSSVel01NrthVel_Inv "ENM";
BA_ "SignalLongName" SG_ 711 GNSSVel01NrthVel_Inv "Global Navigation Satellite System Velocity 01 : Global Navigation Satellite System Velocity 01 North Velocity Invalid";
BA_ "SignalType" SG_ 711 GNSSVel01NrthVel_DuD "ENM";
BA_ "SignalLongName" SG_ 711 GNSSVel01NrthVel_DuD "Global Navigation Satellite System Velocity 01 : Global Navigation Satellite System Velocity 01 North Velocity Don't Use Data";
BA_ "SignalType" SG_ 711 GNSSVel01NrthVelUncrtnty_Inv "ENM";
BA_ "SignalLongName" SG_ 711 GNSSVel01NrthVelUncrtnty_Inv "Global Navigation Satellite System Velocity 01 : Global Navigation Satellite System Velocity 01 North Velocity Uncertainty Invalid";
BA_ "SignalType" SG_ 711 GNSSVel01NrthVelUncrtnty_DuD "ENM";
BA_ "SignalLongName" SG_ 711 GNSSVel01NrthVelUncrtnty_DuD "Global Navigation Satellite System Velocity 01 : Global Navigation Satellite System Velocity 01 North Velocity Uncertainty Don't Use Data";
BA_ "SignalLongName" SG_ 712 GNSSVel02UpVel "Global Navigation Satellite System Velocity 02 : Global Navigation Satellite System Velocity 02 Up Velocity";
BA_ "SignalLongName" SG_ 712 GNSSVel02UpVelUncrtnty "Global Navigation Satellite System Velocity 02 : Global Navigation Satellite System Velocity 02 Up Velocity Uncertainty";
BA_ "SignalType" SG_ 712 GNSSVel02UpVelUncrtnty_Inv "ENM";
BA_ "SignalLongName" SG_ 712 GNSSVel02UpVelUncrtnty_Inv "Global Navigation Satellite System Velocity 02 : Global Navigation Satellite System Velocity 02 Up Velocity Uncertainty Invalid";
BA_ "SignalType" SG_ 712 GNSSVel02UpVelUncrtnty_DuD "ENM";
BA_ "SignalLongName" SG_ 712 GNSSVel02UpVelUncrtnty_DuD "Global Navigation Satellite System Velocity 02 : Global Navigation Satellite System Velocity 02 Up Velocity Uncertainty Don't Use Data";
BA_ "SignalType" SG_ 712 GNSSVel02UpVel_Inv "ENM";
BA_ "SignalLongName" SG_ 712 GNSSVel02UpVel_Inv "Global Navigation Satellite System Velocity 02 : Global Navigation Satellite System Velocity 02 Up Velocity Invalid";
BA_ "SignalType" SG_ 712 GNSSVel02UpVel_DuD "ENM";
BA_ "SignalLongName" SG_ 712 GNSSVel02UpVel_DuD "Global Navigation Satellite System Velocity 02 : Global Navigation Satellite System Velocity 02 Up Velocity Don't Use Data";
BA_ "SignalType" SG_ 1897 APALtSftBtnStsIPC "ENM";
BA_ "SignalLongName" SG_ 1897 APALtSftBtnStsIPC "Advanced Park Assist Soft Button Status : Advanced Park Assist Left Soft Button Status IPC";
BA_ "SignalType" SG_ 1897 APALtSftBtnSts "ENM";
BA_ "SignalLongName" SG_ 1897 APALtSftBtnSts "Advanced Park Assist Soft Button Status : Advanced Park Assist Left Soft Button Status";
BA_ "SignalType" SG_ 1897 APAExtPrkSftBtnSts "ENM";
BA_ "SignalLongName" SG_ 1897 APAExtPrkSftBtnSts "Advanced Park Assist Soft Button Status : Advanced Park Assist Exit Park Soft Button Status";
BA_ "SignalType" SG_ 1897 APACrssFrntInSftBtnStat "ENM";
BA_ "SignalLongName" SG_ 1897 APACrssFrntInSftBtnStat "Advanced Park Assist Soft Button Status : Advanced Park Assist Cross Front-In Soft Button Status";
BA_ "SignalType" SG_ 1897 APACrsBkInSftBtnSts "ENM";
BA_ "SignalLongName" SG_ 1897 APACrsBkInSftBtnSts "Advanced Park Assist Soft Button Status : Advanced Park Assist Cross Back-In Soft Button Status";
BA_ "SignalType" SG_ 1897 APABkBtnSts "ENM";
BA_ "SignalLongName" SG_ 1897 APABkBtnSts "Advanced Park Assist Back Button Status";
BA_ "SignalType" SG_ 1897 APASuprPrkSts "ENM";
BA_ "SignalLongName" SG_ 1897 APASuprPrkSts "Advanced Park Assist Supervised Parking Status";
BA_ "SignalLongName" SG_ 1897 Mtx2SnkLvl "Phone Zone Audio : Mutex 2 Sink Level";
BA_ "SignalType" SG_ 1897 APASrchingSftBtnSts "ENM";
BA_ "SignalLongName" SG_ 1897 APASrchingSftBtnSts "Advanced Park Assist Soft Button Status : Advanced Park Assist Searching Soft Button Status";
BA_ "SignalType" SG_ 1897 APARtSftBtnStsIPC "ENM";
BA_ "SignalLongName" SG_ 1897 APARtSftBtnStsIPC "Advanced Park Assist Soft Button Status : Advanced Park Assist Right Soft Button Status IPC";
BA_ "SignalType" SG_ 1897 APARtSftBtnSts "ENM";
BA_ "SignalLongName" SG_ 1897 APARtSftBtnSts "Advanced Park Assist Soft Button Status : Advanced Park Assist Right Soft Button Status";
BA_ "SignalType" SG_ 1897 APAParallelPrkSftBtnSts "ENM";
BA_ "SignalLongName" SG_ 1897 APAParallelPrkSftBtnSts "Advanced Park Assist Soft Button Status : Advanced Park Assist Parallel Parking Soft Button Status";
BA_ "SignalLongName" SG_ 1897 PhnZnCfg "Phone Zone Audio : Phone Zone Configuration";
BA_ "SignalType" SG_ 1897 PhnZnEnbl "ENM";
BA_ "SignalLongName" SG_ 1897 PhnZnEnbl "Phone Zone Audio : Phone Zone Enable";
BA_ "SignalType" SG_ 1898 PTOEngRunTmrCstAvlFlg14 "ENM";
BA_ "SignalLongName" SG_ 1898 PTOEngRunTmrCstAvlFlg14 "Power Take Off Engine Run Timer Customization Availability Flag 14";
BA_ "SignalType" SG_ 1898 PTOEngRunTmrCstAvlFlg13 "ENM";
BA_ "SignalLongName" SG_ 1898 PTOEngRunTmrCstAvlFlg13 "Power Take Off Engine Run Timer Customization Availability Flag 13";
BA_ "SignalType" SG_ 1898 PTOEngRunTmrCstAvlFlg12 "ENM";
BA_ "SignalLongName" SG_ 1898 PTOEngRunTmrCstAvlFlg12 "Power Take Off Engine Run Timer Customization Availability Flag 12";
BA_ "SignalType" SG_ 1898 PTOEngRunTmrCstAvlFlg11 "ENM";
BA_ "SignalLongName" SG_ 1898 PTOEngRunTmrCstAvlFlg11 "Power Take Off Engine Run Timer Customization Availability Flag 11";
BA_ "SignalType" SG_ 1898 PTOEngRunTmrCstAvlFlg10 "ENM";
BA_ "SignalLongName" SG_ 1898 PTOEngRunTmrCstAvlFlg10 "Power Take Off Engine Run Timer Customization Availability Flag 10";
BA_ "SignalType" SG_ 1898 PTOEngRunTmrCstAvlFlg1 "ENM";
BA_ "SignalLongName" SG_ 1898 PTOEngRunTmrCstAvlFlg1 "Power Take Off Engine Run Timer Customization Availability Flag 1";
BA_ "SignalType" SG_ 1898 OffBrdVehImbNtfn "ENM";
BA_ "SignalLongName" SG_ 1898 OffBrdVehImbNtfn "Off Board Vehicle Immobilization Notification";
BA_ "SignalType" SG_ 1898 PTOEngRunTmrCstAvlFlg8 "ENM";
BA_ "SignalLongName" SG_ 1898 PTOEngRunTmrCstAvlFlg8 "Power Take Off Engine Run Timer Customization Availability Flag 8";
BA_ "SignalType" SG_ 1898 PTOEngRunTmrCstAvlFlg7 "ENM";
BA_ "SignalLongName" SG_ 1898 PTOEngRunTmrCstAvlFlg7 "Power Take Off Engine Run Timer Customization Availability Flag 7";
BA_ "SignalType" SG_ 1898 PTOEngRunTmrCstAvlFlg6 "ENM";
BA_ "SignalLongName" SG_ 1898 PTOEngRunTmrCstAvlFlg6 "Power Take Off Engine Run Timer Customization Availability Flag 6";
BA_ "SignalType" SG_ 1898 PTOEngRunTmrCstAvlFlg5 "ENM";
BA_ "SignalLongName" SG_ 1898 PTOEngRunTmrCstAvlFlg5 "Power Take Off Engine Run Timer Customization Availability Flag 5";
BA_ "SignalType" SG_ 1898 PTOEngRunTmrCstAvlFlg4 "ENM";
BA_ "SignalLongName" SG_ 1898 PTOEngRunTmrCstAvlFlg4 "Power Take Off Engine Run Timer Customization Availability Flag 4";
BA_ "SignalType" SG_ 1898 PTOEngRunTmrCstAvlFlg3 "ENM";
BA_ "SignalLongName" SG_ 1898 PTOEngRunTmrCstAvlFlg3 "Power Take Off Engine Run Timer Customization Availability Flag 3";
BA_ "SignalType" SG_ 1898 PTOEngRunTmrCstAvlFlg2 "ENM";
BA_ "SignalLongName" SG_ 1898 PTOEngRunTmrCstAvlFlg2 "Power Take Off Engine Run Timer Customization Availability Flag 2";
BA_ "SignalType" SG_ 1898 PTOEngRunTmrCstAvlFlg15 "ENM";
BA_ "SignalLongName" SG_ 1898 PTOEngRunTmrCstAvlFlg15 "Power Take Off Engine Run Timer Customization Availability Flag 15";
BA_ "SignalType" SG_ 1898 PTOSet1SpdCstAvlFlg11 "ENM";
BA_ "SignalLongName" SG_ 1898 PTOSet1SpdCstAvlFlg11 "Power Take Off Set 1 Speed Customization Availability Flag 11";
BA_ "SignalType" SG_ 1898 PTOSet1SpdCstAvlFlg10 "ENM";
BA_ "SignalLongName" SG_ 1898 PTOSet1SpdCstAvlFlg10 "Power Take Off Set 1 Speed Customization Availability Flag 10";
BA_ "SignalType" SG_ 1898 PTOSet1SpdCstAvlFlg1 "ENM";
BA_ "SignalLongName" SG_ 1898 PTOSet1SpdCstAvlFlg1 "Power Take Off Set 1 Speed Customization Availability Flag 1";
BA_ "SignalType" SG_ 1898 PTOModeCstAvlFlg2 "ENM";
BA_ "SignalLongName" SG_ 1898 PTOModeCstAvlFlg2 "Power Take Off Mode Customization Availability Flag 2";
BA_ "SignalType" SG_ 1898 PTOModeCstAvlFlg1 "ENM";
BA_ "SignalLongName" SG_ 1898 PTOModeCstAvlFlg1 "Power Take Off Mode Customization Availability Flag 1";
BA_ "SignalType" SG_ 1898 PTOEngSpdTypCstAvlFlg2 "ENM";
BA_ "SignalLongName" SG_ 1898 PTOEngSpdTypCstAvlFlg2 "Power Take Off Engine Speed Type Customization Availability Flag 2";
BA_ "SignalType" SG_ 1898 PTOEngSpdTypCstAvlFlg1 "ENM";
BA_ "SignalLongName" SG_ 1898 PTOEngSpdTypCstAvlFlg1 "Power Take Off Engine Speed Type Customization Availability Flag 1";
BA_ "SignalType" SG_ 1898 PTOEngRunTmrCstAvlFlg9 "ENM";
BA_ "SignalLongName" SG_ 1898 PTOEngRunTmrCstAvlFlg9 "Power Take Off Engine Run Timer Customization Availability Flag 9";
BA_ "SignalType" SG_ 1898 PTOSet1SpdCstAvlFlg5 "ENM";
BA_ "SignalLongName" SG_ 1898 PTOSet1SpdCstAvlFlg5 "Power Take Off Set 1 Speed Customization Availability Flag 5";
BA_ "SignalType" SG_ 1898 PTOSet1SpdCstAvlFlg4 "ENM";
BA_ "SignalLongName" SG_ 1898 PTOSet1SpdCstAvlFlg4 "Power Take Off Set 1 Speed Customization Availability Flag 4";
BA_ "SignalType" SG_ 1898 PTOSet1SpdCstAvlFlg3 "ENM";
BA_ "SignalLongName" SG_ 1898 PTOSet1SpdCstAvlFlg3 "Power Take Off Set 1 Speed Customization Availability Flag 3";
BA_ "SignalType" SG_ 1898 PTOSet1SpdCstAvlFlg2 "ENM";
BA_ "SignalLongName" SG_ 1898 PTOSet1SpdCstAvlFlg2 "Power Take Off Set 1 Speed Customization Availability Flag 2";
BA_ "SignalType" SG_ 1898 PTOSet1SpdCstAvlFlg15 "ENM";
BA_ "SignalLongName" SG_ 1898 PTOSet1SpdCstAvlFlg15 "Power Take Off Set 1 Speed Customization Availability Flag 15";
BA_ "SignalType" SG_ 1898 PTOSet1SpdCstAvlFlg14 "ENM";
BA_ "SignalLongName" SG_ 1898 PTOSet1SpdCstAvlFlg14 "Power Take Off Set 1 Speed Customization Availability Flag 14";
BA_ "SignalType" SG_ 1898 PTOSet1SpdCstAvlFlg13 "ENM";
BA_ "SignalLongName" SG_ 1898 PTOSet1SpdCstAvlFlg13 "Power Take Off Set 1 Speed Customization Availability Flag 13";
BA_ "SignalType" SG_ 1898 PTOSet1SpdCstAvlFlg12 "ENM";
BA_ "SignalLongName" SG_ 1898 PTOSet1SpdCstAvlFlg12 "Power Take Off Set 1 Speed Customization Availability Flag 12";
BA_ "SignalType" SG_ 1898 PTOSet2SpdCstAvlFlg12 "ENM";
BA_ "SignalLongName" SG_ 1898 PTOSet2SpdCstAvlFlg12 "Power Take Off Set 2 Speed Customization Availability Flag 12";
BA_ "SignalType" SG_ 1898 PTOSet2SpdCstAvlFlg11 "ENM";
BA_ "SignalLongName" SG_ 1898 PTOSet2SpdCstAvlFlg11 "Power Take Off Set 2 Speed Customization Availability Flag 11";
BA_ "SignalType" SG_ 1898 PTOSet2SpdCstAvlFlg10 "ENM";
BA_ "SignalLongName" SG_ 1898 PTOSet2SpdCstAvlFlg10 "Power Take Off Set 2 Speed Customization Availability Flag 10";
BA_ "SignalType" SG_ 1898 PTOSet2SpdCstAvlFlg1 "ENM";
BA_ "SignalLongName" SG_ 1898 PTOSet2SpdCstAvlFlg1 "Power Take Off Set 2 Speed Customization Availability Flag 1";
BA_ "SignalType" SG_ 1898 PTOSet1SpdCstAvlFlg9 "ENM";
BA_ "SignalLongName" SG_ 1898 PTOSet1SpdCstAvlFlg9 "Power Take Off Set 1 Speed Customization Availability Flag 9";
BA_ "SignalType" SG_ 1898 PTOSet1SpdCstAvlFlg8 "ENM";
BA_ "SignalLongName" SG_ 1898 PTOSet1SpdCstAvlFlg8 "Power Take Off Set 1 Speed Customization Availability Flag 8";
BA_ "SignalType" SG_ 1898 PTOSet1SpdCstAvlFlg7 "ENM";
BA_ "SignalLongName" SG_ 1898 PTOSet1SpdCstAvlFlg7 "Power Take Off Set 1 Speed Customization Availability Flag 7";
BA_ "SignalType" SG_ 1898 PTOSet1SpdCstAvlFlg6 "ENM";
BA_ "SignalLongName" SG_ 1898 PTOSet1SpdCstAvlFlg6 "Power Take Off Set 1 Speed Customization Availability Flag 6";
BA_ "SignalType" SG_ 1898 PTOSet2SpdCstAvlFlg6 "ENM";
BA_ "SignalLongName" SG_ 1898 PTOSet2SpdCstAvlFlg6 "Power Take Off Set 2 Speed Customization Availability Flag 6";
BA_ "SignalType" SG_ 1898 PTOSet2SpdCstAvlFlg5 "ENM";
BA_ "SignalLongName" SG_ 1898 PTOSet2SpdCstAvlFlg5 "Power Take Off Set 2 Speed Customization Availability Flag 5";
BA_ "SignalType" SG_ 1898 PTOSet2SpdCstAvlFlg4 "ENM";
BA_ "SignalLongName" SG_ 1898 PTOSet2SpdCstAvlFlg4 "Power Take Off Set 2 Speed Customization Availability Flag 4";
BA_ "SignalType" SG_ 1898 PTOSet2SpdCstAvlFlg3 "ENM";
BA_ "SignalLongName" SG_ 1898 PTOSet2SpdCstAvlFlg3 "Power Take Off Set 2 Speed Customization Availability Flag 3";
BA_ "SignalType" SG_ 1898 PTOSet2SpdCstAvlFlg2 "ENM";
BA_ "SignalLongName" SG_ 1898 PTOSet2SpdCstAvlFlg2 "Power Take Off Set 2 Speed Customization Availability Flag 2";
BA_ "SignalType" SG_ 1898 PTOSet2SpdCstAvlFlg15 "ENM";
BA_ "SignalLongName" SG_ 1898 PTOSet2SpdCstAvlFlg15 "Power Take Off Set 2 Speed Customization Availability Flag 15";
BA_ "SignalType" SG_ 1898 PTOSet2SpdCstAvlFlg14 "ENM";
BA_ "SignalLongName" SG_ 1898 PTOSet2SpdCstAvlFlg14 "Power Take Off Set 2 Speed Customization Availability Flag 14";
BA_ "SignalType" SG_ 1898 PTOSet2SpdCstAvlFlg13 "ENM";
BA_ "SignalLongName" SG_ 1898 PTOSet2SpdCstAvlFlg13 "Power Take Off Set 2 Speed Customization Availability Flag 13";
BA_ "SignalType" SG_ 1898 PTOStndbySpdCstAvlFlg5 "ENM";
BA_ "SignalLongName" SG_ 1898 PTOStndbySpdCstAvlFlg5 "Power Take Off Standby Speed Customization Availability Flag 5";
BA_ "SignalType" SG_ 1898 PTOStndbySpdCstAvlFlg4 "ENM";
BA_ "SignalLongName" SG_ 1898 PTOStndbySpdCstAvlFlg4 "Power Take Off Standby Speed Customization Availability Flag 4";
BA_ "SignalType" SG_ 1898 PTOStndbySpdCstAvlFlg3 "ENM";
BA_ "SignalLongName" SG_ 1898 PTOStndbySpdCstAvlFlg3 "Power Take Off Standby Speed Customization Availability Flag 3";
BA_ "SignalType" SG_ 1898 PTOStndbySpdCstAvlFlg2 "ENM";
BA_ "SignalLongName" SG_ 1898 PTOStndbySpdCstAvlFlg2 "Power Take Off Standby Speed Customization Availability Flag 2";
BA_ "SignalType" SG_ 1898 PTOStndbySpdCstAvlFlg1 "ENM";
BA_ "SignalLongName" SG_ 1898 PTOStndbySpdCstAvlFlg1 "Power Take Off Standby Speed Customization Availability Flag 1";
BA_ "SignalType" SG_ 1898 PTOSet2SpdCstAvlFlg9 "ENM";
BA_ "SignalLongName" SG_ 1898 PTOSet2SpdCstAvlFlg9 "Power Take Off Set 2 Speed Customization Availability Flag 9";
BA_ "SignalType" SG_ 1898 PTOSet2SpdCstAvlFlg8 "ENM";
BA_ "SignalLongName" SG_ 1898 PTOSet2SpdCstAvlFlg8 "Power Take Off Set 2 Speed Customization Availability Flag 8";
BA_ "SignalType" SG_ 1898 PTOSet2SpdCstAvlFlg7 "ENM";
BA_ "SignalLongName" SG_ 1898 PTOSet2SpdCstAvlFlg7 "Power Take Off Set 2 Speed Customization Availability Flag 7";
BA_ "SignalType" SG_ 1898 PTOTpStpSpdCstAvlFlg6 "ENM";
BA_ "SignalLongName" SG_ 1898 PTOTpStpSpdCstAvlFlg6 "Power Take Off Tap Step Speed Customization Availability Flag 6";
BA_ "SignalType" SG_ 1898 PTOTpStpSpdCstAvlFlg5 "ENM";
BA_ "SignalLongName" SG_ 1898 PTOTpStpSpdCstAvlFlg5 "Power Take Off Tap Step Speed Customization Availability Flag 5";
BA_ "SignalType" SG_ 1898 PTOTpStpSpdCstAvlFlg4 "ENM";
BA_ "SignalLongName" SG_ 1898 PTOTpStpSpdCstAvlFlg4 "Power Take Off Tap Step Speed Customization Availability Flag 4";
BA_ "SignalType" SG_ 1898 PTOTpStpSpdCstAvlFlg3 "ENM";
BA_ "SignalLongName" SG_ 1898 PTOTpStpSpdCstAvlFlg3 "Power Take Off Tap Step Speed Customization Availability Flag 3";
BA_ "SignalType" SG_ 1898 PTOTpStpSpdCstAvlFlg2 "ENM";
BA_ "SignalLongName" SG_ 1898 PTOTpStpSpdCstAvlFlg2 "Power Take Off Tap Step Speed Customization Availability Flag 2";
BA_ "SignalType" SG_ 1898 PTOTpStpSpdCstAvlFlg1 "ENM";
BA_ "SignalLongName" SG_ 1898 PTOTpStpSpdCstAvlFlg1 "Power Take Off Tap Step Speed Customization Availability Flag 1";
BA_ "SignalType" SG_ 1898 PTOStndbySpdCstAvlFlg7 "ENM";
BA_ "SignalLongName" SG_ 1898 PTOStndbySpdCstAvlFlg7 "Power Take Off Standby Speed Customization Availability Flag 7";
BA_ "SignalType" SG_ 1898 PTOStndbySpdCstAvlFlg6 "ENM";
BA_ "SignalLongName" SG_ 1898 PTOStndbySpdCstAvlFlg6 "Power Take Off Standby Speed Customization Availability Flag 6";
BA_ "SignalType" SG_ 1167 PTOTpStpSpdCstAvlFlg7 "ENM";
BA_ "SignalLongName" SG_ 1167 PTOTpStpSpdCstAvlFlg7 "Power Take Off Tap Step Speed Customization Availability Flag 7";
BA_ "SignalType" SG_ 1167 VehColdBatPerfIndOn "ENM";
BA_ "SignalLongName" SG_ 1167 VehColdBatPerfIndOn "Vehicle Cold Battery Performance Indication On";
BA_ "SignalType" SG_ 1167 ActvRrSplrVirtUserCtlAllwd "ENM";
BA_ "SignalLongName" SG_ 1167 ActvRrSplrVirtUserCtlAllwd "Active Rear Spoiler Virtual User Control Allowed";
BA_ "SignalType" SG_ 1167 ActvRrSplrVirtCtlAval "ENM";
BA_ "SignalLongName" SG_ 1167 ActvRrSplrVirtCtlAval "Active Rear Spoiler Virtual Control Available";
BA_ "SignalType" SG_ 1167 ActvRrSplrVirtCtlCurrSeltnVal "ENM";
BA_ "SignalLongName" SG_ 1167 ActvRrSplrVirtCtlCurrSeltnVal "Active Rear Spoiler Virtual Control Current Selection Value";
BA_ "SignalLongName" SG_ 1899 TrlrFllHtchPtLgth "Trailer Full Hitching Point Length";
BA_ "SignalLongName" SG_ 1899 TrlrToCabLgth "Trailer to Cab Length";
BA_ "SignalLongName" SG_ 1899 TrlrBoxWdth "Trailer Box Width";
BA_ "SignalLongName" SG_ 1899 TrlrFaceDpth "Trailer Face Depth";
BA_ "SignalLongName" SG_ 1899 TrlrFrtBtmCrnrHght "Trailer Front Bottom Corner Height";
BA_ "SignalLongName" SG_ 1899 TrlrFrwdSdEdgeHght "Trailer Forward Side Edge Height";
BA_ "SignalType" SG_ 1899 TrlrJckKnfAlrtSts "ENM";
BA_ "SignalLongName" SG_ 1899 TrlrJckKnfAlrtSts "Trailer Jack Knife Alert Status";
BA_ "SignalLongName" SG_ 1166 VehBedHtchToCabLgth "Vehicle Bed Hitch to Cab Length";
BA_ "SignalType" SG_ 1900 VirtCtlHtdVntStSwRrAval "ENM";
BA_ "SignalLongName" SG_ 1900 VirtCtlHtdVntStSwRrAval "Virtual Control Heated Vented Seat Switch Rear Available";
BA_ "SignalType" SG_ 1900 VirtCtlHtdVntStSwFrtAval "ENM";
BA_ "SignalLongName" SG_ 1900 VirtCtlHtdVntStSwFrtAval "Virtual Control Heated Vented Seat Switch Front Available";
BA_ "SignalType" SG_ 1165 InfoOffRdAppInfltDfltAsstEnbld "ENM";
BA_ "SignalLongName" SG_ 1165 InfoOffRdAppInfltDfltAsstEnbld "Infotainment Off Road App Inflate Deflate Assist Enabled";
BA_ "SignalType" SG_ 1165 UpftrSnwPlwIndReq "ENM";
BA_ "SignalLongName" SG_ 1165 UpftrSnwPlwIndReq "Upfitter Snow Plow Indication Request";
BA_ "SignalType" SG_ 1165 UpftrRrAprchPrtctnIndReq "ENM";
BA_ "SignalLongName" SG_ 1165 UpftrRrAprchPrtctnIndReq "Upfitter Rear Approach Protection Indication Request";
BA_ "SignalLongName" SG_ 1165 ChrgCycEleclEngyUsd "Charge Cycle Electrical Energy Used";
BA_ "SignalType" SG_ 1165 LifetmEleclEngyEcon_DuD "ENM";
BA_ "SignalLongName" SG_ 1165 LifetmEleclEngyEcon_DuD "Lifetime Electrical Energy Economy Don't Use Data";
BA_ "SignalType" SG_ 1165 ChrgCycEleclEngyUsd_DuD "ENM";
BA_ "SignalLongName" SG_ 1165 ChrgCycEleclEngyUsd_DuD "Charge Cycle Electrical Energy Used Don't Use Data";
BA_ "SignalType" SG_ 1165 UpftrRadioMutReqd "ENM";
BA_ "SignalLongName" SG_ 1165 UpftrRadioMutReqd "Upfitter Radio Mute Requested";
BA_ "SignalType" SG_ 1165 UpftrBkupCamActvnReqd "ENM";
BA_ "SignalLongName" SG_ 1165 UpftrBkupCamActvnReqd "Upfitter Backup Camera Activation Requested";
BA_ "SignalLongName" SG_ 1165 LifetmEleclEngyEcon "Lifetime Electrical Energy Economy";
BA_ "SignalType" SG_ 1165 AutoHiBmSmrtIconReqd "ENM";
BA_ "SignalLongName" SG_ 1165 AutoHiBmSmrtIconReqd "Auto High Beam Smart Icon Requested";
BA_ "SignalType" SG_ 1165 RIMUnvTlgtIndOn "ENM";
BA_ "SignalLongName" SG_ 1165 RIMUnvTlgtIndOn "Rearward Impact Mitigation Unavailable Tailgate Indication On";
BA_ "SignalType" SG_ 1165 PnCBkOfcDatTrgrd "ENM";
BA_ "SignalLongName" SG_ 1165 PnCBkOfcDatTrgrd "Plug And Charge Back Office Data Triggered";
BA_ "SignalType" SG_ 1165 TransOilFiltChgIndOn "ENM";
BA_ "SignalLongName" SG_ 1165 TransOilFiltChgIndOn "Transmission Oil Filter Change Indication On";
BA_ "SignalLongName" SG_ 1901 InfoOffRdAppInfltDfltAsstTgtPrs "Infotainment Off Road App Inflate Deflate Assist Target Pressure";
BA_ "SignalType" SG_ 1901 InfoOffRdAppInfltDfltAsstReqd "ENM";
BA_ "SignalLongName" SG_ 1901 InfoOffRdAppInfltDfltAsstReqd "Infotainment Off Road App Inflate Deflate Assist Requested";
BA_ "SignalType" SG_ 194 VwgVwprtStsExtd "ENM";
BA_ "SignalLongName" SG_ 194 VwgVwprtStsExtd "Viewing Viewport Status Extended";
BA_ "SignalType" SG_ 194 VwgVwprtReqExtd "ENM";
BA_ "SignalLongName" SG_ 194 VwgVwprtReqExtd "Viewing Viewport Request Extended";
BA_ "SignalType" SG_ 194 VwgCtlBtnAvlUndrbdyRrwdActv "ENM";
BA_ "SignalLongName" SG_ 194 VwgCtlBtnAvlUndrbdyRrwdActv "Viewing Control Button Availability Underbody Rearward Active";
BA_ "SignalType" SG_ 194 VwgCtlBtnAvlUndrbdyFrwdActv "ENM";
BA_ "SignalLongName" SG_ 194 VwgCtlBtnAvlUndrbdyFrwdActv "Viewing Control Button Availability Underbody Forward Active";
BA_ "SignalType" SG_ 192 VwgVwprtSeltnExtd "ENM";
BA_ "SignalLongName" SG_ 192 VwgVwprtSeltnExtd "Viewing Viewport Selection Extended";
BA_ "SignalType" SG_ 112 AtTrnsGrSftDrct "ENM";
BA_ "SignalLongName" SG_ 112 AtTrnsGrSftDrct "Automatic Transmission Gear Shift Direction";
BA_ "SignalType" SG_ 1164 PPMShwVehOffSwRedntReqd "ENM";
BA_ "SignalLongName" SG_ 1164 PPMShwVehOffSwRedntReqd "Passive Power Mode Show Vehicle Off Switch Redundant Requested";
BA_ "SignalType" SG_ 1164 CBIP_ClsnImntBrkgStsAuth "ENM";
BA_ "SignalLongName" SG_ 1164 CBIP_ClsnImntBrkgStsAuth "Serial Data 16 Protected : Collision Imminent Braking Status Authenticated";
BA_ "SignalType" SG_ 1164 HVBatSOCDspHdlmpCstCurrSetVal "ENM";
BA_ "SignalLongName" SG_ 1164 HVBatSOCDspHdlmpCstCurrSetVal "High Voltage Battery State of Charge Display Headlamp Customization Current Setting Value";
BA_ "SignalType" SG_ 1164 ElecShfPriLoManSeltnIndReq "ENM";
BA_ "SignalLongName" SG_ 1164 ElecShfPriLoManSeltnIndReq "Electronic Shift Primary Low/Manual Selection Indication Request";
BA_ "SignalType" SG_ 1164 VirtCtlPrvcySwAllwd "ENM";
BA_ "SignalLongName" SG_ 1164 VirtCtlPrvcySwAllwd "Virtual Control Privacy Switch Allowed";
BA_ "SignalType" SG_ 1164 VirtCtlBkGlsShdCtlRrAllwd "ENM";
BA_ "SignalLongName" SG_ 1164 VirtCtlBkGlsShdCtlRrAllwd "Virtual Control Back Glass Shade Control Rear Allowed";
BA_ "SignalType" SG_ 1164 VirtCtlBkGlsShdCtlFrtAllwd "ENM";
BA_ "SignalLongName" SG_ 1164 VirtCtlBkGlsShdCtlFrtAllwd "Virtual Control Back Glass Shade Control Front Allowed";
BA_ "SignalType" SG_ 1164 ActvRollCtlRrWrnIndReq "ENM";
BA_ "SignalLongName" SG_ 1164 ActvRollCtlRrWrnIndReq "Active Roll Control Information : Active Roll Control Rear Warning Indication Request";
BA_ "SignalType" SG_ 1164 ActvRollCtlFrtWrnIndReq "ENM";
BA_ "SignalLongName" SG_ 1164 ActvRollCtlFrtWrnIndReq "Active Roll Control Information : Active Roll Control Front Warning Indication Request";
BA_ "SignalType" SG_ 1164 PPMShwVehOffSwMnReqd "ENM";
BA_ "SignalLongName" SG_ 1164 PPMShwVehOffSwMnReqd "Passive Power Mode Show Vehicle Off Switch Main Requested";
BA_ "SignalType" SG_ 1164 ActvRrSplrWrnIndReq "ENM";
BA_ "SignalLongName" SG_ 1164 ActvRrSplrWrnIndReq "Active Rear Spoiler Warning Indication Request";
BA_ "SignalType" SG_ 1163 ICMCstSelCstSetAval "ENM";
BA_ "SignalLongName" SG_ 1163 ICMCstSelCstSetAval "Intersection Collision Mitigation Customization Select Customization Setting Available";
BA_ "SignalType" SG_ 1163 ICMCstAvlFlg7 "ENM";
BA_ "SignalLongName" SG_ 1163 ICMCstAvlFlg7 "Intersection Collision Mitigation Customization Availability Flag 7";
BA_ "SignalType" SG_ 1163 ICMCstAvlFlg6 "ENM";
BA_ "SignalLongName" SG_ 1163 ICMCstAvlFlg6 "Intersection Collision Mitigation Customization Availability Flag 6";
BA_ "SignalType" SG_ 1163 ICMCstAvlFlg5 "ENM";
BA_ "SignalLongName" SG_ 1163 ICMCstAvlFlg5 "Intersection Collision Mitigation Customization Availability Flag 5";
BA_ "SignalType" SG_ 1163 ICMCstAvlFlg4 "ENM";
BA_ "SignalLongName" SG_ 1163 ICMCstAvlFlg4 "Intersection Collision Mitigation Customization Availability Flag 4";
BA_ "SignalType" SG_ 1163 ICMCstAvlFlg3 "ENM";
BA_ "SignalLongName" SG_ 1163 ICMCstAvlFlg3 "Intersection Collision Mitigation Customization Availability Flag 3";
BA_ "SignalType" SG_ 1163 ICMCstAvlFlg2 "ENM";
BA_ "SignalLongName" SG_ 1163 ICMCstAvlFlg2 "Intersection Collision Mitigation Customization Availability Flag 2";
BA_ "SignalType" SG_ 1163 ICMCstAvlFlg1 "ENM";
BA_ "SignalLongName" SG_ 1163 ICMCstAvlFlg1 "Intersection Collision Mitigation Customization Availability Flag 1";
BA_ "SignalType" SG_ 1163 ICMCstSelCstCurSetVal "ENM";
BA_ "SignalLongName" SG_ 1163 ICMCstSelCstCurSetVal "Intersection Collision Mitigation Customization Select Customization Current Setting Value";
BA_ "SignalType" SG_ 1903 InfoThmSeltnCurrSetVal "ENM";
BA_ "SignalLongName" SG_ 1903 InfoThmSeltnCurrSetVal "Deprecated VIP 24 - Infotainment Theme Selection Current Setting Value";
BA_ "SignalType" SG_ 1903 ICMCstChgSetReq "ENM";
BA_ "SignalLongName" SG_ 1903 ICMCstChgSetReq "Intersection Collision Mitigation Customization Change Setting Request";
BA_ "SignalType" SG_ 1903 ActvRrSplrVirtCtlReq "ENM";
BA_ "SignalLongName" SG_ 1903 ActvRrSplrVirtCtlReq "Active Rear Spoiler Virtual Control Request";
BA_ "SignalLongName" SG_ 1161 VirtCkptDispTchPstnX1 "Virtual Cockpit Display Touch Position 12 : Virtual Cockpit Display Touch Position X1";
BA_ "SignalType" SG_ 1161 VirtCkptDispTchFlg2 "ENM";
BA_ "SignalLongName" SG_ 1161 VirtCkptDispTchFlg2 "Virtual Cockpit Display Touch Position 12 : Virtual Cockpit Display Touch Flag 2";
BA_ "SignalType" SG_ 1161 VirtCkptDispTchFlg1 "ENM";
BA_ "SignalLongName" SG_ 1161 VirtCkptDispTchFlg1 "Virtual Cockpit Display Touch Position 12 : Virtual Cockpit Display Touch Flag 1";
BA_ "SignalLongName" SG_ 1161 VirtCkptDispTchPstnX2 "Virtual Cockpit Display Touch Position 12 : Virtual Cockpit Display Touch Position X2";
BA_ "SignalLongName" SG_ 1161 VirtCkptDispTchPstnY1 "Virtual Cockpit Display Touch Position 12 : Virtual Cockpit Display Touch Position Y1";
BA_ "SignalLongName" SG_ 1161 VirtCkptDispTchPstnY2 "Virtual Cockpit Display Touch Position 12 : Virtual Cockpit Display Touch Position Y2";
BA_ "SignalLongName" SG_ 1161 VirtCkptDispTmStm12 "Virtual Cockpit Display Touch Position 12 : Virtual Cockpit Display Time Stamp 12";
BA_ "SignalType" SG_ 1161 SRPSptSeltnRmtSftBtnSts "ENM";
BA_ "SignalLongName" SG_ 1161 SRPSptSeltnRmtSftBtnSts "Serial Data 235 : Supervised Remote Parking Spot Selection Remote Soft Button Status";
BA_ "SignalType" SG_ 1161 SRPSptSeltnKeepLkSftBtnSts "ENM";
BA_ "SignalLongName" SG_ 1161 SRPSptSeltnKeepLkSftBtnSts "Serial Data 235 : Supervised Remote Parking Spot Selection Keep Looking Soft Button Status";
BA_ "SignalType" SG_ 1161 SRPSptSeltnAcceptSftBtnSts "ENM";
BA_ "SignalLongName" SG_ 1161 SRPSptSeltnAcceptSftBtnSts "Serial Data 235 : Supervised Remote Parking Spot Selection Accept Soft Button Status";
BA_ "SignalType" SG_ 1161 SuprRmtPrkDctvSoftBtnSts "ENM";
BA_ "SignalLongName" SG_ 1161 SuprRmtPrkDctvSoftBtnSts "Serial Data 235 : Supervised Remote Parking Deactivation Soft Button Status";
BA_ "SignalLongName" SG_ 1905 VirtCkptDispTchPstnX3 "Virtual Cockpit Display Touch Position 34 : Virtual Cockpit Display Touch Position X3";
BA_ "SignalType" SG_ 1905 VirtCkptDispTchFlg4 "ENM";
BA_ "SignalLongName" SG_ 1905 VirtCkptDispTchFlg4 "Virtual Cockpit Display Touch Position 34 : Virtual Cockpit Display Touch Flag 4";
BA_ "SignalType" SG_ 1905 VirtCkptDispTchFlg3 "ENM";
BA_ "SignalLongName" SG_ 1905 VirtCkptDispTchFlg3 "Virtual Cockpit Display Touch Position 34 : Virtual Cockpit Display Touch Flag 3";
BA_ "SignalLongName" SG_ 1905 VirtCkptDispTchPstnX4 "Virtual Cockpit Display Touch Position 34 : Virtual Cockpit Display Touch Position X4";
BA_ "SignalLongName" SG_ 1905 VirtCkptDispTchPstnY3 "Virtual Cockpit Display Touch Position 34 : Virtual Cockpit Display Touch Position Y3";
BA_ "SignalLongName" SG_ 1905 VirtCkptDispTchPstnY4 "Virtual Cockpit Display Touch Position 34 : Virtual Cockpit Display Touch Position Y4";
BA_ "SignalLongName" SG_ 1905 VirtCkptDispTmStm34 "Virtual Cockpit Display Touch Position 34 : Virtual Cockpit Display Time Stamp 34";
BA_ "SignalType" SG_ 1905 SRPUnableCnctExtSftBtnSts "ENM";
BA_ "SignalLongName" SG_ 1905 SRPUnableCnctExtSftBtnSts "Supervised Remote Parking Unable to Connect Status : Supervised Remote Parking Unable to Connect Exit Soft Button Status";
BA_ "SignalType" SG_ 1905 SRPUnableCnctTryAgnSftBtnSts "ENM";
BA_ "SignalLongName" SG_ 1905 SRPUnableCnctTryAgnSftBtnSts "Supervised Remote Parking Unable to Connect Status : Supervised Remote Parking Unable To Connect Try Again Soft Button Status";
BA_ "SignalLongName" SG_ 1162 PrplDispExtndCpbltyLvlPct "Propulsion Display Extended Capability Information : Propulsion Display Extended Capability Level Percent";
BA_ "SignalType" SG_ 1162 HiVltgSysFltIndOn "ENM";
BA_ "SignalLongName" SG_ 1162 HiVltgSysFltIndOn "High Voltage System Fault Indication On";
BA_ "SignalType" SG_ 1162 HiVltgChrgLtdRsn "ENM";
BA_ "SignalLongName" SG_ 1162 HiVltgChrgLtdRsn "High Voltage Charge Limited Reason";
BA_ "SignalLongName" SG_ 1162 PrplDispExtndPwrLvlPct "Propulsion Display Extended Power Information : Propulsion Display Extended Power Level Percent";
BA_ "SignalType" SG_ 1162 PrplDispExtndCpbltyLvlPct_DuD "ENM";
BA_ "SignalLongName" SG_ 1162 PrplDispExtndCpbltyLvlPct_DuD "Propulsion Display Extended Capability Information : Propulsion Display Extended Capability Level Percent Don't Use Data";
BA_ "SignalType" SG_ 1162 PrplDispExtndPwrLvlPct_DuD "ENM";
BA_ "SignalLongName" SG_ 1162 PrplDispExtndPwrLvlPct_DuD "Propulsion Display Extended Power Information : Propulsion Display Extended Power Level Percent Don't Use Data";
BA_ "SignalType" SG_ 1162 InfoWndMtnCtlRRAllwd "ENM";
BA_ "SignalLongName" SG_ 1162 InfoWndMtnCtlRRAllwd "Infotainment Window Motion Control Right Rear Allowed";
BA_ "SignalType" SG_ 1162 InfoWndMtnCtlRFAllwd "ENM";
BA_ "SignalLongName" SG_ 1162 InfoWndMtnCtlRFAllwd "Infotainment Window Motion Control Right Front Allowed";
BA_ "SignalType" SG_ 1162 InfoWndMtnCtlLRAllwd "ENM";
BA_ "SignalLongName" SG_ 1162 InfoWndMtnCtlLRAllwd "Infotainment Window Motion Control Left Rear Allowed";
BA_ "SignalType" SG_ 1162 InfoWndMtnCtlLFAllwd "ENM";
BA_ "SignalLongName" SG_ 1162 InfoWndMtnCtlLFAllwd "Infotainment Window Motion Control Left Front Allowed";
BA_ "SignalType" SG_ 1162 InfoSnrfMtnCtlAllwd "ENM";
BA_ "SignalLongName" SG_ 1162 InfoSnrfMtnCtlAllwd "Infotainment Sunroof Motion Control Allowed";
BA_ "SignalType" SG_ 1162 InfoFrtSnshdMtnCtlAllwd "ENM";
BA_ "SignalLongName" SG_ 1162 InfoFrtSnshdMtnCtlAllwd "Infotainment Front Sunshade Motion Control Allowed";
BA_ "SignalType" SG_ 1162 FrtSnshdPstnStsInfo "ENM";
BA_ "SignalLongName" SG_ 1162 FrtSnshdPstnStsInfo "DEPRECATED VIP 24 - Front Sunshade Position Status Information";
BA_ "SignalType" SG_ 1162 PwrlineCommCtlPilotDC_Inv "ENM";
BA_ "SignalLongName" SG_ 1162 PwrlineCommCtlPilotDC_Inv "High Voltage Charging Controller Status : Powerline Communication Control Pilot Duty Cycle Invalid";
BA_ "SignalLongName" SG_ 1162 PwrlineCommCtlPilotDC "High Voltage Charging Controller Status : Powerline Communication Control Pilot Duty Cycle";
BA_ "SignalType" SG_ 1162 HiVltgCouplerPrxmtySts_Inv "ENM";
BA_ "SignalLongName" SG_ 1162 HiVltgCouplerPrxmtySts_Inv "High Voltage Charging Controller Status : High Voltage Coupler Proximity Status Invalid";
BA_ "SignalType" SG_ 1162 HiVltgCouplerPrxmtySts "ENM";
BA_ "SignalLongName" SG_ 1162 HiVltgCouplerPrxmtySts "High Voltage Charging Controller Status : High Voltage Coupler Proximity Status";
BA_ "SignalLongName" SG_ 1160 NextChrgDestLat "Next Charging Destination Information 2 : Next Charging Destination Latitude";
BA_ "SignalLongName" SG_ 1160 NextChrgDestLng "Next Charging Destination Information 2 : Next Charging Destination Longitude";
BA_ "SignalType" SG_ 1160 DMSDrwDrvrCstChgSetReq "ENM";
BA_ "SignalLongName" SG_ 1160 DMSDrwDrvrCstChgSetReq "Driver Monitoring System Drowsy Driver Customization Change Setting Request";
BA_ "SignalLongName" SG_ 1906 NavRtePrdtdCustUsblSOC "Navigation Route Information 1 : Navigation Route Predicted Customer Usable State of Charge";
BA_ "SignalType" SG_ 1906 NavRteChgOcc "ENM";
BA_ "SignalLongName" SG_ 1906 NavRteChgOcc "Navigation Route Information 1 : Navigation Route Change Occurred";
BA_ "SignalLongName" SG_ 1906 NavRtePrdtdOAT "Navigation Route Information 1 : Navigation Route Predicted Outside Air Temperature";
BA_ "SignalLongName" SG_ 1906 NavRtePrdtdRdLdPwr "Navigation Route Information 1 : Navigation Route Predicted Road Load Power";
BA_ "SignalLongName" SG_ 1906 NavRtePrdtdVehSpd "Navigation Route Information 1 : Navigation Route Predicted Vehicle Speed";
BA_ "SignalLongName" SG_ 1906 NavRteTmIdx1 "Navigation Route Information 1 : Navigation Route Time Index 1";
BA_ "SignalType" SG_ 1906 NavRteSts "ENM";
BA_ "SignalLongName" SG_ 1906 NavRteSts "Navigation Route Information 1 : Navigation Route Status";
BA_ "SignalLongName" SG_ 1159 NavRtePrdtdEngyDelt "Navigation Route Information 3 : Navigation Route Predicted Energy Delta";
BA_ "SignalLongName" SG_ 1159 NavRtePrdtdLat "Navigation Route Information 3 : Navigation Route Predicted Latitude";
BA_ "SignalLongName" SG_ 1159 NavRteTmIdx3 "Navigation Route Information 3 : Navigation Route Time Index 3";
BA_ "SignalLongName" SG_ 1907 NavRtePrdtdElvtn "Navigation Route Information 2 : Navigation Route Predicted Elevation";
BA_ "SignalLongName" SG_ 1907 NavRtePrdtdLng "Navigation Route Information 2 : Navigation Route Predicted Longitude";
BA_ "SignalLongName" SG_ 1907 NavRteTmIdx2 "Navigation Route Information 2 : Navigation Route Time Index 2";
BA_ "SignalLongName" SG_ 1158 NextChrgDestDistToArvl "Next Charging Destination Information 1 : Next Charging Destination Distance To Arrival";
BA_ "SignalLongName" SG_ 1158 NextChrgDestPwrLvl "Next Charging Destination Information 1 : Next Charging Destination Power Level";
BA_ "SignalLongName" SG_ 1158 NextChrgDestTmToArvl "Next Charging Destination Information 1 : Next Charging Destination Time To Arrival";
BA_ "SignalType" SG_ 1158 NextChrgDestSts "ENM";
BA_ "SignalLongName" SG_ 1158 NextChrgDestSts "Next Charging Destination Information 1 : Next Charging Destination Status";
BA_ "SignalLongName" SG_ 1908 PnCActnStsCertfctNum "Plug And Charge Certificate Action Status : Plug And Charge Action Status Certificate Number";
BA_ "SignalType" SG_ 1908 PnCActnStsCertfctTyp "ENM";
BA_ "SignalLongName" SG_ 1908 PnCActnStsCertfctTyp "Plug And Charge Certificate Action Status : Plug And Charge Action Status Certificate Type";
BA_ "SignalType" SG_ 1908 PnCActnStsCertfctOpSts "ENM";
BA_ "SignalLongName" SG_ 1908 PnCActnStsCertfctOpSts "Plug And Charge Certificate Action Status : Plug And Charge Action Status Certificate Operation Status";
BA_ "SignalLongName" SG_ 1908 IBSRwBatSOCErr "Intelligent Battery Sensor 12V Battery Information : IBS Raw Battery SOC Error";
BA_ "SignalType" SG_ 1908 ElecVehAllWhlDrvUnvWrnIndReq "ENM";
BA_ "SignalLongName" SG_ 1908 ElecVehAllWhlDrvUnvWrnIndReq "Electric Vehicle All Wheel Drive Unavailable Indication Information : Electric Vehicle All Wheel Drive Unavailable Warning Indication Request";
BA_ "SignalType" SG_ 1908 ElecVehAllWhlDrvUnvIndReq "ENM";
BA_ "SignalLongName" SG_ 1908 ElecVehAllWhlDrvUnvIndReq "Electric Vehicle All Wheel Drive Unavailable Indication Information : Electric Vehicle All Wheel Drive Unavailable Indication Request";
BA_ "SignalLongName" SG_ 1908 TransOilFiltRmnLife "Transmission Oil Filter Remaining Life";
BA_ "SignalLongName" SG_ 1908 PrplDispMaxDischrgCpbltyPct "Propulsion Display\??Maximum\??Discharge Capability Percent";
BA_ "SignalType" SG_ 1157 FAXVCLoPrtyFltChmEvntStat "ENM";
BA_ "SignalLongName" SG_ 1157 FAXVCLoPrtyFltChmEvntStat "Full Authority External Vehicle Controller Low Priority Fault Chime Event State";
BA_ "SignalType" SG_ 1157 FAXVCInCtlChmEvntStat "ENM";
BA_ "SignalLongName" SG_ 1157 FAXVCInCtlChmEvntStat "Full Authority External Vehicle Controller in Control Chime Event State";
BA_ "SignalType" SG_ 1157 FAXVCHiPrtyFltChmEvntStat "ENM";
BA_ "SignalLongName" SG_ 1157 FAXVCHiPrtyFltChmEvntStat "Full Authority External Vehicle Controller High Priority Fault Chime Event State";
BA_ "SignalType" SG_ 1157 AutoCtlrGnrcChmEvntStat "ENM";
BA_ "SignalLongName" SG_ 1157 AutoCtlrGnrcChmEvntStat "Autonomous Controller Generic Chime Event State";
BA_ "SignalType" SG_ 1157 VehNDtctgFAXVCErrChmEvntStat "ENM";
BA_ "SignalLongName" SG_ 1157 VehNDtctgFAXVCErrChmEvntStat "Vehicle Not Detecting Full Authority External Vehicle Controller Error Chime Event State";
BA_ "SignalType" SG_ 1157 VehExtdFAXVCModeChmEvntStat "ENM";
BA_ "SignalLongName" SG_ 1157 VehExtdFAXVCModeChmEvntStat "Vehicle Exited Full Authority External Vehicle Controller Mode Chime Event State";
BA_ "SignalType" SG_ 1157 FAXVCSevPrtyFltChmEvntStat "ENM";
BA_ "SignalLongName" SG_ 1157 FAXVCSevPrtyFltChmEvntStat "Full Authority External Vehicle Controller Severe Priority Fault Chime Event State";
BA_ "SignalType" SG_ 1157 FAXVCMedPrtyFltChmEvntStat "ENM";
BA_ "SignalLongName" SG_ 1157 FAXVCMedPrtyFltChmEvntStat "Full Authority External Vehicle Controller Medium Priority Fault Chime Event State";
BA_ "SignalType" SG_ 1157 IndHtdArmrstLvlRrRt "ENM";
BA_ "SignalLongName" SG_ 1157 IndHtdArmrstLvlRrRt "Indication Heated Armrest Level Rear Right";
BA_ "SignalType" SG_ 1157 UpftrRrAprchPrtctnChmEvntStat "ENM";
BA_ "SignalLongName" SG_ 1157 UpftrRrAprchPrtctnChmEvntStat "Upfitter Rear Approach Protection Chime Event State";
BA_ "SignalType" SG_ 1157 DMSIntnDrvrCstAvlFlg1 "ENM";
BA_ "SignalLongName" SG_ 1157 DMSIntnDrvrCstAvlFlg1 "Driver Monitoring System Inattentive Driver Customization Availability Flag1";
BA_ "SignalType" SG_ 1157 DMSDrwIntnDrvrDtnAlrtMutReqd "ENM";
BA_ "SignalLongName" SG_ 1157 DMSDrwIntnDrvrDtnAlrtMutReqd "Driver Monitoring System Drowsy And Inattentive Driver Detection Alert Mute Requested";
BA_ "SignalType" SG_ 1157 DMSDrwIntnDrvrLvl1ChmEvntStat "ENM";
BA_ "SignalLongName" SG_ 1157 DMSDrwIntnDrvrLvl1ChmEvntStat "Driver Monitoring System Drowsy And Inattentive Driver Level 1 Chime Event State";
BA_ "SignalType" SG_ 1157 DMSDrwIntnDrvrLvl2ChmEvntStat "ENM";
BA_ "SignalLongName" SG_ 1157 DMSDrwIntnDrvrLvl2ChmEvntStat "Driver Monitoring System Drowsy And Inattentive Driver Level 2 Chime Event State";
BA_ "SignalType" SG_ 1157 DMSIntnDrvrCstSetAval "ENM";
BA_ "SignalLongName" SG_ 1157 DMSIntnDrvrCstSetAval "Driver Monitoring System Inattentive Driver Customization Setting Available";
BA_ "SignalType" SG_ 1157 DMSIntnDrvrCstAvlFlg7 "ENM";
BA_ "SignalLongName" SG_ 1157 DMSIntnDrvrCstAvlFlg7 "Driver Monitoring System Inattentive Driver Customization Availability Flag7";
BA_ "SignalType" SG_ 1157 DMSIntnDrvrCstAvlFlg6 "ENM";
BA_ "SignalLongName" SG_ 1157 DMSIntnDrvrCstAvlFlg6 "Driver Monitoring System Inattentive Driver Customization Availability Flag6";
BA_ "SignalType" SG_ 1157 DMSIntnDrvrCstAvlFlg5 "ENM";
BA_ "SignalLongName" SG_ 1157 DMSIntnDrvrCstAvlFlg5 "Driver Monitoring System Inattentive Driver Customization Availability Flag5";
BA_ "SignalType" SG_ 1157 DMSIntnDrvrCstAvlFlg4 "ENM";
BA_ "SignalLongName" SG_ 1157 DMSIntnDrvrCstAvlFlg4 "Driver Monitoring System Inattentive Driver Customization Availability Flag4";
BA_ "SignalType" SG_ 1157 DMSIntnDrvrCstAvlFlg3 "ENM";
BA_ "SignalLongName" SG_ 1157 DMSIntnDrvrCstAvlFlg3 "Driver Monitoring System Inattentive Driver Customization Availability Flag3";
BA_ "SignalType" SG_ 1157 DMSIntnDrvrCstAvlFlg2 "ENM";
BA_ "SignalLongName" SG_ 1157 DMSIntnDrvrCstAvlFlg2 "Driver Monitoring System Inattentive Driver Customization Availability Flag2";
BA_ "SignalType" SG_ 1155 HVBatSOCDspHdlmpCstAvlFlg1 "ENM";
BA_ "SignalLongName" SG_ 1155 HVBatSOCDspHdlmpCstAvlFlg1 "High Voltage Battery State of Charge Display Headlamp Customization Availability Flag 1";
BA_ "SignalType" SG_ 1155 InfoWndMtnCtlRRAval "ENM";
BA_ "SignalLongName" SG_ 1155 InfoWndMtnCtlRRAval "Infotainment Window Motion Control Right Rear Available";
BA_ "SignalType" SG_ 1155 InfoWndMtnCtlRFAval "ENM";
BA_ "SignalLongName" SG_ 1155 InfoWndMtnCtlRFAval "Infotainment Window Motion Control Right Front Available";
BA_ "SignalType" SG_ 1155 InfoWndMtnCtlLRAval "ENM";
BA_ "SignalLongName" SG_ 1155 InfoWndMtnCtlLRAval "Infotainment Window Motion Control Left Rear Available";
BA_ "SignalType" SG_ 1155 InfoWndMtnCtlLFAval "ENM";
BA_ "SignalLongName" SG_ 1155 InfoWndMtnCtlLFAval "Infotainment Window Motion Control Left Front Available";
BA_ "SignalType" SG_ 1155 InfoSnrfMtnCtlAval "ENM";
BA_ "SignalLongName" SG_ 1155 InfoSnrfMtnCtlAval "Infotainment Sunroof Motion Control Available";
BA_ "SignalType" SG_ 1155 VirtCtlIntrCmptRelCtlAval "ENM";
BA_ "SignalLongName" SG_ 1155 VirtCtlIntrCmptRelCtlAval "Virtual Control Interior Compartment Release Control Available";
BA_ "SignalType" SG_ 1155 Aux1AmbtColrCtlCstAvlFlg100 "ENM";
BA_ "SignalLongName" SG_ 1155 Aux1AmbtColrCtlCstAvlFlg100 "Auxiliary 1 Ambient Color Control Customization Availability Flag 100";
BA_ "SignalType" SG_ 1155 HVBatSOCDspHdlmpCstSetAval "ENM";
BA_ "SignalLongName" SG_ 1155 HVBatSOCDspHdlmpCstSetAval "High Voltage Battery State of Charge Display Headlamp Customization Setting Available";
BA_ "SignalType" SG_ 1155 HVBatSOCDspHdlmpCstAvlFlg7 "ENM";
BA_ "SignalLongName" SG_ 1155 HVBatSOCDspHdlmpCstAvlFlg7 "High Voltage Battery State of Charge Display Headlamp Customization Availability Flag 7";
BA_ "SignalType" SG_ 1155 HVBatSOCDspHdlmpCstAvlFlg6 "ENM";
BA_ "SignalLongName" SG_ 1155 HVBatSOCDspHdlmpCstAvlFlg6 "High Voltage Battery State of Charge Display Headlamp Customization Availability Flag 6";
BA_ "SignalType" SG_ 1155 HVBatSOCDspHdlmpCstAvlFlg5 "ENM";
BA_ "SignalLongName" SG_ 1155 HVBatSOCDspHdlmpCstAvlFlg5 "High Voltage Battery State of Charge Display Headlamp Customization Availability Flag 5";
BA_ "SignalType" SG_ 1155 HVBatSOCDspHdlmpCstAvlFlg4 "ENM";
BA_ "SignalLongName" SG_ 1155 HVBatSOCDspHdlmpCstAvlFlg4 "High Voltage Battery State of Charge Display Headlamp Customization Availability Flag 4";
BA_ "SignalType" SG_ 1155 HVBatSOCDspHdlmpCstAvlFlg3 "ENM";
BA_ "SignalLongName" SG_ 1155 HVBatSOCDspHdlmpCstAvlFlg3 "High Voltage Battery State of Charge Display Headlamp Customization Availability Flag 3";
BA_ "SignalType" SG_ 1155 HVBatSOCDspHdlmpCstAvlFlg2 "ENM";
BA_ "SignalLongName" SG_ 1155 HVBatSOCDspHdlmpCstAvlFlg2 "High Voltage Battery State of Charge Display Headlamp Customization Availability Flag 2";
BA_ "SignalType" SG_ 1155 Aux1AmbtColrCtlCstAvlFlg108 "ENM";
BA_ "SignalLongName" SG_ 1155 Aux1AmbtColrCtlCstAvlFlg108 "Auxiliary 1 Ambient Color Control Customization Availability Flag 108";
BA_ "SignalType" SG_ 1155 Aux1AmbtColrCtlCstAvlFlg107 "ENM";
BA_ "SignalLongName" SG_ 1155 Aux1AmbtColrCtlCstAvlFlg107 "Auxiliary 1 Ambient Color Control Customization Availability Flag 107";
BA_ "SignalType" SG_ 1155 Aux1AmbtColrCtlCstAvlFlg106 "ENM";
BA_ "SignalLongName" SG_ 1155 Aux1AmbtColrCtlCstAvlFlg106 "Auxiliary 1 Ambient Color Control Customization Availability Flag 106";
BA_ "SignalType" SG_ 1155 Aux1AmbtColrCtlCstAvlFlg105 "ENM";
BA_ "SignalLongName" SG_ 1155 Aux1AmbtColrCtlCstAvlFlg105 "Auxiliary 1 Ambient Color Control Customization Availability Flag 105";
BA_ "SignalType" SG_ 1155 Aux1AmbtColrCtlCstAvlFlg104 "ENM";
BA_ "SignalLongName" SG_ 1155 Aux1AmbtColrCtlCstAvlFlg104 "Auxiliary 1 Ambient Color Control Customization Availability Flag 104";
BA_ "SignalType" SG_ 1155 Aux1AmbtColrCtlCstAvlFlg103 "ENM";
BA_ "SignalLongName" SG_ 1155 Aux1AmbtColrCtlCstAvlFlg103 "Auxiliary 1 Ambient Color Control Customization Availability Flag 103";
BA_ "SignalType" SG_ 1155 Aux1AmbtColrCtlCstAvlFlg102 "ENM";
BA_ "SignalLongName" SG_ 1155 Aux1AmbtColrCtlCstAvlFlg102 "Auxiliary 1 Ambient Color Control Customization Availability Flag 102";
BA_ "SignalType" SG_ 1155 Aux1AmbtColrCtlCstAvlFlg101 "ENM";
BA_ "SignalLongName" SG_ 1155 Aux1AmbtColrCtlCstAvlFlg101 "Auxiliary 1 Ambient Color Control Customization Availability Flag 101";
BA_ "SignalType" SG_ 1155 Aux1AmbtColrCtlCstAvlFlg116 "ENM";
BA_ "SignalLongName" SG_ 1155 Aux1AmbtColrCtlCstAvlFlg116 "Auxiliary 1 Ambient Color Control Customization Availability Flag 116";
BA_ "SignalType" SG_ 1155 Aux1AmbtColrCtlCstAvlFlg115 "ENM";
BA_ "SignalLongName" SG_ 1155 Aux1AmbtColrCtlCstAvlFlg115 "Auxiliary 1 Ambient Color Control Customization Availability Flag 115";
BA_ "SignalType" SG_ 1155 Aux1AmbtColrCtlCstAvlFlg114 "ENM";
BA_ "SignalLongName" SG_ 1155 Aux1AmbtColrCtlCstAvlFlg114 "Auxiliary 1 Ambient Color Control Customization Availability Flag 114";
BA_ "SignalType" SG_ 1155 Aux1AmbtColrCtlCstAvlFlg113 "ENM";
BA_ "SignalLongName" SG_ 1155 Aux1AmbtColrCtlCstAvlFlg113 "Auxiliary 1 Ambient Color Control Customization Availability Flag 113";
BA_ "SignalType" SG_ 1155 Aux1AmbtColrCtlCstAvlFlg112 "ENM";
BA_ "SignalLongName" SG_ 1155 Aux1AmbtColrCtlCstAvlFlg112 "Auxiliary 1 Ambient Color Control Customization Availability Flag 112";
BA_ "SignalType" SG_ 1155 Aux1AmbtColrCtlCstAvlFlg111 "ENM";
BA_ "SignalLongName" SG_ 1155 Aux1AmbtColrCtlCstAvlFlg111 "Auxiliary 1 Ambient Color Control Customization Availability Flag 111";
BA_ "SignalType" SG_ 1155 Aux1AmbtColrCtlCstAvlFlg110 "ENM";
BA_ "SignalLongName" SG_ 1155 Aux1AmbtColrCtlCstAvlFlg110 "Auxiliary 1 Ambient Color Control Customization Availability Flag 110";
BA_ "SignalType" SG_ 1155 Aux1AmbtColrCtlCstAvlFlg109 "ENM";
BA_ "SignalLongName" SG_ 1155 Aux1AmbtColrCtlCstAvlFlg109 "Auxiliary 1 Ambient Color Control Customization Availability Flag 109";
BA_ "SignalType" SG_ 1155 Aux1AmbtColrCtlCstAvlFlg124 "ENM";
BA_ "SignalLongName" SG_ 1155 Aux1AmbtColrCtlCstAvlFlg124 "Auxiliary 1 Ambient Color Control Customization Availability Flag 124";
BA_ "SignalType" SG_ 1155 Aux1AmbtColrCtlCstAvlFlg123 "ENM";
BA_ "SignalLongName" SG_ 1155 Aux1AmbtColrCtlCstAvlFlg123 "Auxiliary 1 Ambient Color Control Customization Availability Flag 123";
BA_ "SignalType" SG_ 1155 Aux1AmbtColrCtlCstAvlFlg122 "ENM";
BA_ "SignalLongName" SG_ 1155 Aux1AmbtColrCtlCstAvlFlg122 "Auxiliary 1 Ambient Color Control Customization Availability Flag 122";
BA_ "SignalType" SG_ 1155 Aux1AmbtColrCtlCstAvlFlg121 "ENM";
BA_ "SignalLongName" SG_ 1155 Aux1AmbtColrCtlCstAvlFlg121 "Auxiliary 1 Ambient Color Control Customization Availability Flag 121";
BA_ "SignalType" SG_ 1155 Aux1AmbtColrCtlCstAvlFlg120 "ENM";
BA_ "SignalLongName" SG_ 1155 Aux1AmbtColrCtlCstAvlFlg120 "Auxiliary 1 Ambient Color Control Customization Availability Flag 120";
BA_ "SignalType" SG_ 1155 Aux1AmbtColrCtlCstAvlFlg119 "ENM";
BA_ "SignalLongName" SG_ 1155 Aux1AmbtColrCtlCstAvlFlg119 "Auxiliary 1 Ambient Color Control Customization Availability Flag 119";
BA_ "SignalType" SG_ 1155 Aux1AmbtColrCtlCstAvlFlg118 "ENM";
BA_ "SignalLongName" SG_ 1155 Aux1AmbtColrCtlCstAvlFlg118 "Auxiliary 1 Ambient Color Control Customization Availability Flag 118";
BA_ "SignalType" SG_ 1155 Aux1AmbtColrCtlCstAvlFlg117 "ENM";
BA_ "SignalLongName" SG_ 1155 Aux1AmbtColrCtlCstAvlFlg117 "Auxiliary 1 Ambient Color Control Customization Availability Flag 117";
BA_ "SignalType" SG_ 1155 Aux1AmbtColrCtlCstAvlFlg99 "ENM";
BA_ "SignalLongName" SG_ 1155 Aux1AmbtColrCtlCstAvlFlg99 "Auxiliary 1 Ambient Color Control Customization Availability Flag 99";
BA_ "SignalType" SG_ 1155 Aux1AmbtColrCtlCstAvlFlg98 "ENM";
BA_ "SignalLongName" SG_ 1155 Aux1AmbtColrCtlCstAvlFlg98 "Auxiliary 1 Ambient Color Control Customization Availability Flag 98";
BA_ "SignalType" SG_ 1155 Aux1AmbtColrCtlCstAvlFlg97 "ENM";
BA_ "SignalLongName" SG_ 1155 Aux1AmbtColrCtlCstAvlFlg97 "Auxiliary 1 Ambient Color Control Customization Availability Flag 97";
BA_ "SignalType" SG_ 1155 Aux1AmbtColrCtlCstAvlFlg96 "ENM";
BA_ "SignalLongName" SG_ 1155 Aux1AmbtColrCtlCstAvlFlg96 "Auxiliary 1 Ambient Color Control Customization Availability Flag 96";
BA_ "SignalType" SG_ 1155 Aux1AmbtColrCtlCstAvlFlg95 "ENM";
BA_ "SignalLongName" SG_ 1155 Aux1AmbtColrCtlCstAvlFlg95 "Auxiliary 1 Ambient Color Control Customization Availability Flag 95";
BA_ "SignalType" SG_ 1155 Aux1AmbtColrCtlCstAvlFlg127 "ENM";
BA_ "SignalLongName" SG_ 1155 Aux1AmbtColrCtlCstAvlFlg127 "Auxiliary 1 Ambient Color Control Customization Availability Flag 127";
BA_ "SignalType" SG_ 1155 Aux1AmbtColrCtlCstAvlFlg126 "ENM";
BA_ "SignalLongName" SG_ 1155 Aux1AmbtColrCtlCstAvlFlg126 "Auxiliary 1 Ambient Color Control Customization Availability Flag 126";
BA_ "SignalType" SG_ 1155 Aux1AmbtColrCtlCstAvlFlg125 "ENM";
BA_ "SignalLongName" SG_ 1155 Aux1AmbtColrCtlCstAvlFlg125 "Auxiliary 1 Ambient Color Control Customization Availability Flag 125";
BA_ "SignalType" SG_ 1911 VirtCtlIntrCmptRelReqd "ENM";
BA_ "SignalLongName" SG_ 1911 VirtCtlIntrCmptRelReqd "Virtual Control Interior Compartment Release Requested";
BA_ "SignalType" SG_ 1911 RrCtlDispFltIndOn "ENM";
BA_ "SignalLongName" SG_ 1911 RrCtlDispFltIndOn "Rear Control Display Fault Indication On";
VAL_ 1432 HVACFCRTLR_LtLvlActv 0 "FALSE" 1 "TRUE" ;
VAL_ 1432 HVACFCRTLR_RtLvlActv 0 "FALSE" 1 "TRUE" ;
VAL_ 1432 RHVSLF_VntLvlChgUp 0 "FALSE" 1 "TRUE" ;
VAL_ 1432 RHVSLF_VntLvlChgDn 0 "FALSE" 1 "TRUE" ;
VAL_ 1432 RHVSLF_HtdCushBckLvlChgUp 0 "FALSE" 1 "TRUE" ;
VAL_ 1432 RHVSLF_HtdCushBckLvlChgDn 0 "FALSE" 1 "TRUE" ;
VAL_ 1432 RHVSLF_HtdBckLvlChgUp 0 "FALSE" 1 "TRUE" ;
VAL_ 1432 RHVSLF_HtdBckLvlChgDn 0 "FALSE" 1 "TRUE" ;
VAL_ 1432 HVACFCRL_SetChg 0 "FALSE" 1 "TRUE" ;
VAL_ 1432 VntStStckSwRF 0 "FALSE" 1 "TRUE" ;
VAL_ 1432 RHVSRF_VntLvlChgUp 0 "FALSE" 1 "TRUE" ;
VAL_ 1432 RHVSRF_VntLvlChgDn 0 "FALSE" 1 "TRUE" ;
VAL_ 1432 RHVSRF_HtdCushBckLvlChgUp 0 "FALSE" 1 "TRUE" ;
VAL_ 1432 RHVSRF_HtdCushBckLvlChgDn 0 "FALSE" 1 "TRUE" ;
VAL_ 1432 RHVSRF_HtdBckLvlChgUp 0 "FALSE" 1 "TRUE" ;
VAL_ 1432 RHVSRF_HtdBckLvlChgDn 0 "FALSE" 1 "TRUE" ;
VAL_ 1471 PCOSN2_NtfnFrstRowRtStOccpSts 0 "Unknown" 1 "Empty" 2 "Occupied" 3 "Data Not Available" ;
VAL_ 1471 PCOSN2_NtfnFrstRowRtStBtSts 0 "Unknown" 1 "UnFastened" 2 "Fastened" 3 "Data Not Available" ;
VAL_ 1471 PCOSN2_NtfnFrstRowLtStOccpSts 0 "Unknown" 1 "Empty" 2 "Occupied" 3 "Data Not Available" ;
VAL_ 1471 PCOSN2_NtfnFrstRowLtStBtSts 0 "Unknown" 1 "UnFastened" 2 "Fastened" 3 "Data Not Availabl" ;
VAL_ 1471 PCOSN2_NtfnRrImpASevAchvd 0 "FALSE" 1 "TRUE" ;
VAL_ 1471 InfoFrtSnshdMtnCtlAval 0 "Not Available" 1 "Available" ;
VAL_ 1472 CustMdEVPedMpCstmAvFlg1 0 "FALSE" 1 "TRUE" ;
VAL_ 1474 CustMdEVPedMpCstmAvFlg2 0 "FALSE" 1 "TRUE" ;
VAL_ 1475 FrtStHtdBkLvlAval 0 "Not Available" 1 "Two Levels Available" 2 "Three Levels Available" 3 "Four Levels Available" ;
VAL_ 1475 RrStHtdCushBkLvlAval 0 "Not Available" 1 "Two Levels Available" 2 "Three Levels Available" 3 "Four Levels Available" ;
VAL_ 1475 RrStHtdBkLvlAval 0 "Not Available" 1 "Two Levels Available" 2 "Three Levels Available" 3 "Four Levels Available" ;
VAL_ 1475 FrtStVntCoolLvlAval 0 "Not Available" 1 "Two Levels Available" 2 "Three Levels Available" 3 "Four Levels Available" ;
VAL_ 1475 FrtStHtdCushBkLvlAval 0 "Not Available" 1 "Two Levels Available" 2 "Three Levels Available" 3 "Four Levels Available" ;
VAL_ 1475 RrStVntCoolLvlAval 0 "Not Available" 1 "Two Levels Available" 2 "Three Levels Available" 3 "Four Levels Available" ;
VAL_ 1475 CustMdEVPedMpCstmCurSetVal 0 "SETTING_UNKNOWN" 1 "CUSTOM_MODE_1" 2 "CUSTOM_MODE_2" 3 "CUSTOM_MODE_3" 4 "CUSTOM_MODE_4" 5 "CUSTOM_MODE_5" 6 "CUSTOM_MODE_6" 7 "CUSTOM_MODE_7" ;
VAL_ 1475 VhStShVehOnExtdMdSwReqd 0 "FALSE" 1 "TRUE" ;
VAL_ 1475 VSEMOpEndAllwdSts 0 "Unknown" 1 "Not Allowed" 2 "Allowed" ;
VAL_ 1475 CustMdEngyRegnCstmCurSetVal 0 "SETTING_UNKNOWN" 1 "CUSTOM_MODE_1" 2 "CUSTOM_MODE_2" 3 "CUSTOM_MODE_3" 4 "CUSTOM_MODE_4" 5 "CUSTOM_MODE_5" 6 "CUSTOM_MODE_6" 7 "CUSTOM_MODE_7" ;
VAL_ 1476 OffRdMdElecVehPedMpVisDispVal 0 "SETTING_UNKNOWN" 1 "CUSTOM_MODE_1" 2 "CUSTOM_MODE_2" 3 "CUSTOM_MODE_3" 4 "CUSTOM_MODE_4" 5 "CUSTOM_MODE_5" 6 "CUSTOM_MODE_6" 7 "CUSTOM_MODE_7" ;
VAL_ 1476 PrsnlMdEngyRegnCstmCurSetVal 0 "SETTING_UNKNOWN" 1 "CUSTOM_MODE_1" 2 "CUSTOM_MODE_2" 3 "CUSTOM_MODE_3" 4 "CUSTOM_MODE_4" 5 "CUSTOM_MODE_5" 6 "CUSTOM_MODE_6" 7 "CUSTOM_MODE_7" ;
VAL_ 1476 PrsnlMdEVPedMpCstmCurSetVal 0 "SETTING_UNKNOWN" 1 "CUSTOM_MODE_1" 2 "CUSTOM_MODE_2" 3 "CUSTOM_MODE_3" 4 "CUSTOM_MODE_4" 5 "CUSTOM_MODE_5" 6 "CUSTOM_MODE_6" 7 "CUSTOM_MODE_7" ;
VAL_ 1476 OffRdMdEngyRegnVisDispVal 0 "SETTING_UNKNOWN" 1 "CUSTOM_MODE_1" 2 "CUSTOM_MODE_2" 3 "CUSTOM_MODE_3" 4 "CUSTOM_MODE_4" 5 "CUSTOM_MODE_5" 6 "CUSTOM_MODE_6" 7 "CUSTOM_MODE_7" ;
VAL_ 1476 SprtMdEngyRegnVisDispVal 0 "SETTING_UNKNOWN" 1 "CUSTOM_MODE_1" 2 "CUSTOM_MODE_2" 3 "CUSTOM_MODE_3" 4 "CUSTOM_MODE_4" 5 "CUSTOM_MODE_5" 6 "CUSTOM_MODE_6" 7 "CUSTOM_MODE_7" ;
VAL_ 1476 SprtMdElecVehPedMpVisDispVal 0 "SETTING_UNKNOWN" 1 "CUSTOM_MODE_1" 2 "CUSTOM_MODE_2" 3 "CUSTOM_MODE_3" 4 "CUSTOM_MODE_4" 5 "CUSTOM_MODE_5" 6 "CUSTOM_MODE_6" 7 "CUSTOM_MODE_7" ;
VAL_ 1476 TourMdElecVehPedMpVisDispVal 0 "SETTING_UNKNOWN" 1 "CUSTOM_MODE_1" 2 "CUSTOM_MODE_2" 3 "CUSTOM_MODE_3" 4 "CUSTOM_MODE_4" 5 "CUSTOM_MODE_5" 6 "CUSTOM_MODE_6" 7 "CUSTOM_MODE_7" ;
VAL_ 1476 TkMdEngyRegnVisDispVal 0 "SETTING_UNKNOWN" 1 "CUSTOM_MODE_1" 2 "CUSTOM_MODE_2" 3 "CUSTOM_MODE_3" 4 "CUSTOM_MODE_4" 5 "CUSTOM_MODE_5" 6 "CUSTOM_MODE_6" 7 "CUSTOM_MODE_7" ;
VAL_ 1476 TkMdElecVehPedMpVisDispVal 0 "SETTING_UNKNOWN" 1 "CUSTOM_MODE_1" 2 "CUSTOM_MODE_2" 3 "CUSTOM_MODE_3" 4 "CUSTOM_MODE_4" 5 "CUSTOM_MODE_5" 6 "CUSTOM_MODE_6" 7 "CUSTOM_MODE_7" ;
VAL_ 1476 TrnMdBrkPedVisDispVal 0 "SETTING_UNKNOWN" 1 "CUSTOM_MODE_1" 2 "CUSTOM_MODE_2" 3 "CUSTOM_MODE_3" 4 "CUSTOM_MODE_4" 5 "CUSTOM_MODE_5" 6 "CUSTOM_MODE_6" 7 "CUSTOM_MODE_7" ;
VAL_ 1476 TrnMdActvAerodynsVisDispVal 0 "SETTING_UNKNOWN" 1 "CUSTOM_MODE_1" 2 "CUSTOM_MODE_2" 3 "CUSTOM_MODE_3" 4 "CUSTOM_MODE_4" 5 "CUSTOM_MODE_5" 6 "CUSTOM_MODE_6" 7 "CUSTOM_MODE_7" ;
VAL_ 1476 TourMdEngyRegnVisDispVal 0 "SETTING_UNKNOWN" 1 "CUSTOM_MODE_1" 2 "CUSTOM_MODE_2" 3 "CUSTOM_MODE_3" 4 "CUSTOM_MODE_4" 5 "CUSTOM_MODE_5" 6 "CUSTOM_MODE_6" 7 "CUSTOM_MODE_7" ;
VAL_ 1476 TrnMdESCVisDispVal 0 "SETTING_UNKNOWN" 1 "CUSTOM_MODE_1" 2 "CUSTOM_MODE_2" 3 "CUSTOM_MODE_3" 4 "CUSTOM_MODE_4" 5 "CUSTOM_MODE_5" 6 "CUSTOM_MODE_6" 7 "CUSTOM_MODE_7" ;
VAL_ 1476 TrnMdDrvlnVisDispVal 0 "SETTING_UNKNOWN" 1 "CUSTOM_MODE_1" 2 "CUSTOM_MODE_2" 3 "CUSTOM_MODE_3" 4 "CUSTOM_MODE_4" 5 "CUSTOM_MODE_5" 6 "CUSTOM_MODE_6" 7 "CUSTOM_MODE_7" ;
VAL_ 1476 TrnMdPwrtrnVisDispVal 0 "SETTING_UNKNOWN" 1 "CUSTOM_MODE_1" 2 "CUSTOM_MODE_2" 3 "CUSTOM_MODE_3" 4 "CUSTOM_MODE_4" 5 "CUSTOM_MODE_5" 6 "CUSTOM_MODE_6" 7 "CUSTOM_MODE_7" ;
VAL_ 1476 TrnMdEngyRegnVisDispVal 0 "SETTING_UNKNOWN" 1 "CUSTOM_MODE_1" 2 "CUSTOM_MODE_2" 3 "CUSTOM_MODE_3" 4 "CUSTOM_MODE_4" 5 "CUSTOM_MODE_5" 6 "CUSTOM_MODE_6" 7 "CUSTOM_MODE_7" ;
VAL_ 1476 TrnMdElecVehPedMpVisDispVal 0 "SETTING_UNKNOWN" 1 "CUSTOM_MODE_1" 2 "CUSTOM_MODE_2" 3 "CUSTOM_MODE_3" 4 "CUSTOM_MODE_4" 5 "CUSTOM_MODE_5" 6 "CUSTOM_MODE_6" 7 "CUSTOM_MODE_7" ;
VAL_ 1476 CustMdEVPedMpCstmAvFlg3 0 "FALSE" 1 "TRUE" ;
VAL_ 1476 TrnMdSndVisDispVal 0 "SETTING_UNKNOWN" 1 "CUSTOM_MODE_1" 2 "CUSTOM_MODE_2" 3 "CUSTOM_MODE_3" 4 "CUSTOM_MODE_4" 5 "CUSTOM_MODE_5" 6 "CUSTOM_MODE_6" 7 "CUSTOM_MODE_7" ;
VAL_ 1476 TrnMdRideHghtVisDispVal 0 "SETTING_UNKNOWN" 1 "CUSTOM_MODE_1" 2 "CUSTOM_MODE_2" 3 "CUSTOM_MODE_3" 4 "CUSTOM_MODE_4" 5 "CUSTOM_MODE_5" 6 "CUSTOM_MODE_6" 7 "CUSTOM_MODE_7" ;
VAL_ 1477 TrnMdStrgVisDispVal 0 "SETTING_UNKNOWN" 1 "CUSTOM_MODE_1" 2 "CUSTOM_MODE_2" 3 "CUSTOM_MODE_3" 4 "CUSTOM_MODE_4" 5 "CUSTOM_MODE_5" 6 "CUSTOM_MODE_6" 7 "CUSTOM_MODE_7" ;
VAL_ 1477 TrnMdSpnsnVisDispVal 0 "SETTING_UNKNOWN" 1 "CUSTOM_MODE_1" 2 "CUSTOM_MODE_2" 3 "CUSTOM_MODE_3" 4 "CUSTOM_MODE_4" 5 "CUSTOM_MODE_5" 6 "CUSTOM_MODE_6" 7 "CUSTOM_MODE_7" ;
VAL_ 1477 WthrMdEngyRegnVisDispVal 0 "SETTING_UNKNOWN" 1 "CUSTOM_MODE_1" 2 "CUSTOM_MODE_2" 3 "CUSTOM_MODE_3" 4 "CUSTOM_MODE_4" 5 "CUSTOM_MODE_5" 6 "CUSTOM_MODE_6" 7 "CUSTOM_MODE_7" ;
VAL_ 1477 WthrMdElecVehPedMpVisDispVal 0 "SETTING_UNKNOWN" 1 "CUSTOM_MODE_1" 2 "CUSTOM_MODE_2" 3 "CUSTOM_MODE_3" 4 "CUSTOM_MODE_4" 5 "CUSTOM_MODE_5" 6 "CUSTOM_MODE_6" 7 "CUSTOM_MODE_7" ;
VAL_ 1477 CustMdEVPedMpCstmAvFlg4 0 "FALSE" 1 "TRUE" ;
VAL_ 1477 HtdStrgWhlLvlAval 0 "Not Available" 1 "Two Levels Available" 2 "Three Levels Available" 3 "Four Levels Available" ;
VAL_ 1477 CustMdEngyRegnCstmAvFlg4 0 "FALSE" 1 "TRUE" ;
VAL_ 1477 CustMdEngyRegnCstmAvFlg3 0 "FALSE" 1 "TRUE" ;
VAL_ 1477 CustMdEngyRegnCstmAvFlg2 0 "FALSE" 1 "TRUE" ;
VAL_ 1477 CustMdEngyRegnCstmAvFlg1 0 "FALSE" 1 "TRUE" ;
VAL_ 1477 CustMdEVPedMpCstmSetAv 0 "FALSE" 1 "TRUE" ;
VAL_ 1477 CustMdEVPedMpCstmAvFlg7 0 "FALSE" 1 "TRUE" ;
VAL_ 1477 CustMdEVPedMpCstmAvFlg6 0 "FALSE" 1 "TRUE" ;
VAL_ 1477 CustMdEVPedMpCstmAvFlg5 0 "FALSE" 1 "TRUE" ;
VAL_ 1477 OnePedDrvCstSetAllwdFlg3 0 "FALSE" 1 "TRUE" ;
VAL_ 1477 OnePedDrvCstSetAllwdFlg2 0 "FALSE" 1 "TRUE" ;
VAL_ 1477 OnePedDrvCstSetAllwdFlg1 0 "FALSE" 1 "TRUE" ;
VAL_ 1477 CustMdEngyRegnCstmSetAv 0 "FALSE" 1 "TRUE" ;
VAL_ 1477 CustMdEngyRegnCstmAvFlg7 0 "FALSE" 1 "TRUE" ;
VAL_ 1477 CustMdEngyRegnCstmAvFlg6 0 "FALSE" 1 "TRUE" ;
VAL_ 1477 CustMdEngyRegnCstmAvFlg5 0 "FALSE" 1 "TRUE" ;
VAL_ 1477 OnePedDrvCstSetAvlFlg3 0 "FALSE" 1 "TRUE" ;
VAL_ 1477 OnePedDrvCstSetAvlFlg2 0 "FALSE" 1 "TRUE" ;
VAL_ 1477 OnePedDrvCstSetAvlFlg1 0 "FALSE" 1 "TRUE" ;
VAL_ 1477 OnePedDrvCstSetAval 0 "FALSE" 1 "TRUE" ;
VAL_ 1477 OnePedDrvCstSetAllwdFlg7 0 "FALSE" 1 "TRUE" ;
VAL_ 1477 OnePedDrvCstSetAllwdFlg6 0 "FALSE" 1 "TRUE" ;
VAL_ 1477 OnePedDrvCstSetAllwdFlg5 0 "FALSE" 1 "TRUE" ;
VAL_ 1477 OnePedDrvCstSetAllwdFlg4 0 "FALSE" 1 "TRUE" ;
VAL_ 1477 PrsnlMdEVPedMpCstmAvFlg3 0 "FALSE" 1 "TRUE" ;
VAL_ 1477 PrsnlMdEVPedMpCstmAvFlg2 0 "FALSE" 1 "TRUE" ;
VAL_ 1477 PrsnlMdEVPedMpCstmAvFlg1 0 "FALSE" 1 "TRUE" ;
VAL_ 1477 OnePedDrvCstSetAvlFlg7 0 "FALSE" 1 "TRUE" ;
VAL_ 1477 OnePedDrvCstSetAvlFlg6 0 "FALSE" 1 "TRUE" ;
VAL_ 1477 OnePedDrvCstSetAvlFlg5 0 "FALSE" 1 "TRUE" ;
VAL_ 1477 OnePedDrvCstSetAvlFlg4 0 "FALSE" 1 "TRUE" ;
VAL_ 1477 PrsnlMdEngyRegnCstmAvFlg3 0 "FALSE" 1 "TRUE" ;
VAL_ 1477 PrsnlMdEngyRegnCstmAvFlg2 0 "FALSE" 1 "TRUE" ;
VAL_ 1477 PrsnlMdEngyRegnCstmAvFlg1 0 "FALSE" 1 "TRUE" ;
VAL_ 1477 PrsnlMdEVPedMpCstmSetAv 0 "FALSE" 1 "TRUE" ;
VAL_ 1477 PrsnlMdEVPedMpCstmAvFlg7 0 "FALSE" 1 "TRUE" ;
VAL_ 1477 PrsnlMdEVPedMpCstmAvFlg6 0 "FALSE" 1 "TRUE" ;
VAL_ 1477 PrsnlMdEVPedMpCstmAvFlg5 0 "FALSE" 1 "TRUE" ;
VAL_ 1477 PrsnlMdEVPedMpCstmAvFlg4 0 "FALSE" 1 "TRUE" ;
VAL_ 1496 PwrFrtStrgeCmptClsrCstAvlFlg2 0 "FALSE" 1 "TRUE" ;
VAL_ 1496 PwrFrtStrgeCmptClsrCstAvlFlg1 0 "FALSE" 1 "TRUE" ;
VAL_ 1496 PrsnlMdEngyRegnCstmSetAv 0 "FALSE" 1 "TRUE" ;
VAL_ 1496 PrsnlMdEngyRegnCstmAvFlg7 0 "FALSE" 1 "TRUE" ;
VAL_ 1496 PrsnlMdEngyRegnCstmAvFlg6 0 "FALSE" 1 "TRUE" ;
VAL_ 1496 PrsnlMdEngyRegnCstmAvFlg5 0 "FALSE" 1 "TRUE" ;
VAL_ 1496 PrsnlMdEngyRegnCstmAvFlg4 0 "FALSE" 1 "TRUE" ;
VAL_ 1496 VirtCtlAccCktCtlAval 0 "Not Available" 1 "Available" ;
VAL_ 1496 PwrFrtStrgeCmptClsrCstSetAval 0 "FALSE" 1 "TRUE" ;
VAL_ 1496 PwrFrtStrgeCmptClsrCstAvlFlg7 0 "FALSE" 1 "TRUE" ;
VAL_ 1496 PwrFrtStrgeCmptClsrCstAvlFlg6 0 "FALSE" 1 "TRUE" ;
VAL_ 1496 PwrFrtStrgeCmptClsrCstAvlFlg5 0 "FALSE" 1 "TRUE" ;
VAL_ 1496 PwrFrtStrgeCmptClsrCstAvlFlg4 0 "FALSE" 1 "TRUE" ;
VAL_ 1496 PwrFrtStrgeCmptClsrCstAvlFlg3 0 "FALSE" 1 "TRUE" ;
VAL_ 1496 VirtOnePedDrvUserCtlAllwd 0 "Allowed" 1 "Not Allowed" ;
VAL_ 1496 VirtOnePedDrvCtlAval 0 "Not Available" 1 "Available" ;
VAL_ 1496 VirtCtlAuxAlrmSnsCtlAval 0 "Not Available" 1 "Available" ;
VAL_ 1504 DispdEstdCbnTemp_Inv 0 "FALSE" 1 "TRUE" ;
VAL_ 1504 HiVltgBatDispTempLvlPct_DuD 0 "FALSE" 1 "TRUE" ;
VAL_ 1504 CbnPrcndtngSts 0 "No Action" 1 "Inactive" 2 "Active" 3 "Performance Limited" 4 "Cabin At Target" 5 "Disabled" ;
VAL_ 1504 HiVltgBatPrcndtngSts 0 "No Action" 1 "Inactive" 2 "Active" 3 "Performance Limited" 4 "Battery At Target" 5 "Disabled" ;
VAL_ 1504 HiVltgBatPrcndtngSts_DuD 0 "FALSE" 1 "TRUE" ;
VAL_ 1504 CbnPrcndtngSchTempCstSetAval 0 "FALSE" 1 "TRUE" ;
VAL_ 1504 OnePedDrvCstCurrSetVal 0 "Setting Unknown" 1 "Level 1" 2 "Level 2" 3 "Level 3" 4 "Level 4" ;
VAL_ 1504 HiVltgBatLoSOCIndReq 0 "No Action" 1 "Warning Level 1" 2 "Warning Level 2" 3 "Warning Level 3" ;
VAL_ 1504 HiVltgBatLoSOCIndReq_DuD 0 "FALSE" 1 "TRUE" ;
VAL_ 1505 OnePedDrvCurrSeltnVal 0 "Unknown" 1 "On" 2 "Off" ;
VAL_ 1505 FrtStrgeCmptClsrLckSts 0 "Unknown" 1 "Unlocked" 2 "Locked" ;
VAL_ 1505 AuxAlrmSnsCurrSeltnVal 0 "Unknown" 1 "On" 2 "Off" ;
VAL_ 1505 PwrFrtStrgeCmptClsrCstCurSetVal 0 "Setting Unknown" 1 "Off" 2 "On" 3 "On - Custom Height" ;
VAL_ 1505 VirtCtlAccCkt3CurrSeltnVal 0 "Unknown" 1 "On" 2 "Off" 3 "Failed" ;
VAL_ 1505 VirtCtlAccCkt2CurrSeltnVal 0 "Unknown" 1 "On" 2 "Off" 3 "Failed" ;
VAL_ 1505 VirtCtlAccCkt1CurrSeltnVal 0 "Unknown" 1 "On" 2 "Off" 3 "Failed" ;
VAL_ 1505 OnePedDrvWrnIndReq 0 "No Action" 1 "Forced Exit" ;
VAL_ 1505 HVDCFstChrgPerfLtdIndOn 0 "FALSE" 1 "TRUE" ;
VAL_ 1505 VirtCtlAccCkt6CurrSeltnVal 0 "Unknown" 1 "On" 2 "Off" 3 "Failed" ;
VAL_ 1505 VirtCtlAccCkt5CurrSeltnVal 0 "Unknown" 1 "On" 2 "Off" 3 "Failed" ;
VAL_ 1505 VirtCtlAccCkt4CurrSeltnVal 0 "Unknown" 1 "On" 2 "Off" 3 "Failed" ;
VAL_ 1505 OnePedDrvIndOn 0 "FALSE" 1 "TRUE" ;
VAL_ 1505 HVDCFstChrgPrepCmpltIndOn 0 "FALSE" 1 "TRUE" ;
VAL_ 1505 ADASLtdCpbltyStatRsnIndReq 0 "No Indication" 1 "No Communication to Navigation" 2 "No Route Entered" 3 "Sensor Blocked" 4 "Sensor Failed" 5 "Sensor Unavailable" 6 "Camera Blocked" 7 "Camera Failed" 8 "Camera Unavailable" 9 "Turn Signal Failure" 10 "Driver Has Taken Control" 11 "Trailer Connected" ;
VAL_ 1505 PrplSysMaxPwrModeUnvRsn 0 "No Indication" 1 "Charge Battery" 2 "Temperature Too Cold" 3 "Reason 3" 4 "Reason 4" 5 "Reason 5" 6 "Reason 6" 7 "Reason 7" ;
VAL_ 1505 ADASMsgDispLocLtdPerfRsnInd 0 "None" 1 "Cluster Display" 2 "Center Stack Display" 3 "Both" ;
VAL_ 1505 ADASLtdCpbltyStatIndReq 0 "No Indication" 1 "Map Route Not Available" 2 "Low Velocity Maneuvers Not Available" 3 "Drive Straight Only" 4 "Highway Only" 5 "Longitudinal Override" 6 "Lateral Override" ;
VAL_ 929 B2RChmEvntStat 0 "No Action" 1 "Active" 2 "Cancel Chime" ;
VAL_ 206 POFT_PstnOfstFrmTrmLF_Inv 0 "FALSE" 1 "TRUE" ;
VAL_ 206 POFT_PstnOfstFrmTrmLR_Inv 0 "FALSE" 1 "TRUE" ;
VAL_ 206 POFT_PstnOfstFrmTrmRF_Inv 0 "FALSE" 1 "TRUE" ;
VAL_ 206 POFT_PstnOfstFrmTrmRR_Inv 0 "FALSE" 1 "TRUE" ;
VAL_ 206 RideHghtMaxPwrModeOvrrd 0 "FALSE" 1 "TRUE" ;
VAL_ 1535 PwrFrtStrgeCmptClsrCstChgSetReq 0 "No Action" 1 "Off" 2 "On" 3 "On - Custom Height" ;
VAL_ 1246 ElecRateSchedSsnStrtMthReq 0 "No Action" 1 "January" 2 "February" 3 "March" 4 "April" 5 "May" 6 "June" 7 "July" 8 "August" 9 "September" 10 "October" 11 "November" 12 "December" ;
VAL_ 1246 ElecRateSchedSsnReq 0 "No Action" 1 "Summer" 2 "Winter" 3 "Yearly" ;
VAL_ 1246 InfoFrtLtStHtdCushBkLvlReq 0 "No Action" 1 "Off" 2 "Auto" 3 "Low" 4 "Medium" 5 "High" ;
VAL_ 1246 InfoFrtLtStHtdBkLvlReq 0 "No Action" 1 "Off" 2 "Auto" 3 "Low" 4 "Medium" 5 "High" ;
VAL_ 1246 InfoFrtRtStHtdCushBkLvlReq 0 "No Action" 1 "Off" 2 "Auto" 3 "Low" 4 "Medium" 5 "High" ;
VAL_ 1246 InfoFrtRtStHtdBkLvlReq 0 "No Action" 1 "Off" 2 "Auto" 3 "Low" 4 "Medium" 5 "High" ;
VAL_ 1246 InfoFrtLtStVntCoolLvlReq 0 "No Action" 1 "Off" 2 "Auto" 3 "Low" 4 "Medium" 5 "High" ;
VAL_ 1246 InfoRrLtStHtdBkLvlReq 0 "No Action" 1 "Off" 2 "Auto" 3 "Low" 4 "Medium" 5 "High" ;
VAL_ 1246 InfoFrtRtStVntCoolLvlReq 0 "No Action" 1 "Off" 2 "Auto" 3 "Low" 4 "Medium" 5 "High" ;
VAL_ 1246 InfoRrRtStHtdBkLvlReq 0 "No Action" 1 "Off" 2 "Auto" 3 "Low" 4 "Medium" 5 "High" ;
VAL_ 1246 InfoRrLtStVntCoolLvlReq 0 "No Action" 1 "Off" 2 "Auto" 3 "Low" 4 "Medium" 5 "High" ;
VAL_ 1246 InfoRrLtStHtdCushBkLvlReq 0 "No Action" 1 "Off" 2 "Auto" 3 "Low" 4 "Medium" 5 "High" ;
VAL_ 1246 InfoRrRtStVntCoolLvlReq 0 "No Action" 1 "Off" 2 "Auto" 3 "Low" 4 "Medium" 5 "High" ;
VAL_ 1246 InfoRrRtStHtdCushBkLvlReq 0 "No Action" 1 "Off" 2 "Auto" 3 "Low" 4 "Medium" 5 "High" ;
VAL_ 1246 OnePedDrvCstChgSetReq 0 "No Action" 1 "Level 1" 2 "Level 2" 3 "Level 3" 4 "Level 4" ;
VAL_ 1246 InfoHtdStrgWhlLvlReq 0 "No Action" 1 "Off" 2 "Auto" 3 "Low" 4 "Medium" 5 "High" ;
VAL_ 1246 VirtCtlAccCkt2Req 0 "No Action" 1 "Momentary On" 2 "Momentary Lightbar On" 3 "Latch On" 4 "Latch Lightbar On" 5 "Off" ;
VAL_ 1246 VirtCtlAccCkt1Req 0 "No Action" 1 "Momentary On" 2 "Momentary Lightbar On" 3 "Latch On" 4 "Latch Lightbar On" 5 "Off" ;
VAL_ 1229 VirtCtlAccCkt5Req 0 "No Action" 1 "Momentary On" 2 "Momentary Lightbar On" 3 "Latch On" 4 "Latch Lightbar On" 5 "Off" ;
VAL_ 1229 VirtCtlAccCkt4Req 0 "No Action" 1 "Momentary On" 2 "Momentary Lightbar On" 3 "Latch On" 4 "Latch Lightbar On" 5 "Off" ;
VAL_ 1229 VirtCtlAccCkt3Req 0 "No Action" 1 "Momentary On" 2 "Momentary Lightbar On" 3 "Latch On" 4 "Latch Lightbar On" 5 "Off" ;
VAL_ 1229 VirtOnePedDrvReq 0 "No Action" 1 "On" 2 "Off" ;
VAL_ 1229 VirtCtlAccCkt6Req 0 "No Action" 1 "Momentary On" 2 "Momentary Lightbar On" 3 "Latch On" 4 "Latch Lightbar On" 5 "Off" ;
VAL_ 1229 HVDCFstChrgSoonReq 0 "No Action" 1 "Off" 2 "On" ;
VAL_ 1229 CustMdEngyRegnCstChngSetReq 0 "NO ACTION" 1 "CUSTOM_MODE_1" 2 "CUSTOM_MODE_2" 3 "CUSTOM_MODE_3" 4 "CUSTOM_MODE_4" 5 "CUSTOM_MODE_5" 6 "CUSTOM_MODE_6" 7 "CUSTOM_MODE_7" ;
VAL_ 1229 CustMdEVPedMpCstChngSetReq 0 "NO ACTION" 1 "CUSTOM_MODE_1" 2 "CUSTOM_MODE_2" 3 "CUSTOM_MODE_3" 4 "CUSTOM_MODE_4" 5 "CUSTOM_MODE_5" 6 "CUSTOM_MODE_6" 7 "CUSTOM_MODE_7" ;
VAL_ 1229 CbnPrcndtngSchTempCstSetReqAtv 0 "FALSE" 1 "TRUE" ;
VAL_ 1229 ChrgCordThftAlrtCstSetReq 0 "No Action" 1 "Off" 2 "On" ;
VAL_ 1229 PrsnlMdEngyRegnCstChngSetReq 0 "NO ACTION" 1 "PERSONAL_MODE_1" 2 "PERSONAL_MODE_2" 3 "PERSONAL_MODE_3" 4 "PERSONAL_MODE_4" 5 "PERSONAL_MODE_5" 6 "PERSONAL_MODE_6" 7 "PERSONAL_MODE_7" ;
VAL_ 1229 PrsnlMdEVPedMpCstChngSetReq 0 "NO ACTION" 1 "PERSONAL_MODE_1" 2 "PERSONAL_MODE_2" 3 "PERSONAL_MODE_3" 4 "PERSONAL_MODE_4" 5 "PERSONAL_MODE_5" 6 "PERSONAL_MODE_6" 7 "PERSONAL_MODE_7" ;
VAL_ 1229 HVBatSOCDspHdlmpCstChgSetReq 0 "No Action" 1 "Off" 2 "On" ;
VAL_ 931 RmtVehStrtPwrtrnFlrRsn 0 "None" 1 "Engine Speed High" 2 "Engine Over Temperature" 3 "Powertrain Crank Aborted" 4 "Engine Oil Pressure Low" 5 "Maximum Crank Time Exceeded" 6 "Malfunction Indicator Lamp Illuminated" 7 "RVS Backup Timer Expired" 8 "Accelerator Pedal Position High" 9 "Transmission Range Not Park" 10 "Vehicle Speed Not Zero" 11 "Vehicle Theft Disable" 12 "Transfer Case In Neutral" 13 "Remaining RVS Count Equals Zero" 14 "Low Fuel Level" 15 "NOx Reductant Fluid Level Low or Empty" 16 "Low Fuel Level Due To Grade" ;
VAL_ 931 RmtVehStrtBdyFlrRsn 0 "None" 1 "Valet Mode Active" 2 "Powetrain Run Aborted" 3 "Start Stop Switch Monitored Failed Signal is True" 4 "Hood Input Fault" 5 "Hood Ajar" 6 "Hazards Active" 7 "PushButton Starting Fob in Vehicle" 8 "Powertrain Crank Abort" 9 "Brake To Shift Interlock Fault" 10 "Content Theft State" 11 "Vehicle Power Mode not Off" 12 "Remote Vehicle Start Voltage Out Of Range" 13 "RVS Max Crank Time Exceeded" 14 "Convertible Top Not Fully Open or Fully Closed" ;
VAL_ 1837 TlmHVDCFstChrgSoonReq 0 "No Action" 1 "Off" 2 "On" ;
VAL_ 1837 TnDrvrOvrspdWrnRmtCstChgSetReq 0 "No Action" 1 "Off" 2 "On" ;
VAL_ 1837 TnDrStBltShIntlkRtCstLvChgSetRq 0 "No Action" 1 "Off" 2 "On" ;
VAL_ 940 VirtKeyCmdFailRsnReq 0 "No Request" 1 "Request RVS Fail Reason" ;
VAL_ 1467 SuprCruzSbscrptnActv 0 "FALSE" 1 "TRUE" ;
VAL_ 714 LIB1TempFlt 0 "No Fault" 1 "Low Severity" 2 "Medium Severity" 3 "High Severity" ;
VAL_ 714 LIB1TempFlt_Inv 0 "FALSE" 1 "TRUE" ;
VAL_ 1469 IndHtrSet 0 "Heater Off" 1 "Heater On" ;
VAL_ 1469 ICMTrngOncmgTrfcChmEvntStat 0 "No Action" 1 "Active" 2 "Cancel Chime" ;
VAL_ 1469 ICMRtChmEvntStat 0 "No Action" 1 "Active" 2 "Cancel Chime" ;
VAL_ 1469 ICMLtChmEvntStat 0 "No Action" 1 "Active" 2 "Cancel Chime" ;
VAL_ 1469 SuprRmtPrkWrnIndReq 0 "Off" 1 "Searching Parallel Right" 2 "Searching Parallel Left" 3 "Searching Cross Right" 4 "Searching Cross Left" 5 "Spot Found" 6 "Spot Found Parallel Left" 7 "Spot Found Cross Left" 8 "Spot Found Parallel Right" 9 "Spot Found Cross Right" 10 "Move Ahead" 11 "Move Ahead Parallel Left" 12 "Move Ahead Cross Left" 13 "Move Ahead Parallel Right" 14 "Move Ahead Cross Right" 15 "Stop And R Parallel Left" 16 "Stop And R Cross Back Left" 17 "Stop And R Cross Front Left" 18 "Stop And R Parallel Right" 19 "Stop And R Cross Back Right" 20 "Stop And R Cross Front Right" 21 "Search Speed Warning" 22 "Search Deactivated" 23 "Exit Park To Left" 24 "Exit Park To Right" 25 "Select Drive GEAR" 26 "Auto Steering Active" 27 "Auto Parking Active" 28 "Drive Backward" 29 "Backward Move" 30 "Drive Forward" 31 "Forward Move" 32 "Stop" 33 "Shifting" 34 "Position Reached" 35 "Take Control" 36 "ParkIng Complete" 37 "Exit Park Complete" 38 "Deactivated" 39 "Canceled General" 40 "Canceled Moves" 41 "Canceled Speed" 42 "Canceled Interference" 43 "Canceled Exit Park" 44 "Stopping" 45 "Auto Parking Complete" 46 "Release Brake" 47 "In Vehicle Or Remote" 48 "Remote Stay Alert" 49 "Remote Connecting" 50 "Remote Cannot Connect" 51 "Remote No Device" 52 "Remote Shift To Park" 53 "Remote Retry" 54 "Remote Canceled Range" 55 "Remote Canceled Supervision" 56 "Remote Canceled ConnectIon" 57 "Remote Paused Range" 58 "Remote Paused Supervision" 59 "Remote Paused ConnectIon" 60 "Search Drawer Exit" 61 "Search Drawer Park" 62 "Spot Selection Accept" 63 "Unable To Connect" 64 "Cancel Door" 65 "Pause Obstruction" 66 "Cancel Obstruction" 67 "No Exit Spot Found" 68 "Handshake Failure" 69 "Failed To Engage" 70 "Fasten Seatbelt" ;
VAL_ 1469 SuprRmtPrkFcsReq 0 "No Request" 1 "Focus Request IPC" 2 "Focus Request CSM" 3 "Focus Request VCU" ;
VAL_ 1469 SuprRmtPrkAutoStrgIconReq 0 "No Icon" 1 "Active" 2 "Deactivated" ;
VAL_ 1469 SuprRmtPrkUnabletoCnctExtReq 0 "Hidden" 1 "Disabled" 2 "Enabled" 3 "Highlighted" ;
VAL_ 1469 SuprRmtPrkSptSeltnRmtReq 0 "Hidden" 1 "Disabled" 2 "Enabled" 3 "Highlighted" ;
VAL_ 1469 SuprRmtPrkSptSeltnKeepLkReq 0 "Hidden" 1 "Disabled" 2 "Enabled" 3 "Highlighted" ;
VAL_ 1469 SuprRmtPrkSptSeltnAcceptReq 0 "Hidden" 1 "Disabled" 2 "Enabled" 3 "Highlighted" ;
VAL_ 1469 SuprRmtPrkDctvSftBtnReq 0 "Hidden" 1 "Disabled" 2 "Enabled" 3 "Highlighted" ;
VAL_ 1469 SuprRmtPrkUnabletoCnctTryAgnReq 0 "Hidden" 1 "Disabled" 2 "Enabled" 3 "Highlighted" ;
VAL_ 1470 IBS12VEstdBatTemp_Inv 0 "FALSE" 1 "TRUE" ;
VAL_ 1470 RrStrgOprtlStsAuth 0 "Unknown" 1 "Normal" 2 "Temporarily Unavailable" 3 "Reduced Performance" 4 "Failed" 5 "Normal & Active Safety Control" 6 "Reserved" ;
VAL_ 1470 RrStrgAlgnCmpltAuth 0 "FALSE" 1 "TRUE" ;
VAL_ 1470 RrStrgActlPerfMode 0 "No Action" 1 "Normal" 2 "Sport" 3 "Comfort" 4 "Track" 5 "Tow/Haul" 6 "City/Offroad" 7 "Terrain" ;
VAL_ 1470 RrStrgActlModeAuth 0 "Automatic" 1 "Fixed" 2 "Crab" 3 "None" ;
VAL_ 1470 RrStrgRdWhlAngAuth_DuD 0 "FALSE" 1 "TRUE" ;
VAL_ 1470 RrStrgRdWhlAngAuth_Inv 0 "FALSE" 1 "TRUE" ;
VAL_ 1470 CrtsyLgtSmrtIconReqd 0 "FALSE" 1 "TRUE" ;
VAL_ 1473 ActvTrlrProfLifetmEcon_DuD 0 "FALSE" 1 "TRUE" ;
VAL_ 1473 PnCStsDisp 0 "No Action" 1 "No Errors" 2 "Unplug And Replug" 3 "Two Factor Authentication Failure" 4 "Try Different Charging Station" 5 "Install Contract or Private Operator Certificate" 6 "Contract Certificate Invalid" 7 "Service Vehicle" 8 "Certificate Revoked" ;
VAL_ 1473 ActvTrlrProfLifetmEcon_Inv 0 "FALSE" 1 "TRUE" ;
VAL_ 1473 PTExPrtclFltrMnlRgnSts 0 "Cleaning Not Required" 1 "Allowed" 2 "Not Allowed" 3 "In Progress" 4 "Complete" 5 "Pending Driver Input" 6 "Not Available" 7 "Do Not Press Pedals" ;
VAL_ 1473 ICMWrnIndReq 0 "Off" 1 "Left" 2 "Right" 3 "Oncoming" ;
VAL_ 1473 EngAftRunIndReq 0 "No Action" 1 "No Indication" 2 "Idle Needed" 3 "Overheated" 4 "Interrupted" ;
VAL_ 1473 PnCEnbldSts 0 "Unknown" 1 "Enabled" 2 "Disabled" ;
VAL_ 1473 AutoCoolServFllIndReq 0 "No Indication" 1 "ACSF Enabled" 2 "ACSF Completed Successfully" 3 "ACSF Canceled" ;
VAL_ 1473 RrStrgModeUnvIndReq 0 "No Indication" 1 "Speed Too High" 2 "Incorrect Gear" 3 "Mode Unavailable" 4 "Steering Too Fast" 5 "Automated Driving 1" 6 "Automated Driving 2" ;
VAL_ 1473 PwrFrtStrgeCmptMtnSts 0 "Unknown" 1 "Closed" 2 "Opening" 3 "Closing" 4 "Stopped - Normal" 5 "Stopped - Obstacle" 6 "Closing - Hold System Fault" 7 "Fully Opened" 8 "Opening Due To Obstacle" 9 "Closing Due To Obstacle" 10 "Released To Ajar" 11 "Released To Open" 12 "System Unavailable" ;
VAL_ 1473 RrStrgModeSeltnIndOn 0 "FALSE" 1 "TRUE" ;
VAL_ 1473 PTExPrtclFltrWrn3IndOn 0 "FALSE" 1 "TRUE" ;
VAL_ 1473 HdLmpSmrtCtlPrmtReqd 0 "FALSE" 1 "TRUE" ;
VAL_ 1473 ESCUnvTopDnIndOn 0 "FALSE" 1 "TRUE" ;
VAL_ 1473 RIMObjAtchdIndOn 0 "FALSE" 1 "TRUE" ;
VAL_ 1473 RIMElecPrkBrkRelIndOn 0 "FALSE" 1 "TRUE" ;
VAL_ 1473 UpftrVehStrtEnblIndReq 0 "No Indication" 1 "On" 2 "Off" 3 "Not Available" ;
VAL_ 1473 MaxPwrModeDndIndOn 0 "FALSE" 1 "TRUE" ;
VAL_ 1473 DrvModeConfIndReq 0 "No Indication" 1 "Baja ESC Reduced" 2 "Terrain ESC Off" 3 "Max Power" 4 "Confirmation 4" 5 "Confirmation 5" 6 "Confirmation 6" 7 "Confirmation 7" ;
VAL_ 1892 LnchCtlSts 0 "No Action" 1 "Unavailable" 2 "Available" 3 "Armed" 4 "Active" 5 "Generic Unused 5" 6 "Generic Unused 6" 7 "Generic Unused 7" ;
VAL_ 1892 LnchCtlCchTrgrd 0 "FALSE" 1 "TRUE" ;
VAL_ 1892 AmbtLgtGblPrxmtyEnCstCurrSetVal 0 "Setting Unknown" 1 "Enable" 2 "Disable" ;
VAL_ 1892 LnchCtlUnvRsn 0 "No Indication" 1 "Steering Turned" 2 "Generic Unused 2" 3 "Generic Unused 3" 4 "Generic Unused 4" 5 "Generic Unused 5" 6 "Generic Unused 6" 7 "Generic Unused 7" ;
VAL_ 732 PSATIP_PriATActlAuth_Inv 0 "FALSE" 1 "TRUE" ;
VAL_ 732 SSID1P_LngAccelAuth_Inv 0 "FALSE" 1 "TRUE" ;
VAL_ 732 LIB1AvgTemp_Inv 0 "FALSE" 1 "TRUE" ;
VAL_ 196 FCATgtObjSeltnDispSnsrCnfd 0 "None" 1 "Low" 2 "Medium" 3 "High" ;
VAL_ 1173 PnCActnReqCertfctTyp 0 "None" 1 "GM Provisioning Certificate" 2 "Contract Certificate" 3 "V2G Root Certificate" 4 "OCSP Certificate" 5 "Private Operator Root Certificate" 6 "Reserved1" 7 "Reserved2" 8 "Reserved3" 9 "Reserved4" 10 "Reserved5" 11 "Reserved6" 12 "Reserved7" 13 "Reserved8" 14 "All Contract And Private Operator Root Certificates" ;
VAL_ 1173 PnCActnReqCertfctOp 0 "No Action" 1 "Disable Certificate" 2 "Enable Certificate" 3 "Erase Certificate" 4 "Install Certificate" ;
VAL_ 1173 InfoDyNtDispModeSeltnCurrSetVal 0 "No Action" 1 "Auto" 2 "Day" 3 "Night" ;
VAL_ 1173 PnCEnblReq 0 "Unknown" 1 "No Action" 2 "Enable" 3 "Disable" ;
VAL_ 1893 TrlrProfLifetmEconRstReqd 0 "FALSE" 1 "TRUE" ;
VAL_ 1172 FCASensCstChgSetReq 0 "No Action" 1 "Off" 2 "Low" 3 "Medium" 4 "High" ;
VAL_ 1172 PwrtrnExhPrtclFiltManRegnReq 0 "FALSE" 1 "TRUE" ;
VAL_ 1172 LnDtnWrnSpprssnVirtCtlReq 0 "No Action" 1 "Off" 2 "On" ;
VAL_ 1172 BlndZnStrgAsstVirtCtlReq 0 "No Action" 1 "Off" 2 "On" ;
VAL_ 1172 NtVsnDispThmActv 0 "FALSE" 1 "TRUE" ;
VAL_ 1172 VidAggrgtrSrlzrRestrtReq 0 "FALSE" 1 "TRUE" ;
VAL_ 1894 PTExPrtclFltrMnlRgnDispPrsnt 0 "FALSE" 1 "TRUE" ;
VAL_ 731 PGI4P_ActlAxlTrqSecAuth_Inv 0 "FALSE" 1 "TRUE" ;
VAL_ 1896 IndHtgACSet 0 "Off" 1 "Heat Only" 2 "Air Conditioning Only" ;
VAL_ 1896 SuprRmtPrkAval 0 "Not Available" 1 "Available" ;
VAL_ 1169 Bat12VSysUnstabIndOn 0 "FALSE" 1 "TRUE" ;
VAL_ 1169 DMSDrwIntnDrvrWrnIndReq 0 "No Indication" 1 "Level 1" 2 "Level 2" 3 "Level 3" 4 "Level 4a" 5 "Level 4b" 6 "Level 4c" 7 "Inattentive Alert" 8 "Drowsy Off" 9 "Inattentive Off" 10 "Failed" 11 "Unavailable" ;
VAL_ 1169 PPMShwVehOnExtModeSwReqd 0 "FALSE" 1 "TRUE" ;
VAL_ 1169 DMSTnDrvrDrwIntnOffUnvIndOn 0 "FALSE" 1 "TRUE" ;
VAL_ 1169 DMSDrwDrvrDispLvl 0 "No Indication" 1 "4 bars" 2 "3 bars" 3 "2 bars" 4 "1 bar" 5 "1 bar pulse" ;
VAL_ 1169 DMSDrwDrvrCstCurrSetVal 0 "Setting Unknown" 1 "Off" 2 "Normal" 3 "Low Sensitivity" ;
VAL_ 1169 PPMShwVehEmrgOffSwReqd 0 "FALSE" 1 "TRUE" ;
VAL_ 1169 PPMVehOffPrssBtnAgnSmrtPrmtReqd 0 "FALSE" 1 "TRUE" ;
VAL_ 1169 DMSIntnDrvrCstCurrSetVal 0 "Setting Unknown" 1 "Off" 2 "On" ;
VAL_ 1169 DMSDrwDrvrIndReq 0 "Indicator Off" 1 "White Indicator" 2 "Green Indicator" 3 "Amber Indicator" 4 "Amber Flashing Indicator" 5 "Red Indicator" ;
VAL_ 1169 DMSIntnDrvrDispFcsInd 0 "Unknown" 1 "Off Road" 2 "On Road" ;
VAL_ 1169 DMSIntnDrvrIndReq 0 "Indicator Off" 1 "White Indicator" 2 "Green Indicator" 3 "Amber Indicator" 4 "Amber Flashing Indicator" 5 "Red Indicator" ;
VAL_ 1169 DMSIntnDrvrDispLvl 0 "No Indication" 1 "4 bars" 2 "3 bars" 3 "2 bars" 4 "1 bar" 5 "1 bar pulse" ;
VAL_ 711 GNSSVel01EstVelUncrtnty_DuD 0 "FALSE" 1 "TRUE" ;
VAL_ 711 GNSSVel01EstVel_Inv 0 "FALSE" 1 "TRUE" ;
VAL_ 711 GNSSVel01EstVel_DuD 0 "FALSE" 1 "TRUE" ;
VAL_ 711 GNSSVel01EstVelUncrtnty_Inv 0 "FALSE" 1 "TRUE" ;
VAL_ 711 GNSSVel01NrthVel_Inv 0 "FALSE" 1 "TRUE" ;
VAL_ 711 GNSSVel01NrthVel_DuD 0 "FALSE" 1 "TRUE" ;
VAL_ 711 GNSSVel01NrthVelUncrtnty_Inv 0 "FALSE" 1 "TRUE" ;
VAL_ 711 GNSSVel01NrthVelUncrtnty_DuD 0 "FALSE" 1 "TRUE" ;
VAL_ 712 GNSSVel02UpVelUncrtnty_Inv 0 "FALSE" 1 "TRUE" ;
VAL_ 712 GNSSVel02UpVelUncrtnty_DuD 0 "FALSE" 1 "TRUE" ;
VAL_ 712 GNSSVel02UpVel_Inv 0 "FALSE" 1 "TRUE" ;
VAL_ 712 GNSSVel02UpVel_DuD 0 "FALSE" 1 "TRUE" ;
VAL_ 1897 APALtSftBtnStsIPC 0 "Not Pressed" 1 "Pressed" ;
VAL_ 1897 APALtSftBtnSts 0 "Not Pressed" 1 "Pressed" ;
VAL_ 1897 APAExtPrkSftBtnSts 0 "Not Pressed" 1 "Pressed" ;
VAL_ 1897 APACrssFrntInSftBtnStat 0 "Not Pressed" 1 "Pressed" ;
VAL_ 1897 APACrsBkInSftBtnSts 0 "Not Pressed" 1 "Pressed" ;
VAL_ 1897 APABkBtnSts 0 "No Request" 1 "Back Request" ;
VAL_ 1897 APASuprPrkSts 0 "No Request" 1 "In Vehicle Request" 2 "Supervised Request" ;
VAL_ 1897 APASrchingSftBtnSts 0 "Not Pressed" 1 "Pressed" ;
VAL_ 1897 APARtSftBtnStsIPC 0 "Not Pressed" 1 "Pressed" ;
VAL_ 1897 APARtSftBtnSts 0 "Not Pressed" 1 "Pressed" ;
VAL_ 1897 APAParallelPrkSftBtnSts 0 "Not Pressed" 1 "Pressed" ;
VAL_ 1897 PhnZnEnbl 0 "FALSE" 1 "TRUE" ;
VAL_ 1898 PTOEngRunTmrCstAvlFlg14 0 "FALSE" 1 "TRUE" ;
VAL_ 1898 PTOEngRunTmrCstAvlFlg13 0 "FALSE" 1 "TRUE" ;
VAL_ 1898 PTOEngRunTmrCstAvlFlg12 0 "FALSE" 1 "TRUE" ;
VAL_ 1898 PTOEngRunTmrCstAvlFlg11 0 "FALSE" 1 "TRUE" ;
VAL_ 1898 PTOEngRunTmrCstAvlFlg10 0 "FALSE" 1 "TRUE" ;
VAL_ 1898 PTOEngRunTmrCstAvlFlg1 0 "FALSE" 1 "TRUE" ;
VAL_ 1898 OffBrdVehImbNtfn 0 "No action" 1 "Warning Level 1" 2 "Warning Level 2" 3 "Warning Level 3" ;
VAL_ 1898 PTOEngRunTmrCstAvlFlg8 0 "FALSE" 1 "TRUE" ;
VAL_ 1898 PTOEngRunTmrCstAvlFlg7 0 "FALSE" 1 "TRUE" ;
VAL_ 1898 PTOEngRunTmrCstAvlFlg6 0 "FALSE" 1 "TRUE" ;
VAL_ 1898 PTOEngRunTmrCstAvlFlg5 0 "FALSE" 1 "TRUE" ;
VAL_ 1898 PTOEngRunTmrCstAvlFlg4 0 "FALSE" 1 "TRUE" ;
VAL_ 1898 PTOEngRunTmrCstAvlFlg3 0 "FALSE" 1 "TRUE" ;
VAL_ 1898 PTOEngRunTmrCstAvlFlg2 0 "FALSE" 1 "TRUE" ;
VAL_ 1898 PTOEngRunTmrCstAvlFlg15 0 "FALSE" 1 "TRUE" ;
VAL_ 1898 PTOSet1SpdCstAvlFlg11 0 "FALSE" 1 "TRUE" ;
VAL_ 1898 PTOSet1SpdCstAvlFlg10 0 "FALSE" 1 "TRUE" ;
VAL_ 1898 PTOSet1SpdCstAvlFlg1 0 "FALSE" 1 "TRUE" ;
VAL_ 1898 PTOModeCstAvlFlg2 0 "FALSE" 1 "TRUE" ;
VAL_ 1898 PTOModeCstAvlFlg1 0 "FALSE" 1 "TRUE" ;
VAL_ 1898 PTOEngSpdTypCstAvlFlg2 0 "FALSE" 1 "TRUE" ;
VAL_ 1898 PTOEngSpdTypCstAvlFlg1 0 "FALSE" 1 "TRUE" ;
VAL_ 1898 PTOEngRunTmrCstAvlFlg9 0 "FALSE" 1 "TRUE" ;
VAL_ 1898 PTOSet1SpdCstAvlFlg5 0 "FALSE" 1 "TRUE" ;
VAL_ 1898 PTOSet1SpdCstAvlFlg4 0 "FALSE" 1 "TRUE" ;
VAL_ 1898 PTOSet1SpdCstAvlFlg3 0 "FALSE" 1 "TRUE" ;
VAL_ 1898 PTOSet1SpdCstAvlFlg2 0 "FALSE" 1 "TRUE" ;
VAL_ 1898 PTOSet1SpdCstAvlFlg15 0 "FALSE" 1 "TRUE" ;
VAL_ 1898 PTOSet1SpdCstAvlFlg14 0 "FALSE" 1 "TRUE" ;
VAL_ 1898 PTOSet1SpdCstAvlFlg13 0 "FALSE" 1 "TRUE" ;
VAL_ 1898 PTOSet1SpdCstAvlFlg12 0 "FALSE" 1 "TRUE" ;
VAL_ 1898 PTOSet2SpdCstAvlFlg12 0 "FALSE" 1 "TRUE" ;
VAL_ 1898 PTOSet2SpdCstAvlFlg11 0 "FALSE" 1 "TRUE" ;
VAL_ 1898 PTOSet2SpdCstAvlFlg10 0 "FALSE" 1 "TRUE" ;
VAL_ 1898 PTOSet2SpdCstAvlFlg1 0 "FALSE" 1 "TRUE" ;
VAL_ 1898 PTOSet1SpdCstAvlFlg9 0 "FALSE" 1 "TRUE" ;
VAL_ 1898 PTOSet1SpdCstAvlFlg8 0 "FALSE" 1 "TRUE" ;
VAL_ 1898 PTOSet1SpdCstAvlFlg7 0 "FALSE" 1 "TRUE" ;
VAL_ 1898 PTOSet1SpdCstAvlFlg6 0 "FALSE" 1 "TRUE" ;
VAL_ 1898 PTOSet2SpdCstAvlFlg6 0 "FALSE" 1 "TRUE" ;
VAL_ 1898 PTOSet2SpdCstAvlFlg5 0 "FALSE" 1 "TRUE" ;
VAL_ 1898 PTOSet2SpdCstAvlFlg4 0 "FALSE" 1 "TRUE" ;
VAL_ 1898 PTOSet2SpdCstAvlFlg3 0 "FALSE" 1 "TRUE" ;
VAL_ 1898 PTOSet2SpdCstAvlFlg2 0 "FALSE" 1 "TRUE" ;
VAL_ 1898 PTOSet2SpdCstAvlFlg15 0 "FALSE" 1 "TRUE" ;
VAL_ 1898 PTOSet2SpdCstAvlFlg14 0 "FALSE" 1 "TRUE" ;
VAL_ 1898 PTOSet2SpdCstAvlFlg13 0 "FALSE" 1 "TRUE" ;
VAL_ 1898 PTOStndbySpdCstAvlFlg5 0 "FALSE" 1 "TRUE" ;
VAL_ 1898 PTOStndbySpdCstAvlFlg4 0 "FALSE" 1 "TRUE" ;
VAL_ 1898 PTOStndbySpdCstAvlFlg3 0 "FALSE" 1 "TRUE" ;
VAL_ 1898 PTOStndbySpdCstAvlFlg2 0 "FALSE" 1 "TRUE" ;
VAL_ 1898 PTOStndbySpdCstAvlFlg1 0 "FALSE" 1 "TRUE" ;
VAL_ 1898 PTOSet2SpdCstAvlFlg9 0 "FALSE" 1 "TRUE" ;
VAL_ 1898 PTOSet2SpdCstAvlFlg8 0 "FALSE" 1 "TRUE" ;
VAL_ 1898 PTOSet2SpdCstAvlFlg7 0 "FALSE" 1 "TRUE" ;
VAL_ 1898 PTOTpStpSpdCstAvlFlg6 0 "FALSE" 1 "TRUE" ;
VAL_ 1898 PTOTpStpSpdCstAvlFlg5 0 "FALSE" 1 "TRUE" ;
VAL_ 1898 PTOTpStpSpdCstAvlFlg4 0 "FALSE" 1 "TRUE" ;
VAL_ 1898 PTOTpStpSpdCstAvlFlg3 0 "FALSE" 1 "TRUE" ;
VAL_ 1898 PTOTpStpSpdCstAvlFlg2 0 "FALSE" 1 "TRUE" ;
VAL_ 1898 PTOTpStpSpdCstAvlFlg1 0 "FALSE" 1 "TRUE" ;
VAL_ 1898 PTOStndbySpdCstAvlFlg7 0 "FALSE" 1 "TRUE" ;
VAL_ 1898 PTOStndbySpdCstAvlFlg6 0 "FALSE" 1 "TRUE" ;
VAL_ 1167 PTOTpStpSpdCstAvlFlg7 0 "FALSE" 1 "TRUE" ;
VAL_ 1167 VehColdBatPerfIndOn 0 "FALSE" 1 "TRUE" ;
VAL_ 1167 ActvRrSplrVirtUserCtlAllwd 0 "Allowed" 1 "Not Allowed" ;
VAL_ 1167 ActvRrSplrVirtCtlAval 0 "Not Available" 1 "Available" ;
VAL_ 1167 ActvRrSplrVirtCtlCurrSeltnVal 0 "Unknown" 1 "No Indication" 2 "Stowed" 3 "Stowing" 4 "Deployed" 5 "Deploying" 6 "Obstruction Detected" ;
VAL_ 1899 TrlrJckKnfAlrtSts 0 "Unknown" 1 "No Alert Active" 2 "Phase 1 Alert Active" 3 "Phase 2 Alert Active" ;
VAL_ 1900 VirtCtlHtdVntStSwRrAval 0 "Not Available" 1 "Available" ;
VAL_ 1900 VirtCtlHtdVntStSwFrtAval 0 "Not Available" 1 "Available" ;
VAL_ 1165 InfoOffRdAppInfltDfltAsstEnbld 0 "FALSE" 1 "TRUE" ;
VAL_ 1165 UpftrSnwPlwIndReq 0 "No Indication" 1 "Active" 2 "Active with Headlamps Disabled" 3 "Not Available" ;
VAL_ 1165 UpftrRrAprchPrtctnIndReq 0 "No Indication" 1 "Armed" 2 "Deactivated" 3 "Triggered" 4 "Not Available" ;
VAL_ 1165 LifetmEleclEngyEcon_DuD 0 "FALSE" 1 "TRUE" ;
VAL_ 1165 ChrgCycEleclEngyUsd_DuD 0 "FALSE" 1 "TRUE" ;
VAL_ 1165 UpftrRadioMutReqd 0 "FALSE" 1 "TRUE" ;
VAL_ 1165 UpftrBkupCamActvnReqd 0 "FALSE" 1 "TRUE" ;
VAL_ 1165 AutoHiBmSmrtIconReqd 0 "FALSE" 1 "TRUE" ;
VAL_ 1165 RIMUnvTlgtIndOn 0 "FALSE" 1 "TRUE" ;
VAL_ 1165 PnCBkOfcDatTrgrd 0 "FALSE" 1 "TRUE" ;
VAL_ 1165 TransOilFiltChgIndOn 0 "FALSE" 1 "TRUE" ;
VAL_ 1901 InfoOffRdAppInfltDfltAsstReqd 0 "FALSE" 1 "TRUE" ;
VAL_ 194 VwgVwprtStsExtd 0 "Unknown" 1 "No Request" 2 "Underbody Forward" 3 "Underbody Rearward" 4 "Underbody Forward Split" 5 "Underbody Forward Rearward Split" ;
VAL_ 194 VwgVwprtReqExtd 0 "Unknown" 1 "No Request" 2 "Underbody Forward" 3 "Underbody Rearward" 4 "Underbody Forward Split" 5 "Underbody Forward Rearward Split" ;
VAL_ 194 VwgCtlBtnAvlUndrbdyRrwdActv 0 "FALSE" 1 "TRUE" ;
VAL_ 194 VwgCtlBtnAvlUndrbdyFrwdActv 0 "FALSE" 1 "TRUE" ;
VAL_ 192 VwgVwprtSeltnExtd 0 "Unknown" 1 "No Request" 2 "Underbody Forward" 3 "Underbody Rearward" 4 "Underbody Forward Split" 5 "Underbody Forward Rearward Split" ;
VAL_ 112 AtTrnsGrSftDrct 0 "No Shift in Progress" 1 "Upshift in Progress" 2 "Downshift in Progress" ;
VAL_ 1164 PPMShwVehOffSwRedntReqd 0 "FALSE" 1 "TRUE" ;
VAL_ 1164 CBIP_ClsnImntBrkgStsAuth 0 "Not Active" 1 "Active" 2 "Failed" ;
VAL_ 1164 HVBatSOCDspHdlmpCstCurrSetVal 0 "Setting Unknown" 1 "Off" 2 "On" ;
VAL_ 1164 ElecShfPriLoManSeltnIndReq 0 "No Indication" 1 "Low" 2 "Manual" ;
VAL_ 1164 VirtCtlPrvcySwAllwd 0 "FALSE" 1 "TRUE" ;
VAL_ 1164 VirtCtlBkGlsShdCtlRrAllwd 0 "FALSE" 1 "TRUE" ;
VAL_ 1164 VirtCtlBkGlsShdCtlFrtAllwd 0 "FALSE" 1 "TRUE" ;
VAL_ 1164 ActvRollCtlRrWrnIndReq 0 "No Indication" 1 "No Impact Derating" 2 "Service" ;
VAL_ 1164 ActvRollCtlFrtWrnIndReq 0 "No Indication" 1 "No Impact Derating" 2 "Service" ;
VAL_ 1164 PPMShwVehOffSwMnReqd 0 "FALSE" 1 "TRUE" ;
VAL_ 1164 ActvRrSplrWrnIndReq 0 "No Indication" 1 "Obstruction" 2 "Temporarily Disabled" 3 "Service" ;
VAL_ 1163 ICMCstSelCstSetAval 0 "FALSE" 1 "TRUE" ;
VAL_ 1163 ICMCstAvlFlg7 0 "FALSE" 1 "TRUE" ;
VAL_ 1163 ICMCstAvlFlg6 0 "FALSE" 1 "TRUE" ;
VAL_ 1163 ICMCstAvlFlg5 0 "FALSE" 1 "TRUE" ;
VAL_ 1163 ICMCstAvlFlg4 0 "FALSE" 1 "TRUE" ;
VAL_ 1163 ICMCstAvlFlg3 0 "FALSE" 1 "TRUE" ;
VAL_ 1163 ICMCstAvlFlg2 0 "FALSE" 1 "TRUE" ;
VAL_ 1163 ICMCstAvlFlg1 0 "FALSE" 1 "TRUE" ;
VAL_ 1163 ICMCstSelCstCurSetVal 0 "Setting Unknown" 1 "Off" 2 "Alert" 3 "Alert Brake" 4 "Alert Brake Steer" ;
VAL_ 1903 InfoThmSeltnCurrSetVal 0 "Unknown" 1 "None" 2 "Theme 1" 3 "Theme 2" 4 "Theme 3" 5 "Theme 4" 6 "Theme 5" 7 "Theme 6" 8 "Theme 7" 9 "Theme 8" 10 "Theme 9" 11 "Theme 10" 12 "Theme 11" 13 "Theme 12" 14 "Theme 13" 15 "Theme 14" ;
VAL_ 1903 ICMCstChgSetReq 0 "No Action" 1 "Off" 2 "Alert" 3 "Alert Brake" 4 "Alert Brake Steer" ;
VAL_ 1903 ActvRrSplrVirtCtlReq 0 "No Action" 1 "Stow" 2 "Deploy" ;
VAL_ 1161 VirtCkptDispTchFlg2 0 "FALSE" 1 "TRUE" ;
VAL_ 1161 VirtCkptDispTchFlg1 0 "FALSE" 1 "TRUE" ;
VAL_ 1161 SRPSptSeltnRmtSftBtnSts 0 "Not Pressed" 1 "Pressed" ;
VAL_ 1161 SRPSptSeltnKeepLkSftBtnSts 0 "Not Pressed" 1 "Pressed" ;
VAL_ 1161 SRPSptSeltnAcceptSftBtnSts 0 "Not Pressed" 1 "Pressed" ;
VAL_ 1161 SuprRmtPrkDctvSoftBtnSts 0 "Not Pressed" 1 "Pressed" ;
VAL_ 1905 VirtCkptDispTchFlg4 0 "FALSE" 1 "TRUE" ;
VAL_ 1905 VirtCkptDispTchFlg3 0 "FALSE" 1 "TRUE" ;
VAL_ 1905 SRPUnableCnctExtSftBtnSts 0 "Not Pressed" 1 "Pressed" ;
VAL_ 1905 SRPUnableCnctTryAgnSftBtnSts 0 "Not Pressed" 1 "Pressed" ;
VAL_ 1162 HiVltgSysFltIndOn 0 "FALSE" 1 "TRUE" ;
VAL_ 1162 HiVltgChrgLtdRsn 0 "No Action" 1 "High Voltage System Fault" 2 "Low Voltage System Fault" 3 "Temperature Out of Bounds" 4 "State of Charge Out of Bounds" 5 "Temporary Limiting Condition" 6 "Utility Power Override" 7 "HVAC System Limiting" 8 "Station Power Limiting" 9 "Normal Derate State of Charge" 10 "Normal Derate Temperature Threshold" 11 "Coupler Lock Not Engaged" ;
VAL_ 1162 PrplDispExtndCpbltyLvlPct_DuD 0 "FALSE" 1 "TRUE" ;
VAL_ 1162 PrplDispExtndPwrLvlPct_DuD 0 "FALSE" 1 "TRUE" ;
VAL_ 1162 InfoWndMtnCtlRRAllwd 0 "FALSE" 1 "TRUE" ;
VAL_ 1162 InfoWndMtnCtlRFAllwd 0 "FALSE" 1 "TRUE" ;
VAL_ 1162 InfoWndMtnCtlLRAllwd 0 "FALSE" 1 "TRUE" ;
VAL_ 1162 InfoWndMtnCtlLFAllwd 0 "FALSE" 1 "TRUE" ;
VAL_ 1162 InfoSnrfMtnCtlAllwd 0 "FALSE" 1 "TRUE" ;
VAL_ 1162 InfoFrtSnshdMtnCtlAllwd 0 "FALSE" 1 "TRUE" ;
VAL_ 1162 FrtSnshdPstnStsInfo 0 "Fully Closed" 1 "Partially Open" 2 "Fully Open" 3 "Comfort Open" ;
VAL_ 1162 PwrlineCommCtlPilotDC_Inv 0 "FALSE" 1 "TRUE" ;
VAL_ 1162 HiVltgCouplerPrxmtySts_Inv 0 "FALSE" 1 "TRUE" ;
VAL_ 1162 HiVltgCouplerPrxmtySts 0 "Unknown" 1 "Disconnected" 2 "Connected" ;
VAL_ 1160 DMSDrwDrvrCstChgSetReq 0 "No Action" 1 "Off" 2 "Normal" 3 "Low Sensitivity" ;
VAL_ 1906 NavRteChgOcc 0 "FALSE" 1 "TRUE" ;
VAL_ 1906 NavRteSts 0 "No Action" 1 "Inactive" 2 "Active" 3 "Predicted" 4 "Learned" ;
VAL_ 1158 NextChrgDestSts 0 "No Action" 1 "Charge Not Planned" 2 "Charge Planned" 3 "Charge Location Reached" ;
VAL_ 1908 PnCActnStsCertfctTyp 0 "None" 1 "GM Provisioning Certificate" 2 "Contract Certificate" 3 "V2G Root Certificate" 4 "OCSP Certificate" 5 "Private Operator Root Certificate" 6 "Reserved1" 7 "Reserved2" 8 "Reserved3" 9 "Reserved4" 10 "Reserved5" 11 "Reserved6" 12 "Reserved7" 13 "Reserved8" 14 "All Contract And Private Operator Root Certificates" ;
VAL_ 1908 PnCActnStsCertfctOpSts 0 "NoAction" 1 "CertificateDisabledSuccessfully" 2 "CertificateDisableFailed" 3 "CertificateEnabledSuccessfully" 4 "CertificateEnableFailed" 5 "CertificateErasedSuccessfully" 6 "CertificateErasureFailed" 7 "CertificateDisableOperationInProgress" 8 "CertificateEnableOperationInProgress" 9 "CertificateEraseOperationInProgress" 10 "SelectedCertificateOperationLocationisOutofBounds" 11 "NoCertificateisInstalledintheRequestedCertificateLocation" 12 "NoCertificateofThisCertificateTypeisInstalledintheEVCC" 13 "CertificateOperationNotSupportedonThisCertificateType" 14 "CertificateOperationCannotbePerformedatThisTime" 15 "CertificateInstallOperationInProgress" 16 "CertificateInstalledSuccessfully" 17 "CertificateInstallFailed" ;
VAL_ 1908 ElecVehAllWhlDrvUnvWrnIndReq 0 "No Indication" 1 "Temporarily Unavailable" 2 "Faulted" ;
VAL_ 1908 ElecVehAllWhlDrvUnvIndReq 0 "No Indication" 1 "Limited" 2 "Faulted" ;
VAL_ 1157 FAXVCLoPrtyFltChmEvntStat 0 "No Action" 1 "Active" 2 "Cancel Chime" ;
VAL_ 1157 FAXVCInCtlChmEvntStat 0 "No Action" 1 "Active" 2 "Cancel Chime" ;
VAL_ 1157 FAXVCHiPrtyFltChmEvntStat 0 "No Action" 1 "Active" 2 "Cancel Chime" ;
VAL_ 1157 AutoCtlrGnrcChmEvntStat 0 "No Action" 1 "Active" 2 "Cancel Chime" ;
VAL_ 1157 VehNDtctgFAXVCErrChmEvntStat 0 "No Action" 1 "Active" 2 "Cancel Chime" ;
VAL_ 1157 VehExtdFAXVCModeChmEvntStat 0 "No Action" 1 "Active" 2 "Cancel Chime" ;
VAL_ 1157 FAXVCSevPrtyFltChmEvntStat 0 "No Action" 1 "Active" 2 "Cancel Chime" ;
VAL_ 1157 FAXVCMedPrtyFltChmEvntStat 0 "No Action" 1 "Active" 2 "Cancel Chime" ;
VAL_ 1157 IndHtdArmrstLvlRrRt 0 "Off" 1 "1" 2 "2" 3 "3" 4 "Linked" ;
VAL_ 1157 UpftrRrAprchPrtctnChmEvntStat 0 "No Action" 1 "Active" 2 "Cancel Chime" ;
VAL_ 1157 DMSIntnDrvrCstAvlFlg1 0 "FALSE" 1 "TRUE" ;
VAL_ 1157 DMSDrwIntnDrvrDtnAlrtMutReqd 0 "FALSE" 1 "TRUE" ;
VAL_ 1157 DMSDrwIntnDrvrLvl1ChmEvntStat 0 "No Action" 1 "Active" 2 "Cancel Chime" ;
VAL_ 1157 DMSDrwIntnDrvrLvl2ChmEvntStat 0 "No Action" 1 "Active" 2 "Cancel Chime" ;
VAL_ 1157 DMSIntnDrvrCstSetAval 0 "FALSE" 1 "TRUE" ;
VAL_ 1157 DMSIntnDrvrCstAvlFlg7 0 "FALSE" 1 "TRUE" ;
VAL_ 1157 DMSIntnDrvrCstAvlFlg6 0 "FALSE" 1 "TRUE" ;
VAL_ 1157 DMSIntnDrvrCstAvlFlg5 0 "FALSE" 1 "TRUE" ;
VAL_ 1157 DMSIntnDrvrCstAvlFlg4 0 "FALSE" 1 "TRUE" ;
VAL_ 1157 DMSIntnDrvrCstAvlFlg3 0 "FALSE" 1 "TRUE" ;
VAL_ 1157 DMSIntnDrvrCstAvlFlg2 0 "FALSE" 1 "TRUE" ;
VAL_ 1155 HVBatSOCDspHdlmpCstAvlFlg1 0 "FALSE" 1 "TRUE" ;
VAL_ 1155 InfoWndMtnCtlRRAval 0 "Not Available" 1 "Available" ;
VAL_ 1155 InfoWndMtnCtlRFAval 0 "Not Available" 1 "Available" ;
VAL_ 1155 InfoWndMtnCtlLRAval 0 "Not Available" 1 "Available" ;
VAL_ 1155 InfoWndMtnCtlLFAval 0 "Not Available" 1 "Available" ;
VAL_ 1155 InfoSnrfMtnCtlAval 0 "Not Available" 1 "Available" ;
VAL_ 1155 VirtCtlIntrCmptRelCtlAval 0 "Not Available" 1 "Available" ;
VAL_ 1155 Aux1AmbtColrCtlCstAvlFlg100 0 "FALSE" 1 "TRUE" ;
VAL_ 1155 HVBatSOCDspHdlmpCstSetAval 0 "FALSE" 1 "TRUE" ;
VAL_ 1155 HVBatSOCDspHdlmpCstAvlFlg7 0 "FALSE" 1 "TRUE" ;
VAL_ 1155 HVBatSOCDspHdlmpCstAvlFlg6 0 "FALSE" 1 "TRUE" ;
VAL_ 1155 HVBatSOCDspHdlmpCstAvlFlg5 0 "FALSE" 1 "TRUE" ;
VAL_ 1155 HVBatSOCDspHdlmpCstAvlFlg4 0 "FALSE" 1 "TRUE" ;
VAL_ 1155 HVBatSOCDspHdlmpCstAvlFlg3 0 "FALSE" 1 "TRUE" ;
VAL_ 1155 HVBatSOCDspHdlmpCstAvlFlg2 0 "FALSE" 1 "TRUE" ;
VAL_ 1155 Aux1AmbtColrCtlCstAvlFlg108 0 "FALSE" 1 "TRUE" ;
VAL_ 1155 Aux1AmbtColrCtlCstAvlFlg107 0 "FALSE" 1 "TRUE" ;
VAL_ 1155 Aux1AmbtColrCtlCstAvlFlg106 0 "FALSE" 1 "TRUE" ;
VAL_ 1155 Aux1AmbtColrCtlCstAvlFlg105 0 "FALSE" 1 "TRUE" ;
VAL_ 1155 Aux1AmbtColrCtlCstAvlFlg104 0 "FALSE" 1 "TRUE" ;
VAL_ 1155 Aux1AmbtColrCtlCstAvlFlg103 0 "FALSE" 1 "TRUE" ;
VAL_ 1155 Aux1AmbtColrCtlCstAvlFlg102 0 "FALSE" 1 "TRUE" ;
VAL_ 1155 Aux1AmbtColrCtlCstAvlFlg101 0 "FALSE" 1 "TRUE" ;
VAL_ 1155 Aux1AmbtColrCtlCstAvlFlg116 0 "FALSE" 1 "TRUE" ;
VAL_ 1155 Aux1AmbtColrCtlCstAvlFlg115 0 "FALSE" 1 "TRUE" ;
VAL_ 1155 Aux1AmbtColrCtlCstAvlFlg114 0 "FALSE" 1 "TRUE" ;
VAL_ 1155 Aux1AmbtColrCtlCstAvlFlg113 0 "FALSE" 1 "TRUE" ;
VAL_ 1155 Aux1AmbtColrCtlCstAvlFlg112 0 "FALSE" 1 "TRUE" ;
VAL_ 1155 Aux1AmbtColrCtlCstAvlFlg111 0 "FALSE" 1 "TRUE" ;
VAL_ 1155 Aux1AmbtColrCtlCstAvlFlg110 0 "FALSE" 1 "TRUE" ;
VAL_ 1155 Aux1AmbtColrCtlCstAvlFlg109 0 "FALSE" 1 "TRUE" ;
VAL_ 1155 Aux1AmbtColrCtlCstAvlFlg124 0 "FALSE" 1 "TRUE" ;
VAL_ 1155 Aux1AmbtColrCtlCstAvlFlg123 0 "FALSE" 1 "TRUE" ;
VAL_ 1155 Aux1AmbtColrCtlCstAvlFlg122 0 "FALSE" 1 "TRUE" ;
VAL_ 1155 Aux1AmbtColrCtlCstAvlFlg121 0 "FALSE" 1 "TRUE" ;
VAL_ 1155 Aux1AmbtColrCtlCstAvlFlg120 0 "FALSE" 1 "TRUE" ;
VAL_ 1155 Aux1AmbtColrCtlCstAvlFlg119 0 "FALSE" 1 "TRUE" ;
VAL_ 1155 Aux1AmbtColrCtlCstAvlFlg118 0 "FALSE" 1 "TRUE" ;
VAL_ 1155 Aux1AmbtColrCtlCstAvlFlg117 0 "FALSE" 1 "TRUE" ;
VAL_ 1155 Aux1AmbtColrCtlCstAvlFlg99 0 "FALSE" 1 "TRUE" ;
VAL_ 1155 Aux1AmbtColrCtlCstAvlFlg98 0 "FALSE" 1 "TRUE" ;
VAL_ 1155 Aux1AmbtColrCtlCstAvlFlg97 0 "FALSE" 1 "TRUE" ;
VAL_ 1155 Aux1AmbtColrCtlCstAvlFlg96 0 "FALSE" 1 "TRUE" ;
VAL_ 1155 Aux1AmbtColrCtlCstAvlFlg95 0 "FALSE" 1 "TRUE" ;
VAL_ 1155 Aux1AmbtColrCtlCstAvlFlg127 0 "FALSE" 1 "TRUE" ;
VAL_ 1155 Aux1AmbtColrCtlCstAvlFlg126 0 "FALSE" 1 "TRUE" ;
VAL_ 1155 Aux1AmbtColrCtlCstAvlFlg125 0 "FALSE" 1 "TRUE" ;
VAL_ 1911 VirtCtlIntrCmptRelReqd 0 "FALSE" 1 "TRUE" ;
VAL_ 1911 RrCtlDispFltIndOn 0 "FALSE" 1 "TRUE" ;
